VERSION ""

NS_ :

BS_:

BU_: Turbocharger OnBoardDataLogger OffBoardDiagnosticTool2 OffBoardDiagnosticTool1 FileServer ParkingBrakeController SeatControl2 FanDriveController SteeringColumnUnit CommunicationUnitRadio CommunicationUnitSatellite CommunicationUnitCellular PropulsionBatteryCharger ChassisController2 ChassisController1 EngineValveControl AuxiliaryHeater2 AuxiliaryHeater1 ClutchUnit RampControl InformationSystem1 SuspensionSystemController2 OilSensor VehicleDynamicStability ExhaustEmissionController TransmissionDisplay2 TransmissionDisplay1 ClimateControl2 WaterPumpController RearAxleSteeringController LightingOperatorControl SeatController1 IgnitionController2 IgnitionController1 TirePressureController CabController2 CabController1 PneumaticSystemController SuspensionSystemController1 HydraulicPumpController EnduranceBrakingSystem RetarderExhaustEngine2 OnBoardDiagnosticUnit HeadwayController RetarderExhaustEngine1 CabDisplay1 ManagementComputer VirtualTerminal OffVehicleGateway PowerTakeOffFront HitchControl AuxiliaryValveControl BodyController TractorTrailerBridge1 StarterSystem ElectricalSystem VehicleSecurity VehicleNavigation AerodynamicControl ElectricalChargingSystem ClimateControl1 TripRecorder InstrumentCluster SuspensionDriveAxle2 SuspensionDriveAxle1 SuspensionSteerAxle SteeringController FuelSystem CruiseControl RetarderDriveline RetarderEngine BrakesDriveAxle2 BrakesDriveAxle1 BrakesSystemController BrakesSteerAxle AxleDrive2 AxleDrive1 AxleSteering PowerTakeOff ShiftConsoleSecondary ShiftConsolePrimary Transmission2 Transmission1 Engine2 Engine1

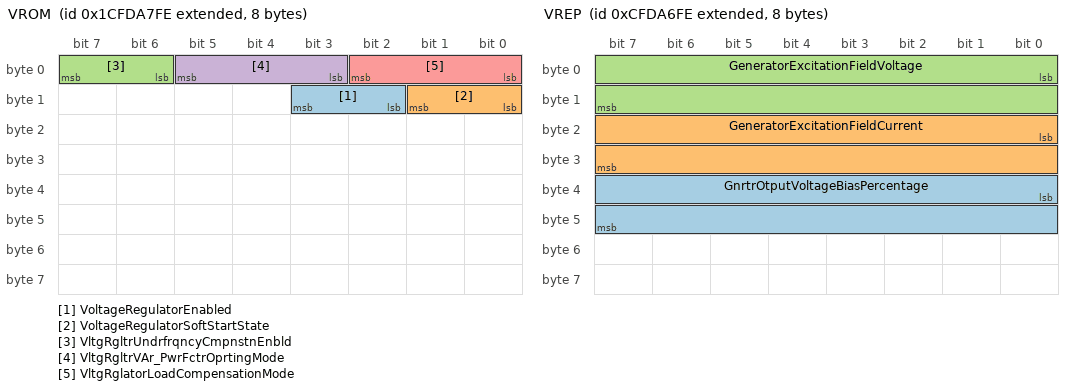
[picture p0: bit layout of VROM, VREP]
BO_ 2633869310 VROM: 8 Vector__XXX
 SG_ VoltageRegulatorEnabled : 10|2@1+ (1,0) [0|3] "" Vector__XXX
 SG_ VoltageRegulatorSoftStartState : 8|2@1+ (1,0) [0|3] "" Vector__XXX
 SG_ VltgRgltrUndrfrqncyCmpnstnEnbld : 6|2@1+ (1,0) [0|3] "" Vector__XXX
 SG_ VltgRgltrVAr_PwrFctrOprtingMode : 3|3@1+ (1,0) [0|7] "" Vector__XXX
 SG_ VltgRglatorLoadCompensationMode : 0|3@1+ (1,0) [0|7] "" Vector__XXX

BO_ 2365433598 VREP: 8 Vector__XXX
 SG_ GnrtrOtputVoltageBiasPercentage : 32|16@1+ (0.1,-100) [-100|100] "%" Vector__XXX
 SG_ GeneratorExcitationFieldCurrent : 16|16@1+ (0.05,0) [0|3217.5] "A" Vector__XXX
 SG_ GeneratorExcitationFieldVoltage : 0|16@1+ (0.05,-1605.625) [-1605.625|1606.375] "V" Vector__XXX

CM_ BO_ 3221225472 "This is a message for not used signals, created by Vector CANdb++ DBC OLE DB Provider.";
CM_ SG_ 3221225472 TrailerWeight "Total mass of freight-carrying vehicle designed to be pulled by truck, including the weight of the contents.";
CM_ SG_ 3221225472 ReferenceTirePressSetting "Reference value of the tire pressure setting as basis for the tire pressure monitoring";
CM_ SG_ 3221225472 ReferenceTirePress "Reference value of the tire pressure as basis for the tire pressure monitoring";
CM_ SG_ 3221225472 TirePressThresholdDetection "Signal indicating the pressure level of the tire.";
CM_ SG_ 3221225472 TireAirLeakageRate "The pressure loss rate of a tire.";
CM_ SG_ 3221225472 CTIWheelEndElectricalFault "Indicates the status of electrical fault on CTI wheel interface.";
CM_ SG_ 3221225472 CTITireStatus "Indicates the status of the tire.";
CM_ SG_ 3221225472 CTIWheelSensorStatus "Indicates whether the wheel is being monitored by the CTI controller.";
CM_ SG_ 3221225472 TireTemp "Temperature at the surface of the tire sidewall.";
CM_ SG_ 3221225472 TirePress "Pressure at which air is contained in cavity formed by tire and rim.";
CM_ BO_ 2633832958 "Ignitor Loop Information";
CM_ SG_ 2633832958 SpecialIgnitorLoop90Resistance "Resistance of Special Ignitor Loop 90.";
CM_ SG_ 2633832958 SpecialIgnitorLoop89Resistance "Resistance of Special Ignitor Loop 89.";
CM_ SG_ 2633832958 SpecialIgnitorLoop88Resistance "Resistance of Special Ignitor Loop 88.";
CM_ SG_ 2633832958 SpecialIgnitorLoop87Resistance "Resistance of Special Ignitor Loop 87.";
CM_ SG_ 2633832958 SpecialIgnitorLoop86Resistance "Resistance of Special Ignitor Loop 86.";
CM_ SG_ 2633832958 SpecialIgnitorLoop85Resistance "Resistance of Special Ignitor Loop 85.";
CM_ SG_ 2633832958 SpecialIgnitorLoop84Resistance "Resistance of Special Ignitor Loop 84.";
CM_ SG_ 2633832958 SpecialIgnitorLoop83Resistance "Resistance of Special Ignitor Loop 83.";
CM_ SG_ 2633832958 SpecialIgnitorLoop82Resistance "Resistance of Special Ignitor Loop 82.";
CM_ SG_ 2633832958 SpecialIgnitorLoop81Resistance "Resistance of Special Ignitor Loop 81.";
CM_ SG_ 2633832958 SpecialIgnitorLoop80Resistance "Resistance of Special Ignitor Loop 80.";
CM_ SG_ 2633832958 SpecialIgnitorLoop79Resistance "Resistance of Special Ignitor Loop 79.";
CM_ SG_ 2633832958 SpecialIgnitorLoop78Resistance "Resistance of Special Ignitor Loop 78.";
CM_ SG_ 2633832958 SpecialIgnitorLoop77Resistance "Resistance of Special Ignitor Loop 77.";
CM_ SG_ 2633832958 SpecialIgnitorLoop76Resistance "Resistance of Special Ignitor Loop 76.";
CM_ SG_ 2633832958 SpecialIgnitorLoop75Resistance "Resistance of Special Ignitor Loop 75.";
CM_ SG_ 2633832958 SpecialIgnitorLoop74Resistance "Resistance of Special Ignitor Loop 74.";
CM_ SG_ 2633832958 SpecialIgnitorLoop73Resistance "Resistance of Special Ignitor Loop 73.";
CM_ SG_ 2633832958 SpecialIgnitorLoop72Resistance "Resistance of Special Ignitor Loop 72.";
CM_ SG_ 2633832958 SpecialIgnitorLoop71Resistance "Resistance of Special Ignitor Loop 71.";
CM_ SG_ 2633832958 SpecialIgnitorLoop70Resistance "Resistance of Special Ignitor Loop 70.";
CM_ SG_ 2633832958 SpecialIgnitorLoop69Resistance "Resistance of Special Ignitor Loop 69.";
CM_ SG_ 2633832958 SpecialIgnitorLoop68Resistance "Resistance of Special Ignitor Loop 68.";
CM_ SG_ 2633832958 SpecialIgnitorLoop67Resistance "Resistance of Special Ignitor Loop 67.";
CM_ SG_ 2633832958 SpecialIgnitorLoop66Resistance "Resistance of Special Ignitor Loop 66.";
CM_ SG_ 2633832958 SpecialIgnitorLoop65Resistance "Resistance of Special Ignitor Loop 65.";
CM_ SG_ 2633832958 SpecialIgnitorLoop64Resistance "Resistance of Special Ignitor Loop 64.";
CM_ SG_ 2633832958 SpecialIgnitorLoop63Resistance "Resistance of Special Ignitor Loop 63.";
CM_ SG_ 2633832958 SpecialIgnitorLoop61Resistance "Resistance of Special Ignitor Loop 61.";
CM_ SG_ 2633832958 SpecialIgnitorLoop60Resistance "Resistance of Special Ignitor Loop 60.";
CM_ SG_ 2633832958 SpecialIgnitorLoop59Resistance "Resistance of Special Ignitor Loop 59.";
CM_ SG_ 2633832958 SpecialIgnitorLoop58Resistance "Resistance of Special Ignitor Loop 58.";
CM_ SG_ 2633832958 SpecialIgnitorLoop57Resistance "Resistance of Special Ignitor Loop 57.";
CM_ SG_ 2633832958 SpecialIgnitorLoop56Resistance "Resistance of Special Ignitor Loop 56.";
CM_ SG_ 2633832958 SpecialIgnitorLoop55Resistance "Resistance of Special Ignitor Loop 55.";
CM_ SG_ 2633832958 SpecialIgnitorLoop54Resistance "Resistance of Special Ignitor Loop 54.";
CM_ SG_ 2633832958 SpecialIgnitorLoop53Resistance "Resistance of Special Ignitor Loop 53.";
CM_ SG_ 2633832958 SpecialIgnitorLoop52Resistance "Resistance of Special Ignitor Loop 52.";
CM_ SG_ 2633832958 SpecialIgnitorLoop51Resistance "Resistance of Special Ignitor Loop 51.";
CM_ SG_ 2633832958 SpecialIgnitorLoop50Resistance "Resistance of Special Ignitor Loop 50.";
CM_ SG_ 2633832958 SpecialIgnitorLoop49Resistance "Resistance of Special Ignitor Loop 49.";
CM_ SG_ 2633832958 SpecialIgnitorLoop48Resistance "Resistance of Special Ignitor Loop 48.";
CM_ SG_ 2633832958 SpecialIgnitorLoop47Resistance "Resistance of Special Ignitor Loop 47.";
CM_ SG_ 2633832958 SpecialIgnitorLoop46Resistance "Resistance of Special Ignitor Loop 46.";
CM_ SG_ 2633832958 SpecialIgnitorLoop45Resistance "Resistance of Special Ignitor Loop 45.";
CM_ SG_ 2633832958 SpecialIgnitorLoop44Resistance "Resistance of Special Ignitor Loop 44.";
CM_ SG_ 2633832958 SpecialIgnitorLoop43Resistance "Resistance of Special Ignitor Loop 43.";
CM_ SG_ 2633832958 SpecialIgnitorLoop42Resistance "Resistance of Special Ignitor Loop 42.";
CM_ SG_ 2633832958 SpecialIgnitorLoop41Resistance "Resistance of Special Ignitor Loop 41.";
CM_ SG_ 2633832958 SpecialIgnitorLoop40Resistance "Resistance of Special Ignitor Loop 40.";
CM_ SG_ 2633832958 SpecialIgnitorLoop39Resistance "Resistance of Special Ignitor Loop 39.";
CM_ SG_ 2633832958 SpecialIgnitorLoop38Resistance "Resistance of Special Ignitor Loop 38.";
CM_ SG_ 2633832958 SpecialIgnitorLoop37Resistance "Resistance of Special Ignitor Loop 37.";
CM_ SG_ 2633832958 SpecialIgnitorLoop36Resistance "Resistance of Special Ignitor Loop 36.";
CM_ SG_ 2633832958 SpecialIgnitorLoop35Resistance "Resistance of Special Ignitor Loop 35.";
CM_ SG_ 2633832958 SpecialIgnitorLoop34Resistance "Resistance of Special Ignitor Loop 34.";
CM_ SG_ 2633832958 SpecialIgnitorLoop33Resistance "Resistance of Special Ignitor Loop 33.";
CM_ SG_ 2633832958 SpecialIgnitorLoop32Resistance "Resistance of Special Ignitor Loop 32.";
CM_ SG_ 2633832958 SpecialIgnitorLoop31Resistance "Resistance of Special Ignitor Loop 31.";
CM_ SG_ 2633832958 SpecialIgnitorLoop30Resistance "Resistance of Special Ignitor Loop 30.";
CM_ SG_ 2633832958 SpecialIgnitorLoop29Resistance "Resistance of Special Ignitor Loop 29.";
CM_ SG_ 2633832958 SpecialIgnitorLoop28Resistance "Resistance of Special Ignitor Loop 28.";
CM_ SG_ 2633832958 SpecialIgnitorLoop27Resistance "Resistance of Special Ignitor Loop 27.";
CM_ SG_ 2633832958 SpecialIgnitorLoop26Resistance "Resistance of Special Ignitor Loop 26.";
CM_ SG_ 2633832958 SpecialIgnitorLoop25Resistance "Resistance of Special Ignitor Loop 25.";
CM_ SG_ 2633832958 SpecialIgnitorLoop24Resistance "Resistance of Special Ignitor Loop 24.";
CM_ SG_ 2633832958 SpecialIgnitorLoop23Resistance "Resistance of Special Ignitor Loop 23.";
CM_ SG_ 2633832958 SpecialIgnitorLoop22Resistance "Resistance of Special Ignitor Loop 22.";
CM_ SG_ 2633832958 SpecialIgnitorLoop21Resistance "Resistance of Special Ignitor Loop 21.";
CM_ SG_ 2633832958 SpecialIgnitorLoop20Resistance "Resistance of Special Ignitor Loop 20.";
CM_ SG_ 2633832958 SpecialIgnitorLoop19Resistance "Resistance of Special Ignitor Loop 19.";
CM_ SG_ 2633832958 SpecialIgnitorLoop18Resistance "Resistance of Special Ignitor Loop 18.";
CM_ SG_ 2633832958 SpecialIgnitorLoop17Resistance "Resistance of Special Ignitor Loop 17.";
CM_ SG_ 2633832958 SpecialIgnitorLoop16Resistance "Resistance of Special Ignitor Loop 16.";
CM_ SG_ 2633832958 SpecialIgnitorLoop15Resistance "Resistance of Special Ignitor Loop 15.";
CM_ SG_ 2633832958 SpecialIgnitorLoop14Resistance "Resistance of Special Ignitor Loop 14.";
CM_ SG_ 2633832958 SpecialIgnitorLoop13Resistance "Resistance of Special Ignitor Loop 13.";
CM_ SG_ 2633832958 SpecialIgnitorLoop12Resistance "Resistance of Special Ignitor Loop 12.";
CM_ SG_ 2633832958 SpecialIgnitorLoop11Resistance "Resistance of Special Ignitor Loop 11.";
CM_ SG_ 2633832958 SpecialIgnitorLoop10Resistance "Resistance of Special Ignitor Loop 10.";
CM_ SG_ 2633832958 SpecialIgnitorLoop9Resistance "Resistance of Special Ignitor Loop 9.";
CM_ SG_ 2633832958 SpecialIgnitorLoop8Resistance "Resistance of Special Ignitor Loop 8.";
CM_ SG_ 2633832958 SpecialIgnitorLoop7Resistance "Resistance of Special Ignitor Loop 7.";
CM_ SG_ 2633832958 SpecialIgnitorLoop6Resistance "Resistance of Special Ignitor Loop 6.";
CM_ SG_ 2633832958 SpecialIgnitorLoop5Resistance "Resistance of Special Ignitor Loop 5.";
CM_ SG_ 2633832958 SpecialIgnitorLoop4Resistance "Resistance of Special Ignitor Loop 4.";
CM_ SG_ 2633832958 SpecialIgnitorLoop3Resistance "Resistance of Special Ignitor Loop 3.";
CM_ SG_ 2633832958 SpecialIgnitorLoop2Resistance "Resistance of Special Ignitor Loop 2.";
CM_ SG_ 2633832958 SpecialIgnitorLoop1Resistance "Resistance of Special Ignitor Loop 1.";
CM_ SG_ 2633832958 SdBgIgnitorLoop2RightResistance "Resistance of Side Bag Ignitor Loop 2 - Right.";
CM_ SG_ 2633832958 SdBgIgnitorLoop1RightResistance "Resistance of Side Bag Ignitor Loop 1 - Right.";
CM_ SG_ 2633832958 SdBagIgnitorLoop2LeftResistance "Resistance of Side Bag Ignitor Loop 2 - Left.";
CM_ SG_ 2633832958 SdBagIgnitorLoop1LeftResistance "Resistance of Side Bag Ignitor Loop 1 - Left.";
CM_ SG_ 2633832958 PssngrBltTnsnrIgntrLpResistance "Resistance of Passenger Belt Tensioner Ignitor Loop 1st Stage.";
CM_ SG_ 2633832958 DrvrBltTnsnrIgntrLoopResistance "Resistance of Driver Belt Tensioner Ignitor Loop 1st Stage.";
CM_ SG_ 2633832958 PssngrArbgIgntrLp2ndStgRsstance "Resistance of Passenger Airbag Ignitor Loop 2nd Stage.";
CM_ SG_ 2633832958 DrvrArbgIgntrLp2ndStgResistance "Resistance of Driver Airbag Ignitor Loop 2nd Stage.";
CM_ SG_ 2633832958 PssngrArbgIgntrLp1stStgRsstance "Resistance of Passenger Airbag Ignitor Loop 1st Stage.";
CM_ SG_ 2633832958 DrvrArbgIgntrLp1stStgResistance "Resistance of Driver Airbag Ignitor Loop 1st Stage.";
CM_ BO_ 2633938942 "Engine Speed/Load Factor Information";
CM_ SG_ 2633938942 TotalEngCruiseTime "Total time that the engine has operated in the cruise hold state, excluding time in accelerator override, over the life of the engine.";
CM_ SG_ 2633938942 TotalDriveAverageLoadFactor "Average engine load factor while engine speed is greater than zero, vehicle speed is greater than or equal to 2 km/h, and";
CM_ SG_ 2633938942 TripDriveAverageLoadFactor "Average engine load factor while engine speed is greater than zero, vehicle speed is greater than or equal to 2 km/h, and";
CM_ SG_ 2633938942 TripAverageEngSpeed "Average speed of the engine since the last trip reset.";
CM_ SG_ 2633938942 TripMaxEngSpeed "Maximum engine speed achieved since the last trip reset.";
CM_ BO_ 2633939198 "Trip Fuel Information (Gaseous)";
CM_ SG_ 2633939198 TripDriveFuelEconomy "Trip drive fuel economy is equal to the distance traveled by vehicle in the drive state (engine speed greater than zero,";
CM_ SG_ 2633939198 TrpPTOGovernorNonmovingFuelUsed "Total fuel consumed while the PTO or remote PTO governors are in the hold state, the engine speed is greater than zero,";
CM_ SG_ 2633939198 TripVehicleIdleFuelUsed "Total fuel consumed while neither the PTO or remote PTO governors are active, the engine speed is greater than zero,";
CM_ SG_ 2633939198 TripCruiseFuelUsed "Total fuel consumed while the engine is in the cruise hold state since the last trip reset.";
CM_ SG_ 2633939198 TripDriveFuelUsed "Total fuel consumed while the engine speed is greater than zero, vehicle speed is greater than or equal to 2 km/h, and";
CM_ SG_ 2633939198 TripPTOGovernorMovingFuelUsed "Total fuel consumed while either the PTO or remote PTO governors are in the hold state, the engine speed is greater";
CM_ BO_ 2564554494 "Reserved for ISO 15765";
CM_ SG_ 2564554494 ProtocolCtrlInformation "Part of Network Protocol Control Information (N_PCI) of a ISO 15765 message.";
CM_ BO_ 2564488958 "Reserved for ISO 15765";
CM_ SG_ 2564488958 ProtocolCtrlInformation "Part of Network Protocol Control Information (N_PCI) of a ISO 15765 message.";
CM_ BO_ 2633937150 "Trip Time Information 2";
CM_ SG_ 2633937150 TripAirCompressorOnTime "Total time that the air compressor is on and compressing air since the last trip reset.";
CM_ SG_ 2633937150 TripIdleTime "Total time accumulated while the engine speed is greater than zero, both the PTO and remote PTO governors are";
CM_ SG_ 2633937150 TripEngRunningTime "Total time accumulated while the engine speed is greater than zero since the last trip reset.";
CM_ SG_ 2633937150 TripCruiseTime "Total time accumulated while the engine is in the cruise hold state, excluding time in accelerator override, since the last trip reset.";
CM_ SG_ 2633937150 TripPTOGovernorTime "Total time accumulated while the engine is in the PTO or remote PTO governor hold state since the last trip reset.";
CM_ BO_ 2633938174 "Trip Time Information 1";
CM_ SG_ 2633938174 TripTimeInDerateByEng "Total time accumulated when the engine final fueling has been derated due to an engine protection algorithm, since the last reset.";
CM_ SG_ 2633938174 TripTimeInGearDown "Total time accumulated when the vehicle has operated in one gear down from the top gear for a calibrated minimum time,";
CM_ SG_ 2633938174 TripTimeInTopGear "Total time accumulated when the vehicle has operated in top gear for a calibrated minimum time, since the last trip reset.";
CM_ SG_ 2633938174 TripTimeInVSL "Total time accumulated when the engine has operated on the vehicle speed limiter (VSL) while not in the cruise hold";
CM_ BO_ 2566765822 "Farebox Service Detail";
CM_ SG_ 2566765822 DriversFareboxSecurityCode "Security code for the farebox, numerical only.";
CM_ SG_ 2566765822 AssignedBlock "The agency defined block number for this trip";
CM_ SG_ 2566765822 AssignedRun "The agency defined run number for this trip";
CM_ SG_ 2566765822 AssignedRoute "The identity number assigned to this route.";
CM_ SG_ 2566765822 PatternNumber "The agency defined pattern number for this trip";
CM_ SG_ 2566765822 TripNumber "The identity number assigned to this trip.";
CM_ SG_ 2566765822 FarePresets "Fare Presets";
CM_ SG_ 2566765822 TripDirection "The general direction of travel for this trip.";
CM_ SG_ 2566765822 TripStatus "Trip Status";
CM_ SG_ 2566765822 FareboxServiceStatus "Indicates if the farebox is in or out of service.";
CM_ BO_ 2633939966 "Trip Fan Information";
CM_ SG_ 2633939966 TripFanOnTimeDueToAManualSwitch "Total time the fan has been on due to manual activation by the operator (i.";
CM_ SG_ 2633939966 TripFanOnTime "Total time the fan has been on (due to an automatic trigger or manual trigger) since the last trip reset.";
CM_ SG_ 2633939966 TripFanOnTimeDueToA_CSystem "Total time the fan has been on due to the A/C system since the last trip reset.";
CM_ SG_ 2633939966 TripFanOnTimeDueToEngSystem "Total time the fan has been on due to engine triggers (i.";
CM_ BO_ 2633939710 "Trip Distance Information";
CM_ SG_ 2633939710 TripDistanceInTopGear "Total distance accumulated while the vehicle has operated in top gear for a calibrated minimum time since the last trip reset.";
CM_ SG_ 2633939710 TripGearDownDistance "Total distance accumulated while the vehicle has operated in the gear which is one gear down from top gear and exceeds";
CM_ SG_ 2633939710 TripDistanceOnVSL "Total distance accumulated while the engine torque mode is road speed governing since the last trip reset.";
CM_ BO_ 2566840830 "Retarder Configuration";
CM_ SG_ 2566840830 PercentTorqueAtPeakTorquePoint5 "The torque limit that indicates the available retarder torque which can be provided by the retarder at point 5 of the retarder";
CM_ SG_ 2566840830 ReferenceRetarderTorque "This parameter is the 100% reference value for all defined indicated retarder torque parameters.";
CM_ SG_ 2566840830 RetarderSpeedAtPeakTorquePoint5 "Please reference PGN 65249";
CM_ SG_ 2566840830 PercentTorqueAtPoint4 "The torque limit that indicates the available retarder torque which can be provided by the retarder at points 3 and 4 of the";
CM_ SG_ 2566840830 RetarderSpeedAtPoint4 "Retarder speed of point 4 of the engine retarder torque map.";
CM_ SG_ 2566840830 PercentTorqueAtPoint3 "The torque limit that indicates the available retarder torque which can be provided by the retarder at points 3 and 4 of the";
CM_ SG_ 2566840830 RetarderSpeedAtPoint3 "Retarder speed of point 3 of the engine retarder torque map.";
CM_ SG_ 2566840830 PercentTorqueAtMaxSpeedPoint2 "The torque limit that indicates the available retarder torque which can be provided by the retarder at its maximum speed.";
CM_ SG_ 2566840830 MaxRetarderSpeedPoint2 "Maximum speed of retarder (Please reference PGN 65249).";
CM_ SG_ 2566840830 PercentTorqueAtIdlePoint1 "The torque limit that indicates the available retarder torque which can be provided by the retarder at idle speed.";
CM_ SG_ 2566840830 RetarderSpeedAtIdlePoint1 "Please reference PGN 65249";
CM_ SG_ 2566840830 RetarderCtrlMethod "This parameter identifies the number of steps used by the retarder.";
CM_ SG_ 2566840830 RetarderLocation "This parameter defines whether the [torque/speed curve] defined by the retarder configuration message (PGN 65249) is";
CM_ SG_ 2566840830 RetarderType "A vehicle retarder is a supplementary device to the wheel brakes for the driver to better control the vehicle.";
CM_ BO_ 2633939454 "Trip Fuel Information (Liquid)";
CM_ SG_ 2633939454 TripCruiseFuelUsed "Total fuel consumed while the engine is in the cruise hold state since the last trip reset.";
CM_ SG_ 2633939454 TripVehicleIdleFuelUsed "Total fuel consumed while neither the PTO or remote PTO governor is in the hold state, the engine speed is greater than";
CM_ SG_ 2633939454 TripDriveFuelUsed "Total fuel consumed while the engine speed is greater than zero, vehicle speed is greater than or equal to 2 km/h, and";
CM_ SG_ 2633939454 TrpPTOGovernorNonmovingFuelUsed "Total fuel consumed while either the PTO or remote PTO governors are in the hold state, the engine speed is greater";
CM_ SG_ 2633939454 TripPTOGovernorMovingFuelUsed "Total fuel consumed while either the PTO or remote PTO governors are in the hold state, the engine speed is greater";
CM_ SG_ 2633939454 TripDriveFuelEconomy "Trip drive fuel economy is equal to the distance traveled by vehicle in the drive state (engine speed greater than zero,";
CM_ BO_ 2566820094 "Engine Torque History";
CM_ SG_ 2566820094 EngTorqueLimit6AxleInput "Limit applied to the engine output torque based on the maximum allowable axle input torque.";
CM_ SG_ 2566820094 EngTorqueLimit5Switch "Limit applied to the engine output torque based on activation of an ECU switch input.";
CM_ SG_ 2566820094 EngTorqueLimit4Trans "Limit applied to the engine output torque during vehicle operation in transmission gear ratios numerically less than or";
CM_ SG_ 2566820094 EngTorqueLimit3Trans "Limit applied to the engine output torque during vehicle operation in transmission gear ratios numerically less than or";
CM_ SG_ 2566820094 TransGearRatio3 "Gear ratio value stored in the ECU that is used to define a range of transmission gears for which a limit is applied to the";
CM_ SG_ 2566820094 EngTorqueLimit2Trans "Limit applied to the engine output torque during vehicle operation in transmission gear ratios numerically less than or";
CM_ SG_ 2566820094 TransGearRatio2 "Gear ratio value stored in the ECU that is used to define a range of transmission gears for which a limit is applied to the";
CM_ SG_ 2566820094 EngTorqueLimit1Trans "Limit applied to the engine output torque during vehicle operation in transmission gear ratios numerically greater than";
CM_ SG_ 2566820094 TransGearRatio1 "Gear ratio value stored in the ECU that is used to define a range of transmission gears for which a limit is applied to the";
CM_ SG_ 2566820094 EngTorqueLimitFeature "Torque limit rating described in the current record.";
CM_ SG_ 2566820094 TorqueLimitingFeatureStatus "Status of an ECU feature which limits the torque output of the engine.";
CM_ SG_ 2566820094 CalibRecordDurationTime "Duration in hours for which the engine operated in the conditions captured in the current record.";
CM_ SG_ 2566820094 CalibRecordStartYear "Calendar year timestamp when an ECU record was established.";
CM_ SG_ 2566820094 CalibRecordStartDay "Calendar day timestamp when an ECU record was established.";
CM_ SG_ 2566820094 CalibRecordStartMonth "Calendar month timestamp when an ECU record was established.";
CM_ SG_ 2566820094 EngPeakTorque2 "Maximum torque output of the current ECU calibration when the engine operates on torque curve 2.";
CM_ SG_ 2566820094 EngPeakTorque1 "Maximum torque output of the current ECU calibration when the engine operates on torque curve 1.";
CM_ SG_ 2566820094 EngPower "Advertised engine power capability.";
CM_ SG_ 2566820094 NumberOfEngTorqueHistoryRecords "Number of torque history records contained in the engine torque history PGN.";
CM_ BO_ 2566841342 "Engine Configuration 1";
CM_ SG_ 2566841342 SupportTSC1CtrlPurposeGroup4 "This parameter indicates which TSC1 control purposes are supported in group 4 of 4.";
CM_ SG_ 2566841342 SupportTSC1CtrlPurposeGroup3 "This parameter indicates which TSC1 control purposes are supported in group 3 of 4.";
CM_ SG_ 2566841342 SupportTSC1CtrlPurposeGroup2 "This parameter indicates which TSC1 control purposes are supported in group 2 of 4.";
CM_ SG_ 2566841342 SupportTSC1CtrlPurposeGroup1 "This parameter indicates which TSC1 control purposes are supported in group 1 of 4.";
CM_ SG_ 2566841342 SupportVariableRateTSC1Message "This parameter indicates which TSC1 transmission rates are supported by the engine ECU in addition to the required";
CM_ SG_ 2566841342 EngDefaultTorqueLimit "Companion parameter to Transmission Torque Limit (SPN 1845).";
CM_ SG_ 2566841342 EngMomentOfInertia "Moment of inertia for the engine, including items driven full-time by the engine such as fuel, oil and cooling pumps.";
CM_ SG_ 2566841342 EngExRngRqdSpdCtrlRngUpperLimit "The maximum engine speed regardless of load that the engine will allow when operating in a speed control/limit mode,";
CM_ SG_ 2566841342 EngRqdTorqueCtrlRangeUpperLimit "The maximum engine torque that the engine will allow when operating in a torque control/limit mode.";
CM_ SG_ 2566841342 EngRqdTorqueCtrlRangeLowerLimit "The minimum engine torque that the engine will allow when operating in a torque control/limit mode.";
CM_ SG_ 2566841342 EngRqedSpeedCtrlRangeUpperLimit "The maximum engine speed regardless of load that the engine will allow when operating in a speed control/limit mode,";
CM_ SG_ 2566841342 EngRqedSpeedCtrlRangeLowerLimit "The minimum engine speed that the engine will allow when operating in a speed control/limit mode.";
CM_ SG_ 2566841342 EngMxMomentaryOverrideTimeLimit "The maximum time limit allowed to override the engine's high idle speed.";
CM_ SG_ 2566841342 EngMxMmntaryOverrideSpeedPoint7 "The maximum engine speed above high idle allowed by the engine control during a momentary high idle override.";
CM_ SG_ 2566841342 EngReferenceTorque "This parameter is the 100% reference value for all defined indicated engine torque parameters.";
CM_ SG_ 2566841342 EngSpeedAtHighIdlePoint6 "Engine speed of high idle (point 6) of the engine torque map (see PGN 65251 and supporting document).";
CM_ SG_ 2566841342 EngGainOfEndspeedGovernor "The endspeed governor is defined as a linear line with the following equations (Capital letters mean physical values, small";
CM_ SG_ 2566841342 EngPercentTorqueAtPoint5 "The torque limit that indicates the available engine torque which can be provided by the engine at point 3, 4, and 5 of the";
CM_ SG_ 2566841342 EngSpeedAtPoint5 "Engine speed of point 3, 4, and 5 of the engine torque map (see PGN 65251 and supporting document).";
CM_ SG_ 2566841342 EngPercentTorqueAtPoint4 "The torque limit that indicates the available engine torque which can be provided by the engine at point 3, 4, and 5 of the";
CM_ SG_ 2566841342 EngSpeedAtPoint4 "Engine speed of point 3, 4, and 5 of the engine torque map (see PGN 65251 and supporting document).";
CM_ SG_ 2566841342 EngPercentTorqueAtPoint3 "The torque limit that indicates the available engine torque which can be provided by the engine at point 3, 4, and 5 of the";
CM_ SG_ 2566841342 EngSpeedAtPoint3 "Engine speed of point 3, 4, and 5 of the engine torque map (see PGN 65251 and supporting document).";
CM_ SG_ 2566841342 EngPercentTorqueAtPoint2 "The torque limit that indicates the available engine torque which can be provided by the engine at point 2 of the engine";
CM_ SG_ 2566841342 EngSpeedAtPoint2 "Engine speed of point 2 of the engine torque map (see PGN 65251 and supporting document).";
CM_ SG_ 2566841342 EngPercentTorqueAtIdlePoint1 "The torque limit that indicates the available engine torque which can be provided by the engine at idle speed.";
CM_ SG_ 2566841342 EngSpeedAtIdlePoint1 "Stationary low idle speed of engine which includes influences due to engine temperature (after power up) and other";
CM_ BO_ 2633940222 "Compression/Service Brake Information";
CM_ SG_ 2633940222 TripServiceBrakeApps "Total number of times the service brakes have been activated since the last trip reset.";
CM_ SG_ 2633940222 TripServiceBrakeDistance "Total distance over which the service brakes have been active since the last trip reset.";
CM_ SG_ 2633940222 TripCompressionBrakeDistance "Total distance over which the compression brakes have been active since the last trip reset.";
CM_ SG_ 2633940222 TotalCompressionBrakeDistance "Total distance over which the compression brakes have been active for the life of the engine.";
CM_ BO_ 2292317950 "The total engine run time while each of the Emission Increasing Auxiliary Emission Control Devices is active";
CM_ SG_ 2292317950 AECDEngineHours1Timer2 "The total engine running hours recorded in the second timer for the EI-AECD";
CM_ SG_ 2292317950 AECDEngineHours1Timer1 "The total engine running hours recorded in the first timer for the EI-AECD";
CM_ SG_ 2292317950 AECDNumber1 "The manufacturer assigned number for the specific EI-AECD";
CM_ BO_ 2566756606 "Aftertreatment 1 Historical Information";
CM_ SG_ 2566756606 Aftrtrtmnt1TtlNmbrOfActvRgnrtnMn "Total number of aftertreatment device 1 active regeneration manual requests by the operator over the lifetime of the";
CM_ SG_ 2566756606 Aftrtrtmnt1TtlNmbrOfActvRgnrtnIn "Total number of aftertreatment device 1 active regeneration inhibit requests by the operator over the lifetime of the device.";
CM_ SG_ 2566756606 Aftrtrtmnt1AvrgTmBtwnActvRgnrtns "Indicates the average time since last reset between active regenerations, that have not been forced to occur by manual";
CM_ SG_ 2566756606 Aftrtrtmnt1TtlNmbrOfPssvRgnrtns "Total number of passive regenerations by aftertreatment device 1 over the lifetime of the device.";
CM_ SG_ 2566756606 Aftrtrtmnt1TtlPssvRgnrationTime "Total amount of time that aftertreatment device 1 has been in passive regeneration over the lifetime of the device.";
CM_ SG_ 2566756606 Aftrtrtmnt1TtlNmbrOfActvRgnrtns "Total number of active regenerations by aftertreatment device 1 over the lifetime of the device.";
CM_ SG_ 2566756606 Aftrtreatment1TotalDisabledTime "Total amount of time that aftertreatment 1 regeneration has been manually disabled.";
CM_ SG_ 2566756606 Aftrtrtmnt1TtalRegenerationTime "Total amount of time that aftertreatment device 1 has been regenerating over the lifetime of the device.";
CM_ SG_ 2566756606 Aftertreatment1TotalFuelUsed "Total amount of fuel used by aftertreatment device 1 over the lifetime of the device.";
CM_ BO_ 2560950014 "This message conveys the scaled test results for the applicable test requested in DM7.";
CM_ SG_ 2560950014 TestLimitMinimum "The test value must be greater than or equal to Test Limit Minimum in order for the test to pass";
CM_ SG_ 2560950014 TestLimitMaximum "The test value must be less than or equal to Test Limit Maximum in order for the test to pass.";
CM_ SG_ 2560950014 TestValue "The test value collected during the test.";
CM_ SG_ 2560950014 SlotId "The SLOT Identifer is used to determine the multiplier and offset to be used to scale the test value.";
CM_ SG_ 2560950014 TestIdentifier "Test Identifier";
CM_ SG_ 2560950014 FailureModeIdentifier1 "The FMI defines the type of failure detected in the subsystem identified by an SPN.";
CM_ SG_ 2560950014 SPN1High "SPN #1 (Conversion Version 4)";
CM_ SG_ 2560950014 SPN1 "SPN #1 (Conversion Version 4)";
CM_ BO_ 2566748670 "Aftertreatment 1 Trip Information";
CM_ SG_ 2566748670 Aftrtrtmnt1TrpNmbrOfActvRgnrtnMn "Total number of Aftertreatment device 1 active regeneration manual requests by the operator during the current trip";
CM_ SG_ 2566748670 Aftrtrtmnt1TrpNmbrOfActvRgnrtnIn "Total number of aftertreatment device 1 active regeneration inhibit requests by the operator during the current trip period.";
CM_ SG_ 2566748670 Aftrtrtmnt1TrpNmbrOfPssvRgnrtns "Total number of passive regenerations by Aftertreatment device 1 during the current trip period.";
CM_ SG_ 2566748670 Aftrtrtmnt1TrpPssvRgnrationTime "Total amount of time that aftertreatment device 1 has been in passive regeneration during the current trip period.";
CM_ SG_ 2566748670 Aftrtrtmnt1TrpNmbrOfActvRgnrtns "Total number of active regenerations by Aftertreatment device 1 during the current trip period.";
CM_ SG_ 2566748670 Aftertreatment1TripDisabledTime "Total amount of time that aftertreatment 1 regeneration has been manually disabled during the current trip period.";
CM_ SG_ 2566748670 Aftrtrtmnt1TrpActvRgnrationTime "Total amount of time that aftertreatment device 1 has been in active regeneration during the current trip period.";
CM_ SG_ 2566748670 Aftertreatment1TripFuelUsed "Total amount of fuel used by aftertreatment device 1 during the current trip period.";
CM_ BO_ 2566756862 "Aftertreatment 2 Historical information";
CM_ SG_ 2566756862 Aftrtrtmnt2TtlNmbrOfActvRgnrtnMn "Total number of Aftertreatment device 2 active regeneration manual requests by the operator over the lifetime of the";
CM_ SG_ 2566756862 Aftrtrtmnt2TtlNmbrOfActvRgnrtnIn "Total number of Aftertreatment device 2 active regeneration inhibit requests by the operator over the lifetime of the";
CM_ SG_ 2566756862 Aftrtrtmnt2AvrgTmBtwnActvRgnrtns "Indicates the average time since last reset between active regenerations, that have not been forced to occur by manual";
CM_ SG_ 2566756862 Aftrtrtmnt2TtlNmbrOfPssvRgnrtns "Total number of passive regenerations by Aftertreatment device 2 over the lifetime of the device.";
CM_ SG_ 2566756862 Aftrtrtmnt2TtlPssvRgnrationTime "Total amount of time that Aftertreatment device 2 has been in passive regeneration over the lifetime of the device.";
CM_ SG_ 2566756862 Aftrtrtmnt2TtlNmbrOfActvRgnrtns "Total number of active regenerations by aftertreatment device 2 over the lifetime of the device.";
CM_ SG_ 2566756862 Aftrtreatment2TotalDisabledTime "Total amount of time that aftertreatment 2 regeneration has been manually disabled.";
CM_ SG_ 2566756862 Aftrtrtmnt2TtalRegenerationTime "Total amount of time that aftertreatment device 2 has been regenerating over the lifetime of the device.";
CM_ SG_ 2566756862 Aftertreatment2TotalFuelUsed "Total amount of fuel used by aftertreatment device 2 over the lifetime of the device.";
CM_ BO_ 2566748414 "Aftertreatment 2 Trip Information";
CM_ SG_ 2566748414 Aftrtrtmnt2TrpNmbrOfActvRgnrtnMn "Total number of aftertreatment device 2 active regeneration manual requests by the operator during the current trip";
CM_ SG_ 2566748414 Aftrtrtmnt2TrpNmbrOfActvRgnrtnIn "Total number of aftertreatment device 2 active regeneration inhibit requests by the operator during the current trip period.";
CM_ SG_ 2566748414 Aftrtrtmnt2TrpNmbrOfPssvRgnrtns "Total number of passive regenerations by aftertreatment device 2 during the current trip period.";
CM_ SG_ 2566748414 Aftrtrtmnt2TrpPssvRgnrationTime "Total amount of time that aftertreatment device 2 has been in passive regeneration during the current trip period.";
CM_ SG_ 2566748414 Aftrtrtmnt2TrpNmbrOfActvRgnrtns "Total number of active regenerations by aftertreatment device 2 during the current trip period.";
CM_ SG_ 2566748414 Aftertreatment2TripDisabledTime "Total amount of time that aftertreatment 2 regeneration has been manually disabled during the current trip period.";
CM_ SG_ 2566748414 Aftrtrtmnt2TrpActvRgnrationTime "Total amount of time that aftertreatment device 2 has been in active regeneration during the current trip period.";
CM_ SG_ 2566748414 Aftertreatment2TripFuelUsed "Total amount of fuel used by aftertreatment device 2 during the current trip period.";
CM_ BO_ 2566836222 "Pending DTCs";
CM_ SG_ 2566836222 FlashRedStopLamp "This parameter provides the capability to flash the RSL (SPN 3039).";
CM_ SG_ 2566836222 FlashProtectLamp "This parameter provides the capability to flash the engine protect lamp (SPN 3041).";
CM_ SG_ 2566836222 FlashMalfuncIndicatorLamp "This parameter provides the capability to flash the MIL (SPN 3038).";
CM_ SG_ 2566836222 FlashAmberWarningLamp "This parameter provides the capability to flash the AWL (SPN 3040). ";
CM_ SG_ 2566836222 MalfunctionIndicatorLampStatus "A lamp used to relay only emissions-related trouble code information.";
CM_ SG_ 2566836222 RedStopLampState "This lamp is uesed to relay trouble code information that is of a severe enought condition that it warrants stopping the vehicle.";
CM_ SG_ 2566836222 AmberWarningLampStatus "This lamp is used to relay trouble code information that is reporting a problem with the vehicle system but the vehicle need
not be immediately stopped.";
CM_ SG_ 2566836222 ProtectLampStatus "This lamp is used to relay trouble code informatio that is reporting a problem with a vehicle system that is most
probably not electronic subsystem related.";
CM_ SG_ 2566836222 DTC5 "Diagnostic Trouble Code";
CM_ SG_ 2566836222 DTC4 "Diagnostic Trouble Code";
CM_ SG_ 2566836222 DTC3 "Diagnostic Trouble Code";
CM_ SG_ 2566836222 DTC2 "Diagnostic Trouble Code";
CM_ SG_ 2566836222 DTC1 "Diagnostic Trouble Code";
CM_ BO_ 2566835710 "Freeze frame parameters";
CM_ SG_ 2566835710 EngIntakeManifold1Press "The gage pressure measurement of the air intake manifold.";
CM_ SG_ 2566835710 FreezeFrameLength "The freeze frame length shall be equal to the number of bytes in the required parameters plus the number of bytes in the
manufacturer specific parameters.";
CM_ SG_ 2566835710 EngSpeed "Actual engine speed which is calculated over a minimum crankshaft angle of 720 degrees divided by the number of cylinders.";
CM_ SG_ 2566835710 EngTorqueMode "State signal which indicates which engine torque mode is currently generating, limiting, or controlling the torque.";
CM_ SG_ 2566835710 WheelBasedVehicleSpeed "Speed of the vehicle as calculated from wheel or tailshaft speed.";
CM_ SG_ 2566835710 EngPercentLoadAtCurrentSpeed "The ratio of actual engine percent torque (indicated) to maximum indicated torque available at the current engine speed,";
CM_ SG_ 2566835710 DTC1 "Diagnostic Trouble Code";
CM_ BO_ 2566764542 "Expanded freeze frame.";
CM_ SG_ 2566764542 ExpandedFreezeFrameLength "The freeze frame length shall be equal to the number of bytes in the required parameters plus the number of bytes in the
manufacturer specific parameters.";
CM_ SG_ 2566764542 DTC1 "Diagnostic Trouble Code";
CM_ BO_ 2566764286 "SPN Support. This message is used to identify those SPNs supported by the product for freeze frames and data stream messages.";
CM_ SG_ 2566764286 SPNSupported1High "This parameter defines the SPN(s) that is/are supported for the freeze frame and/or data stream information.";
CM_ SG_ 2566764286 SPNSupportTypeSTR3 "This parameter defines whether the applicable parameter (that is the SPN) is supported in the freeze frame, the data stream or both the freeze frame and data stream.";
CM_ SG_ 2566764286 SPNSupportTypeSTR2 "This parameter defines whether the applicable parameter (that is the SPN) is supported in the freeze frame, the data stream or both the freeze frame and data stream.";
CM_ SG_ 2566764286 SPNSupportTypeEFF3 "This parameter defines whether the applicable parameter (that is the SPN) is supported in the freeze frame, the data stream or both the freeze frame and data stream.";
CM_ SG_ 2566764286 SPNSupportTypeEFF2 "This parameter defines whether the applicable parameter (that is the SPN) is supported in the freeze frame, the data stream or both the freeze frame and data stream.";
CM_ SG_ 2566764286 SPNSupportTypeDS3 "This parameter defines whether the applicable parameter (that is the SPN) is supported in the freeze frame, the data stream or both the freeze frame and data stream.";
CM_ SG_ 2566764286 SPNSupportTypeDS2 "This parameter defines whether the applicable parameter (that is the SPN) is supported in the freeze frame, the data stream or both the freeze frame and data stream.";
CM_ SG_ 2566764286 SPNSupported3High "This parameter defines the SPN(s) that is/are supported for the freeze frame and/or data stream information.";
CM_ SG_ 2566764286 SPNSupported2High "This parameter defines the SPN(s) that is/are supported for the freeze frame and/or data stream information.";
CM_ SG_ 2566764286 SPNSupported3 "This parameter defines the SPN(s) that is/are supported for the freeze frame and/or data stream information.";
CM_ SG_ 2566764286 SPNSupported2 "This parameter defines the SPN(s) that is/are supported for the freeze frame and/or data stream information.";
CM_ SG_ 2566764286 SPNDataLength3 "The number of data bytes associated with the SPN in the Freeze Frame.";
CM_ SG_ 2566764286 SPNSupportTypeSTR1 "This parameter defines whether the applicable parameter (that is the SPN) is supported in the freeze frame, the data stream or both the freeze frame and data stream.";
CM_ SG_ 2566764286 SPNSupportTypeDS1 "This parameter defines whether the applicable parameter (that is the SPN) is supported in the freeze frame, the data stream or both the freeze frame and data stream.";
CM_ SG_ 2566764286 SPNSupportTypeEFF1 "This parameter defines whether the applicable parameter (that is the SPN) is supported in the freeze frame, the data stream or both the freeze frame and data stream.";
CM_ SG_ 2566764286 SPNDataLength2 "The number of data bytes associated with the SPN in the Freeze Frame.";
CM_ SG_ 2566764286 SPNDataLength1 "The number of data bytes associated with the SPN in the Freeze Frame.";
CM_ SG_ 2566764286 SPNSupported1 "This parameter defines the SPN(s) that is/are supported for the freeze frame and/or data stream information.";
CM_ BO_ 2566764030 "Previously active emission related faults.";
CM_ SG_ 2566764030 FlashRedStopLamp "This parameter provides the capability to flash the RSL (SPN 3039).";
CM_ SG_ 2566764030 FlashProtectLamp "This parameter provides the capability to flash the engine protect lamp (SPN 3041).";
CM_ SG_ 2566764030 FlashMalfuncIndicatorLamp "This parameter provides the capability to flash the MIL (SPN 3038).";
CM_ SG_ 2566764030 FlashAmberWarningLamp "This parameter provides the capability to flash the AWL (SPN 3040). ";
CM_ SG_ 2566764030 MalfunctionIndicatorLampStatus "A lamp used to relay only emissions-related trouble code information.";
CM_ SG_ 2566764030 RedStopLampState "This lamp is uesed to relay trouble code information that is of a severe enought condition that it warrants stopping the vehicle.";
CM_ SG_ 2566764030 AmberWarningLampStatus "This lamp is used to relay trouble code information that is reporting a problem with the vehicle system but the vehicle need
not be immediately stopped.";
CM_ SG_ 2566764030 ProtectLampStatus "This lamp is used to relay trouble code informatio that is reporting a problem with a vehicle system that is most
probably not electronic subsystem related.";
CM_ SG_ 2566764030 DTC5 "Diagnostic Trouble Code";
CM_ SG_ 2566764030 DTC4 "Diagnostic Trouble Code";
CM_ SG_ 2566764030 DTC3 "Diagnostic Trouble Code";
CM_ SG_ 2566764030 DTC2 "Diagnostic Trouble Code";
CM_ SG_ 2566764030 DTC1 "Diagnostic Trouble Code";
CM_ BO_ 2562916094 "Monitor Performance Ratio";
CM_ SG_ 2562916094 ApplSysMonitorDenominator "The number of times a vehicle has been operated that constitutes a driving cycle where this Applicable System Monitor could be operated per regulatory requirements (SPN 3068).";
CM_ SG_ 2562916094 ApplSysMonitorNumerator "The number of times a vehicle has been operated such that all conditions necessary for the Applicable System Monitor to detect a malfunction have been encountered (SPN 3067).";
CM_ SG_ 2562916094 SPNofApplSysMonitor "Contain the SPN of the system monitor for which Monitor ratio is being reported (SPN 3066).";
CM_ SG_ 2562916094 OBDMonitoringCondEncountered "Displays the number of times that the vehicle has been operated in the specified OBD monitoring conditions (SPN 3049).";
CM_ SG_ 2562916094 IgnitionCycleCounter "A single counter that defines the number of ignition cycles (SPN 3048).";
CM_ BO_ 2566835198 "Previously active diagnostic trouble codes";
CM_ SG_ 2566835198 MalfunctionIndicatorLampStatus "A lamp used to relay only emissions-related trouble code information.";
CM_ SG_ 2566835198 RedStopLampState "This lamp is uesed to relay trouble code information that is of a severe enought condition that it warrants stopping the vehicle.";
CM_ SG_ 2566835198 AmberWarningLampStatus "This lamp is used to relay trouble code information that is reporting a problem with the vehicle system but the vehicle need
not be immediately stopped.";
CM_ SG_ 2566835198 ProtectLampStatus "This lamp is used to relay trouble code informatio that is reporting a problem with a vehicle system that is most
probably not electronic subsystem related.";
CM_ SG_ 2566835198 FlashRedStopLamp "This parameter provides the capability to flash the RSL (SPN 3039).";
CM_ SG_ 2566835198 FlashProtectLamp "This parameter provides the capability to flash the engine protect lamp (SPN 3041).";
CM_ SG_ 2566835198 FlashMalfuncIndicatorLamp "This parameter provides the capability to flash the MIL (SPN 3038).";
CM_ SG_ 2566835198 FlashAmberWarningLamp "This parameter provides the capability to flash the AWL (SPN 3040). ";
CM_ SG_ 2566835198 DTC5 "Diagnostic Trouble Code";
CM_ SG_ 2566835198 DTC4 "Diagnostic Trouble Code";
CM_ SG_ 2566835198 DTC3 "Diagnostic Trouble Code";
CM_ SG_ 2566835198 DTC2 "Diagnostic Trouble Code";
CM_ SG_ 2566835198 DTC1 "Diagnostic Trouble Code";
CM_ BO_ 2564030206 "Calibration Information";
CM_ BO_ 2566837502 "Emissions-related active diagnostic trouble codes.";
CM_ SG_ 2566837502 FlashRedStopLamp "This parameter provides the capability to flash the RSL (SPN 3039).";
CM_ SG_ 2566837502 FlashProtectLamp "This parameter provides the capability to flash the engine protect lamp (SPN 3041).";
CM_ SG_ 2566837502 MalfunctionIndicatorLampStatus "A lamp used to relay only emissions-related trouble code information.";
CM_ SG_ 2566837502 RedStopLampState "This lamp is uesed to relay trouble code information that is of a severe enought condition that it warrants stopping the vehicle.";
CM_ SG_ 2566837502 AmberWarningLampStatus "This lamp is used to relay trouble code information that is reporting a problem with the vehicle system but the vehicle need
not be immediately stopped.";
CM_ SG_ 2566837502 ProtectLampStatus "This lamp is used to relay trouble code informatio that is reporting a problem with a vehicle system that is most
probably not electronic subsystem related.";
CM_ SG_ 2566837502 FlashMalfuncIndicatorLamp "This parameter provides the capability to flash the MIL (SPN 3038).";
CM_ SG_ 2566837502 FlashAmberWarningLamp "This parameter provides the capability to flash the AWL (SPN 3040). ";
CM_ SG_ 2566837502 DTC5 "Diagnostic Trouble Code";
CM_ SG_ 2566837502 DTC4 "Diagnostic Trouble Code";
CM_ SG_ 2566837502 DTC3 "Diagnostic Trouble Code";
CM_ SG_ 2566837502 DTC2 "Diagnostic Trouble Code";
CM_ SG_ 2566837502 DTC1 "Diagnostic Trouble Code";
CM_ BO_ 2566834942 "Active diagnostic trouble codes";
CM_ SG_ 2566834942 FlashRedStopLamp "This parameter provides the capability to flash the RSL (SPN 3039).";
CM_ SG_ 2566834942 FlashProtectLamp "This parameter provides the capability to flash the engine protect lamp (SPN 3041).";
CM_ SG_ 2566834942 FlashMalfuncIndicatorLamp "This parameter provides the capability to flash the MIL (SPN 3038).";
CM_ SG_ 2566834942 FlashAmberWarningLamp "This parameter provides the capability to flash the AWL (SPN 3040). ";
CM_ SG_ 2566834942 MalfunctionIndicatorLampStatus "A lamp used to relay only emissions-related trouble code information.";
CM_ SG_ 2566834942 AmberWarningLampStatus "This lamp is used to relay trouble code information that is reporting a problem with the vehicle system but the vehicle need
not be immediately stopped.";
CM_ SG_ 2566834942 RedStopLampState "This lamp is uesed to relay trouble code information that is of a severe enought condition that it warrants stopping the vehicle.";
CM_ SG_ 2566834942 ProtectLampStatus "This lamp is used to relay trouble code informatio that is reporting a problem with a vehicle system that is most
probably not electronic subsystem related.";
CM_ SG_ 2566834942 DTC5 "Diagnostic Trouble Code";
CM_ SG_ 2566834942 DTC4 "Diagnostic Trouble Code";
CM_ SG_ 2566834942 DTC3 "Diagnostic Trouble Code";
CM_ SG_ 2566834942 DTC2 "Diagnostic Trouble Code";
CM_ SG_ 2566834942 DTC1 "Diagnostic Trouble Code";
CM_ BO_ 2566838526 "Commanded Address";
CM_ SG_ 2566838526 AddressAssignment "The source address that is to be assigned to the CA that has the NAME corresponding to the one conveyed in the first eight bytes of this Commanded Address message.";
CM_ SG_ 2566838526 IndustryGroup "0 = Global; 
   1  = On-Highway; 
   2  = Agricultural and Forestry; 
   3  = Construction; 
   4  = Marine;
   5  = Industrial - Process
          Control - Stationary (Gen-Sets)
   6  = Reserve for SAE
   7  = Reserve for SAE";
CM_ SG_ 2566838526 ManufacturerCode "Assigned by NMEA 2000 Committee";
CM_ BO_ 2565799678 "Address Claimed";
CM_ SG_ 2565799678 IndustryGroup "0 = Global; 
   1  = On-Highway; 
   2  = Agricultural and Forestry; 
   3  = Construction; 
   4  = Marine;
   5  = Industrial - Process
          Control - Stationary (Gen-Sets)
   6  = Reserve for SAE
   7  = Reserve for SAE";
CM_ SG_ 2565799678 ManufacturerCode "Assigned by NMEA 2000 Committee";
CM_ BO_ 2566739198 "Class C, Previously Active";
CM_ SG_ 2566739198 FlashRedStopLamp "This parameter provides the capability to flash the RSL (SPN 3039).";
CM_ SG_ 2566739198 FlashProtectLamp "This parameter provides the capability to flash the engine protect lamp (SPN 3041).";
CM_ SG_ 2566739198 FlashMalfuncIndicatorLamp "This parameter provides the capability to flash the MIL (SPN 3038).";
CM_ SG_ 2566739198 FlashAmberWarningLamp "This parameter provides the capability to flash the AWL (SPN 3040). ";
CM_ SG_ 2566739198 MalfunctionIndicatorLampStatus "A lamp used to relay only emissions-related trouble code information.";
CM_ SG_ 2566739198 AmberWarningLampStatus "This lamp is used to relay trouble code information that is reporting a problem with the vehicle system but the vehicle need
not be immediately stopped.";
CM_ SG_ 2566739198 RedStopLampState "This lamp is uesed to relay trouble code information that is of a severe enought condition that it warrants stopping the vehicle.";
CM_ SG_ 2566739198 ProtectLampStatus "This lamp is used to relay trouble code informatio that is reporting a problem with a vehicle system that is most
probably not electronic subsystem related.";
CM_ SG_ 2566739198 DTC5 "Diagnostic Trouble Code";
CM_ SG_ 2566739198 DTC4 "Diagnostic Trouble Code";
CM_ SG_ 2566739198 DTC3 "Diagnostic Trouble Code";
CM_ SG_ 2566739198 DTC2 "Diagnostic Trouble Code";
CM_ SG_ 2566739198 DTC1 "Diagnostic Trouble Code";
CM_ BO_ 2566739454 "Class C, Confirmed and Active";
CM_ SG_ 2566739454 FlashRedStopLamp "This parameter provides the capability to flash the RSL (SPN 3039).";
CM_ SG_ 2566739454 FlashProtectLamp "This parameter provides the capability to flash the engine protect lamp (SPN 3041).";
CM_ SG_ 2566739454 FlashMalfuncIndicatorLamp "This parameter provides the capability to flash the MIL (SPN 3038).";
CM_ SG_ 2566739454 FlashAmberWarningLamp "This parameter provides the capability to flash the AWL (SPN 3040). ";
CM_ SG_ 2566739454 MalfunctionIndicatorLampStatus "A lamp used to relay only emissions-related trouble code information.";
CM_ SG_ 2566739454 AmberWarningLampStatus "This lamp is used to relay trouble code information that is reporting a problem with the vehicle system but the vehicle need
not be immediately stopped.";
CM_ SG_ 2566739454 RedStopLampState "This lamp is uesed to relay trouble code information that is of a severe enought condition that it warrants stopping the vehicle.";
CM_ SG_ 2566739454 ProtectLampStatus "This lamp is used to relay trouble code informatio that is reporting a problem with a vehicle system that is most
probably not electronic subsystem related.";
CM_ SG_ 2566739454 DTC5 "Diagnostic Trouble Code";
CM_ SG_ 2566739454 DTC4 "Diagnostic Trouble Code";
CM_ SG_ 2566739454 DTC3 "Diagnostic Trouble Code";
CM_ SG_ 2566739454 DTC2 "Diagnostic Trouble Code";
CM_ SG_ 2566739454 DTC1 "Diagnostic Trouble Code";
CM_ BO_ 2566739710 "Class C, Pending";
CM_ SG_ 2566739710 FlashRedStopLamp "This parameter provides the capability to flash the RSL (SPN 3039).";
CM_ SG_ 2566739710 FlashProtectLamp "This parameter provides the capability to flash the engine protect lamp (SPN 3041).";
CM_ SG_ 2566739710 FlashMalfuncIndicatorLamp "This parameter provides the capability to flash the MIL (SPN 3038).";
CM_ SG_ 2566739710 FlashAmberWarningLamp "This parameter provides the capability to flash the AWL (SPN 3040). ";
CM_ SG_ 2566739710 MalfunctionIndicatorLampStatus "A lamp used to relay only emissions-related trouble code information.";
CM_ SG_ 2566739710 AmberWarningLampStatus "This lamp is used to relay trouble code information that is reporting a problem with the vehicle system but the vehicle need
not be immediately stopped.";
CM_ SG_ 2566739710 RedStopLampState "This lamp is uesed to relay trouble code information that is of a severe enought condition that it warrants stopping the vehicle.";
CM_ SG_ 2566739710 ProtectLampStatus "This lamp is used to relay trouble code informatio that is reporting a problem with a vehicle system that is most
probably not electronic subsystem related.";
CM_ SG_ 2566739710 DTC5 "Diagnostic Trouble Code";
CM_ SG_ 2566739710 DTC4 "Diagnostic Trouble Code";
CM_ SG_ 2566739710 DTC3 "Diagnostic Trouble Code";
CM_ SG_ 2566739710 DTC2 "Diagnostic Trouble Code";
CM_ SG_ 2566739710 DTC1 "Diagnostic Trouble Code";
CM_ BO_ 2566739966 "Class B2, Previously Active";
CM_ SG_ 2566739966 FlashRedStopLamp "This parameter provides the capability to flash the RSL (SPN 3039).";
CM_ SG_ 2566739966 FlashProtectLamp "This parameter provides the capability to flash the engine protect lamp (SPN 3041).";
CM_ SG_ 2566739966 FlashMalfuncIndicatorLamp "This parameter provides the capability to flash the MIL (SPN 3038).";
CM_ SG_ 2566739966 FlashAmberWarningLamp "This parameter provides the capability to flash the AWL (SPN 3040). ";
CM_ SG_ 2566739966 MalfunctionIndicatorLampStatus "A lamp used to relay only emissions-related trouble code information.";
CM_ SG_ 2566739966 AmberWarningLampStatus "This lamp is used to relay trouble code information that is reporting a problem with the vehicle system but the vehicle need
not be immediately stopped.";
CM_ SG_ 2566739966 RedStopLampState "This lamp is uesed to relay trouble code information that is of a severe enought condition that it warrants stopping the vehicle.";
CM_ SG_ 2566739966 ProtectLampStatus "This lamp is used to relay trouble code informatio that is reporting a problem with a vehicle system that is most
probably not electronic subsystem related.";
CM_ SG_ 2566739966 DTC5 "Diagnostic Trouble Code";
CM_ SG_ 2566739966 DTC4 "Diagnostic Trouble Code";
CM_ SG_ 2566739966 DTC3 "Diagnostic Trouble Code";
CM_ SG_ 2566739966 DTC2 "Diagnostic Trouble Code";
CM_ SG_ 2566739966 DTC1 "Diagnostic Trouble Code";
CM_ BO_ 2566740222 "Class B2, Confirmed and Active";
CM_ SG_ 2566740222 FlashRedStopLamp "This parameter provides the capability to flash the RSL (SPN 3039).";
CM_ SG_ 2566740222 FlashProtectLamp "This parameter provides the capability to flash the engine protect lamp (SPN 3041).";
CM_ SG_ 2566740222 FlashMalfuncIndicatorLamp "This parameter provides the capability to flash the MIL (SPN 3038).";
CM_ SG_ 2566740222 FlashAmberWarningLamp "This parameter provides the capability to flash the AWL (SPN 3040). ";
CM_ SG_ 2566740222 MalfunctionIndicatorLampStatus "A lamp used to relay only emissions-related trouble code information.";
CM_ SG_ 2566740222 AmberWarningLampStatus "This lamp is used to relay trouble code information that is reporting a problem with the vehicle system but the vehicle need
not be immediately stopped.";
CM_ SG_ 2566740222 RedStopLampState "This lamp is uesed to relay trouble code information that is of a severe enought condition that it warrants stopping the vehicle.";
CM_ SG_ 2566740222 ProtectLampStatus "This lamp is used to relay trouble code informatio that is reporting a problem with a vehicle system that is most
probably not electronic subsystem related.";
CM_ SG_ 2566740222 DTC5 "Diagnostic Trouble Code";
CM_ SG_ 2566740222 DTC4 "Diagnostic Trouble Code";
CM_ SG_ 2566740222 DTC3 "Diagnostic Trouble Code";
CM_ SG_ 2566740222 DTC2 "Diagnostic Trouble Code";
CM_ SG_ 2566740222 DTC1 "Diagnostic Trouble Code";
CM_ BO_ 2566740478 "Class B2, Pending";
CM_ SG_ 2566740478 FlashRedStopLamp "This parameter provides the capability to flash the RSL (SPN 3039).";
CM_ SG_ 2566740478 FlashProtectLamp "This parameter provides the capability to flash the engine protect lamp (SPN 3041).";
CM_ SG_ 2566740478 FlashMalfuncIndicatorLamp "This parameter provides the capability to flash the MIL (SPN 3038).";
CM_ SG_ 2566740478 FlashAmberWarningLamp "This parameter provides the capability to flash the AWL (SPN 3040). ";
CM_ SG_ 2566740478 MalfunctionIndicatorLampStatus "A lamp used to relay only emissions-related trouble code information.";
CM_ SG_ 2566740478 AmberWarningLampStatus "This lamp is used to relay trouble code information that is reporting a problem with the vehicle system but the vehicle need
not be immediately stopped.";
CM_ SG_ 2566740478 RedStopLampState "This lamp is uesed to relay trouble code information that is of a severe enought condition that it warrants stopping the vehicle.";
CM_ SG_ 2566740478 ProtectLampStatus "This lamp is used to relay trouble code informatio that is reporting a problem with a vehicle system that is most
probably not electronic subsystem related.";
CM_ SG_ 2566740478 DTC5 "Diagnostic Trouble Code";
CM_ SG_ 2566740478 DTC4 "Diagnostic Trouble Code";
CM_ SG_ 2566740478 DTC3 "Diagnostic Trouble Code";
CM_ SG_ 2566740478 DTC2 "Diagnostic Trouble Code";
CM_ SG_ 2566740478 DTC1 "Diagnostic Trouble Code";
CM_ BO_ 2566740734 "Class B1, Previously Active";
CM_ SG_ 2566740734 FlashRedStopLamp "This parameter provides the capability to flash the RSL (SPN 3039).";
CM_ SG_ 2566740734 FlashProtectLamp "This parameter provides the capability to flash the engine protect lamp (SPN 3041).";
CM_ SG_ 2566740734 FlashMalfuncIndicatorLamp "This parameter provides the capability to flash the MIL (SPN 3038).";
CM_ SG_ 2566740734 FlashAmberWarningLamp "This parameter provides the capability to flash the AWL (SPN 3040). ";
CM_ SG_ 2566740734 MalfunctionIndicatorLampStatus "A lamp used to relay only emissions-related trouble code information.";
CM_ SG_ 2566740734 AmberWarningLampStatus "This lamp is used to relay trouble code information that is reporting a problem with the vehicle system but the vehicle need
not be immediately stopped.";
CM_ SG_ 2566740734 RedStopLampState "This lamp is uesed to relay trouble code information that is of a severe enought condition that it warrants stopping the vehicle.";
CM_ SG_ 2566740734 ProtectLampStatus "This lamp is used to relay trouble code informatio that is reporting a problem with a vehicle system that is most
probably not electronic subsystem related.";
CM_ SG_ 2566740734 DTC5 "Diagnostic Trouble Code";
CM_ SG_ 2566740734 DTC4 "Diagnostic Trouble Code";
CM_ SG_ 2566740734 DTC3 "Diagnostic Trouble Code";
CM_ SG_ 2566740734 DTC2 "Diagnostic Trouble Code";
CM_ SG_ 2566740734 DTC1 "Diagnostic Trouble Code";
CM_ BO_ 2566740990 "Class B1, Confirmed and Active";
CM_ SG_ 2566740990 FlashRedStopLamp "This parameter provides the capability to flash the RSL (SPN 3039).";
CM_ SG_ 2566740990 FlashProtectLamp "This parameter provides the capability to flash the engine protect lamp (SPN 3041).";
CM_ SG_ 2566740990 FlashMalfuncIndicatorLamp "This parameter provides the capability to flash the MIL (SPN 3038).";
CM_ SG_ 2566740990 FlashAmberWarningLamp "This parameter provides the capability to flash the AWL (SPN 3040). ";
CM_ SG_ 2566740990 MalfunctionIndicatorLampStatus "A lamp used to relay only emissions-related trouble code information.";
CM_ SG_ 2566740990 AmberWarningLampStatus "This lamp is used to relay trouble code information that is reporting a problem with the vehicle system but the vehicle need
not be immediately stopped.";
CM_ SG_ 2566740990 RedStopLampState "This lamp is uesed to relay trouble code information that is of a severe enought condition that it warrants stopping the vehicle.";
CM_ SG_ 2566740990 ProtectLampStatus "This lamp is used to relay trouble code informatio that is reporting a problem with a vehicle system that is most
probably not electronic subsystem related.";
CM_ SG_ 2566740990 DTC5 "Diagnostic Trouble Code";
CM_ SG_ 2566740990 DTC4 "Diagnostic Trouble Code";
CM_ SG_ 2566740990 DTC3 "Diagnostic Trouble Code";
CM_ SG_ 2566740990 DTC2 "Diagnostic Trouble Code";
CM_ SG_ 2566740990 DTC1 "Diagnostic Trouble Code";
CM_ BO_ 2566741246 "Class B1, Pending";
CM_ SG_ 2566741246 FlashRedStopLamp "This parameter provides the capability to flash the RSL (SPN 3039).";
CM_ SG_ 2566741246 FlashProtectLamp "This parameter provides the capability to flash the engine protect lamp (SPN 3041).";
CM_ SG_ 2566741246 FlashMalfuncIndicatorLamp "This parameter provides the capability to flash the MIL (SPN 3038).";
CM_ SG_ 2566741246 FlashAmberWarningLamp "This parameter provides the capability to flash the AWL (SPN 3040). ";
CM_ SG_ 2566741246 MalfunctionIndicatorLampStatus "A lamp used to relay only emissions-related trouble code information.";
CM_ SG_ 2566741246 AmberWarningLampStatus "This lamp is used to relay trouble code information that is reporting a problem with the vehicle system but the vehicle need
not be immediately stopped.";
CM_ SG_ 2566741246 RedStopLampState "This lamp is uesed to relay trouble code information that is of a severe enought condition that it warrants stopping the vehicle.";
CM_ SG_ 2566741246 ProtectLampStatus "This lamp is used to relay trouble code informatio that is reporting a problem with a vehicle system that is most
probably not electronic subsystem related.";
CM_ SG_ 2566741246 DTC5 "Diagnostic Trouble Code";
CM_ SG_ 2566741246 DTC4 "Diagnostic Trouble Code";
CM_ SG_ 2566741246 DTC3 "Diagnostic Trouble Code";
CM_ SG_ 2566741246 DTC2 "Diagnostic Trouble Code";
CM_ SG_ 2566741246 DTC1 "Diagnostic Trouble Code";
CM_ BO_ 2566741502 "Class A, Previously Active";
CM_ SG_ 2566741502 FlashRedStopLamp "This parameter provides the capability to flash the RSL (SPN 3039).";
CM_ SG_ 2566741502 FlashProtectLamp "This parameter provides the capability to flash the engine protect lamp (SPN 3041).";
CM_ SG_ 2566741502 FlashMalfuncIndicatorLamp "This parameter provides the capability to flash the MIL (SPN 3038).";
CM_ SG_ 2566741502 FlashAmberWarningLamp "This parameter provides the capability to flash the AWL (SPN 3040). ";
CM_ SG_ 2566741502 MalfunctionIndicatorLampStatus "A lamp used to relay only emissions-related trouble code information.";
CM_ SG_ 2566741502 AmberWarningLampStatus "This lamp is used to relay trouble code information that is reporting a problem with the vehicle system but the vehicle need
not be immediately stopped.";
CM_ SG_ 2566741502 RedStopLampState "This lamp is uesed to relay trouble code information that is of a severe enought condition that it warrants stopping the vehicle.";
CM_ SG_ 2566741502 ProtectLampStatus "This lamp is used to relay trouble code informatio that is reporting a problem with a vehicle system that is most
probably not electronic subsystem related.";
CM_ SG_ 2566741502 DTC5 "Diagnostic Trouble Code";
CM_ SG_ 2566741502 DTC4 "Diagnostic Trouble Code";
CM_ SG_ 2566741502 DTC3 "Diagnostic Trouble Code";
CM_ SG_ 2566741502 DTC2 "Diagnostic Trouble Code";
CM_ SG_ 2566741502 DTC1 "Diagnostic Trouble Code";
CM_ BO_ 2566741758 "Class A, Confirmed and Active";
CM_ SG_ 2566741758 FlashRedStopLamp "This parameter provides the capability to flash the RSL (SPN 3039).";
CM_ SG_ 2566741758 FlashProtectLamp "This parameter provides the capability to flash the engine protect lamp (SPN 3041).";
CM_ SG_ 2566741758 FlashMalfuncIndicatorLamp "This parameter provides the capability to flash the MIL (SPN 3038).";
CM_ SG_ 2566741758 FlashAmberWarningLamp "This parameter provides the capability to flash the AWL (SPN 3040). ";
CM_ SG_ 2566741758 MalfunctionIndicatorLampStatus "A lamp used to relay only emissions-related trouble code information.";
CM_ SG_ 2566741758 AmberWarningLampStatus "This lamp is used to relay trouble code information that is reporting a problem with the vehicle system but the vehicle need
not be immediately stopped.";
CM_ SG_ 2566741758 RedStopLampState "This lamp is uesed to relay trouble code information that is of a severe enought condition that it warrants stopping the vehicle.";
CM_ SG_ 2566741758 ProtectLampStatus "This lamp is used to relay trouble code informatio that is reporting a problem with a vehicle system that is most
probably not electronic subsystem related.";
CM_ SG_ 2566741758 DTC5 "Diagnostic Trouble Code";
CM_ SG_ 2566741758 DTC4 "Diagnostic Trouble Code";
CM_ SG_ 2566741758 DTC3 "Diagnostic Trouble Code";
CM_ SG_ 2566741758 DTC2 "Diagnostic Trouble Code";
CM_ SG_ 2566741758 DTC1 "Diagnostic Trouble Code";
CM_ BO_ 2566742014 "Class A, Pending";
CM_ SG_ 2566742014 FlashRedStopLamp "This parameter provides the capability to flash the RSL (SPN 3039).";
CM_ SG_ 2566742014 FlashProtectLamp "This parameter provides the capability to flash the engine protect lamp (SPN 3041).";
CM_ SG_ 2566742014 FlashMalfuncIndicatorLamp "This parameter provides the capability to flash the MIL (SPN 3038).";
CM_ SG_ 2566742014 FlashAmberWarningLamp "This parameter provides the capability to flash the AWL (SPN 3040). ";
CM_ SG_ 2566742014 MalfunctionIndicatorLampStatus "A lamp used to relay only emissions-related trouble code information.";
CM_ SG_ 2566742014 AmberWarningLampStatus "This lamp is used to relay trouble code information that is reporting a problem with the vehicle system but the vehicle need
not be immediately stopped.";
CM_ SG_ 2566742014 RedStopLampState "This lamp is uesed to relay trouble code information that is of a severe enought condition that it warrants stopping the vehicle.";
CM_ SG_ 2566742014 ProtectLampStatus "This lamp is used to relay trouble code informatio that is reporting a problem with a vehicle system that is most
probably not electronic subsystem related.";
CM_ SG_ 2566742014 DTC5 "Diagnostic Trouble Code";
CM_ SG_ 2566742014 DTC4 "Diagnostic Trouble Code";
CM_ SG_ 2566742014 DTC3 "Diagnostic Trouble Code";
CM_ SG_ 2566742014 DTC2 "Diagnostic Trouble Code";
CM_ SG_ 2566742014 DTC1 "Diagnostic Trouble Code";
CM_ BO_ 2560622334 "Immediate Fault Status ";
CM_ SG_ 2560622334 FlashRedStopLamp "This parameter provides the capability to flash the RSL (SPN 3039).";
CM_ SG_ 2560622334 FlashProtectLamp "This parameter provides the capability to flash the engine protect lamp (SPN 3041).";
CM_ SG_ 2560622334 FlashMalfuncIndicatorLamp "This parameter provides the capability to flash the MIL (SPN 3038).";
CM_ SG_ 2560622334 FlashAmberWarningLamp "This parameter provides the capability to flash the AWL (SPN 3040). ";
CM_ SG_ 2560622334 MalfunctionIndicatorLampStatus "A lamp used to relay only emissions-related trouble code information.";
CM_ SG_ 2560622334 AmberWarningLampStatus "This lamp is used to relay trouble code information that is reporting a problem with the vehicle system but the vehicle need
not be immediately stopped.";
CM_ SG_ 2560622334 RedStopLampState "This lamp is uesed to relay trouble code information that is of a severe enought condition that it warrants stopping the vehicle.";
CM_ SG_ 2560622334 ProtectLampStatus "This lamp is used to relay trouble code informatio that is reporting a problem with a vehicle system that is most
probably not electronic subsystem related.";
CM_ SG_ 2560622334 DTC5 "Diagnostic Trouble Code";
CM_ SG_ 2560622334 DTC4 "Diagnostic Trouble Code";
CM_ SG_ 2560622334 DTC3 "Diagnostic Trouble Code";
CM_ SG_ 2560622334 DTC2 "Diagnostic Trouble Code";
CM_ SG_ 2560622334 DTC1 "Diagnostic Trouble Code";
CM_ BO_ 2566750462 "Permanent DTCs";
CM_ SG_ 2566750462 FlashRedStopLamp "This parameter provides the capability to flash the RSL (SPN 3039).";
CM_ SG_ 2566750462 FlashProtectLamp "This parameter provides the capability to flash the engine protect lamp (SPN 3041).";
CM_ SG_ 2566750462 FlashMalfuncIndicatorLamp "This parameter provides the capability to flash the MIL (SPN 3038).";
CM_ SG_ 2566750462 FlashAmberWarningLamp "This parameter provides the capability to flash the AWL (SPN 3040). ";
CM_ SG_ 2566750462 MalfunctionIndicatorLampStatus "A lamp used to relay only emissions-related trouble code information.";
CM_ SG_ 2566750462 AmberWarningLampStatus "This lamp is used to relay trouble code information that is reporting a problem with the vehicle system but the vehicle need
not be immediately stopped.";
CM_ SG_ 2566750462 RedStopLampState "This lamp is uesed to relay trouble code information that is of a severe enought condition that it warrants stopping the vehicle.";
CM_ SG_ 2566750462 ProtectLampStatus "This lamp is used to relay trouble code informatio that is reporting a problem with a vehicle system that is most
probably not electronic subsystem related.";
CM_ SG_ 2566750462 DTC5 "Diagnostic Trouble Code";
CM_ SG_ 2566750462 DTC4 "Diagnostic Trouble Code";
CM_ SG_ 2566750462 DTC3 "Diagnostic Trouble Code";
CM_ SG_ 2566750462 DTC2 "Diagnostic Trouble Code";
CM_ SG_ 2566750462 DTC1 "Diagnostic Trouble Code";
CM_ BO_ 2566750974 "All Pending DTCs";
CM_ SG_ 2566750974 FlashRedStopLamp "This parameter provides the capability to flash the RSL (SPN 3039).";
CM_ SG_ 2566750974 FlashProtectLamp "This parameter provides the capability to flash the engine protect lamp (SPN 3041).";
CM_ SG_ 2566750974 FlashMalfuncIndicatorLamp "This parameter provides the capability to flash the MIL (SPN 3038).";
CM_ SG_ 2566750974 FlashAmberWarningLamp "This parameter provides the capability to flash the AWL (SPN 3040). ";
CM_ SG_ 2566750974 MalfunctionIndicatorLampStatus "A lamp used to relay only emissions-related trouble code information.";
CM_ SG_ 2566750974 AmberWarningLampStatus "This lamp is used to relay trouble code information that is reporting a problem with the vehicle system but the vehicle need
not be immediately stopped.";
CM_ SG_ 2566750974 RedStopLampState "This lamp is uesed to relay trouble code information that is of a severe enought condition that it warrants stopping the vehicle.";
CM_ SG_ 2566750974 ProtectLampStatus "This lamp is used to relay trouble code informatio that is reporting a problem with a vehicle system that is most
probably not electronic subsystem related.";
CM_ SG_ 2566750974 DTC5 "Diagnostic Trouble Code";
CM_ SG_ 2566750974 DTC4 "Diagnostic Trouble Code";
CM_ SG_ 2566750974 DTC3 "Diagnostic Trouble Code";
CM_ SG_ 2566750974 DTC2 "Diagnostic Trouble Code";
CM_ SG_ 2566750974 DTC1 "Diagnostic Trouble Code";
CM_ BO_ 2565406462 "Acknowledgment Message";
CM_ SG_ 2565406462 ParameterGroupNumber "PGN which is requested by Request2 message";
CM_ SG_ 2565406462 GroupFunctionValue "Group Function of PGN being acknowledged. This field identifies for a device the specific group function of a PGN being acknowledged or declined.  This field is not used if the PGN being acknowledged or declined is not a group function PGN.";
CM_ BO_ 2633869310 "Voltage Regulator Operating Mode";
CM_ SG_ 2633869310 VoltageRegulatorEnabled "State signal indicating the Voltage regulator enabled.";
CM_ SG_ 2633869310 VoltageRegulatorSoftStartState "State signal indicating the mode of the Voltage regulator soft start function.";
CM_ SG_ 2633869310 VltgRgltrUndrfrqncyCmpnstnEnbld "State signal indicating the operating mode for underfrequency compensation.";
CM_ SG_ 2633869310 VltgRglatorLoadCompensationMode "State signal indicating the voltage regulator load compensation mode.";
CM_ BO_ 2365433598 "Voltage regulator excitation status";
CM_ SG_ 2365433598 GeneratorExcitationFieldCurrent "Measured signal that represents the generator excitation field current.";
CM_ SG_ 2365433598 GeneratorExcitationFieldVoltage "Measured signal that represents the generator excitation field voltage.";
BA_DEF_ SG_  "SigType" ENUM  "Default","Range","RangeSigned","ASCII","Discrete","Control","ReferencePGN","DTC","StringDelimiter","StringLength","StringLengthControl";
BA_DEF_ SG_  "GenSigStartValue" INT 0 10000;
BA_DEF_ SG_  "GenSigSendType" ENUM  "Cyclic","OnWrite","reserved","OnChange","reserved","reserved","reserved","NoSigSendType";
BA_DEF_ SG_  "GenSigILSupport" ENUM  "Yes","No";
BA_DEF_ SG_  "GenSigEVName" STRING ;
BA_DEF_ SG_  "SPN" INT 0 524287;
BA_DEF_ BO_  "GenMsgStartDelayTime" INT 0 100000;
BA_DEF_ BO_  "GenMsgILSupport" ENUM  "Yes","No";
BA_DEF_ BO_  "GenMsgRequestable" INT 0 1;
BA_DEF_ BO_  "GenMsgSendType" ENUM  "cyclic","reserved","cyclicIfActive","reserved","reserved","reserved","reserved","reserved","noMsgSendType";
BA_DEF_ BO_  "VFrameFormat" ENUM  "StandardCAN","ExtendedCAN","reserved","J1939PG";
BA_DEF_ BO_  "GenMsgCycleTime" INT 0 3600000;
BA_DEF_ SG_  "SystemSignalLongSymbol" STRING ;
BA_DEF_DEF_  "SigType" "Default";
BA_DEF_DEF_  "GenSigStartValue" 0;
BA_DEF_DEF_  "GenSigSendType" "NoSigSendType";
BA_DEF_DEF_  "GenSigILSupport" "Yes";
BA_DEF_DEF_  "GenSigEVName" "Env@Nodename_@Signame";
BA_DEF_DEF_  "SPN" 0;
BA_DEF_DEF_  "GenMsgStartDelayTime" 0;
BA_DEF_DEF_  "GenMsgILSupport" "Yes";
BA_DEF_DEF_  "GenMsgRequestable" 1;
BA_DEF_DEF_  "GenMsgSendType" "noMsgSendType";
BA_DEF_DEF_  "VFrameFormat" "J1939PG";
BA_DEF_DEF_  "GenMsgCycleTime" 0;
BA_DEF_DEF_  "SystemSignalLongSymbol" "";
BA_ "GenMsgCycleTime" BO_ 2633869310 1000;
BA_ "GenMsgSendType" BO_ 2633869310 0;
BA_ "GenMsgCycleTime" BO_ 2365433598 100;
BA_ "GenMsgSendType" BO_ 2365433598 0;
BA_ "SPN" SG_ 3221225472 TrailerWeight 180;
BA_ "SigType" SG_ 3221225472 TrailerWeight 1;
BA_ "SPN" SG_ 3221225472 ReferenceTirePressSetting 3193;
BA_ "SigType" SG_ 3221225472 ReferenceTirePressSetting 1;
BA_ "SPN" SG_ 3221225472 ReferenceTirePress 3191;
BA_ "SigType" SG_ 3221225472 ReferenceTirePress 1;
BA_ "SPN" SG_ 3221225472 TirePressThresholdDetection 2587;
BA_ "SigType" SG_ 3221225472 TirePressThresholdDetection 4;
BA_ "SPN" SG_ 3221225472 TireAirLeakageRate 2586;
BA_ "SigType" SG_ 3221225472 TireAirLeakageRate 1;
BA_ "SPN" SG_ 3221225472 CTIWheelEndElectricalFault 1697;
BA_ "SigType" SG_ 3221225472 CTIWheelEndElectricalFault 4;
BA_ "SPN" SG_ 3221225472 CTITireStatus 1698;
BA_ "SigType" SG_ 3221225472 CTITireStatus 4;
BA_ "SPN" SG_ 3221225472 CTIWheelSensorStatus 1699;
BA_ "SigType" SG_ 3221225472 CTIWheelSensorStatus 4;
BA_ "SPN" SG_ 3221225472 TireTemp 242;
BA_ "SigType" SG_ 3221225472 TireTemp 1;
BA_ "SPN" SG_ 3221225472 TirePress 241;
BA_ "SigType" SG_ 3221225472 TirePress 1;
BA_ "SPN" SG_ 2633832958 SpecialIgnitorLoop90Resistance 4917;
BA_ "SigType" SG_ 2633832958 SpecialIgnitorLoop90Resistance 1;
BA_ "SPN" SG_ 2633832958 SpecialIgnitorLoop89Resistance 4916;
BA_ "SigType" SG_ 2633832958 SpecialIgnitorLoop89Resistance 1;
BA_ "SPN" SG_ 2633832958 SpecialIgnitorLoop88Resistance 4915;
BA_ "SigType" SG_ 2633832958 SpecialIgnitorLoop88Resistance 1;
BA_ "SPN" SG_ 2633832958 SpecialIgnitorLoop87Resistance 4914;
BA_ "SigType" SG_ 2633832958 SpecialIgnitorLoop87Resistance 1;
BA_ "SPN" SG_ 2633832958 SpecialIgnitorLoop86Resistance 4913;
BA_ "SigType" SG_ 2633832958 SpecialIgnitorLoop86Resistance 1;
BA_ "SPN" SG_ 2633832958 SpecialIgnitorLoop85Resistance 4912;
BA_ "SigType" SG_ 2633832958 SpecialIgnitorLoop85Resistance 1;
BA_ "SPN" SG_ 2633832958 SpecialIgnitorLoop84Resistance 4911;
BA_ "SigType" SG_ 2633832958 SpecialIgnitorLoop84Resistance 1;
BA_ "SPN" SG_ 2633832958 SpecialIgnitorLoop83Resistance 4910;
BA_ "SigType" SG_ 2633832958 SpecialIgnitorLoop83Resistance 1;
BA_ "SPN" SG_ 2633832958 SpecialIgnitorLoop82Resistance 4909;
BA_ "SigType" SG_ 2633832958 SpecialIgnitorLoop82Resistance 1;
BA_ "SPN" SG_ 2633832958 SpecialIgnitorLoop81Resistance 4908;
BA_ "SigType" SG_ 2633832958 SpecialIgnitorLoop81Resistance 1;
BA_ "SPN" SG_ 2633832958 SpecialIgnitorLoop80Resistance 4907;
BA_ "SigType" SG_ 2633832958 SpecialIgnitorLoop80Resistance 1;
BA_ "SPN" SG_ 2633832958 SpecialIgnitorLoop79Resistance 4906;
BA_ "SigType" SG_ 2633832958 SpecialIgnitorLoop79Resistance 1;
BA_ "SPN" SG_ 2633832958 SpecialIgnitorLoop78Resistance 4905;
BA_ "SigType" SG_ 2633832958 SpecialIgnitorLoop78Resistance 1;
BA_ "SPN" SG_ 2633832958 SpecialIgnitorLoop77Resistance 4904;
BA_ "SigType" SG_ 2633832958 SpecialIgnitorLoop77Resistance 1;
BA_ "SPN" SG_ 2633832958 SpecialIgnitorLoop76Resistance 4903;
BA_ "SigType" SG_ 2633832958 SpecialIgnitorLoop76Resistance 1;
BA_ "SPN" SG_ 2633832958 SpecialIgnitorLoop75Resistance 4902;
BA_ "SigType" SG_ 2633832958 SpecialIgnitorLoop75Resistance 1;
BA_ "SPN" SG_ 2633832958 SpecialIgnitorLoop74Resistance 4901;
BA_ "SigType" SG_ 2633832958 SpecialIgnitorLoop74Resistance 1;
BA_ "SPN" SG_ 2633832958 SpecialIgnitorLoop73Resistance 4900;
BA_ "SigType" SG_ 2633832958 SpecialIgnitorLoop73Resistance 1;
BA_ "SPN" SG_ 2633832958 SpecialIgnitorLoop72Resistance 4899;
BA_ "SigType" SG_ 2633832958 SpecialIgnitorLoop72Resistance 1;
BA_ "SPN" SG_ 2633832958 SpecialIgnitorLoop71Resistance 4898;
BA_ "SigType" SG_ 2633832958 SpecialIgnitorLoop71Resistance 1;
BA_ "SPN" SG_ 2633832958 SpecialIgnitorLoop70Resistance 4897;
BA_ "SigType" SG_ 2633832958 SpecialIgnitorLoop70Resistance 1;
BA_ "SPN" SG_ 2633832958 SpecialIgnitorLoop69Resistance 4896;
BA_ "SigType" SG_ 2633832958 SpecialIgnitorLoop69Resistance 1;
BA_ "SPN" SG_ 2633832958 SpecialIgnitorLoop68Resistance 4895;
BA_ "SigType" SG_ 2633832958 SpecialIgnitorLoop68Resistance 1;
BA_ "SPN" SG_ 2633832958 SpecialIgnitorLoop67Resistance 4894;
BA_ "SigType" SG_ 2633832958 SpecialIgnitorLoop67Resistance 1;
BA_ "SPN" SG_ 2633832958 SpecialIgnitorLoop66Resistance 4893;
BA_ "SigType" SG_ 2633832958 SpecialIgnitorLoop66Resistance 1;
BA_ "SPN" SG_ 2633832958 SpecialIgnitorLoop65Resistance 4892;
BA_ "SigType" SG_ 2633832958 SpecialIgnitorLoop65Resistance 1;
BA_ "SPN" SG_ 2633832958 SpecialIgnitorLoop64Resistance 4891;
BA_ "SigType" SG_ 2633832958 SpecialIgnitorLoop64Resistance 1;
BA_ "SPN" SG_ 2633832958 SpecialIgnitorLoop63Resistance 4890;
BA_ "SigType" SG_ 2633832958 SpecialIgnitorLoop63Resistance 1;
BA_ "SPN" SG_ 2633832958 SpecialIgnitorLoop61Resistance 4888;
BA_ "SigType" SG_ 2633832958 SpecialIgnitorLoop61Resistance 1;
BA_ "SPN" SG_ 2633832958 SpecialIgnitorLoop60Resistance 4887;
BA_ "SigType" SG_ 2633832958 SpecialIgnitorLoop60Resistance 1;
BA_ "SPN" SG_ 2633832958 SpecialIgnitorLoop59Resistance 4886;
BA_ "SigType" SG_ 2633832958 SpecialIgnitorLoop59Resistance 1;
BA_ "SPN" SG_ 2633832958 SpecialIgnitorLoop58Resistance 4885;
BA_ "SigType" SG_ 2633832958 SpecialIgnitorLoop58Resistance 1;
BA_ "SPN" SG_ 2633832958 SpecialIgnitorLoop57Resistance 4884;
BA_ "SigType" SG_ 2633832958 SpecialIgnitorLoop57Resistance 1;
BA_ "SPN" SG_ 2633832958 SpecialIgnitorLoop56Resistance 4883;
BA_ "SigType" SG_ 2633832958 SpecialIgnitorLoop56Resistance 1;
BA_ "SPN" SG_ 2633832958 SpecialIgnitorLoop55Resistance 4882;
BA_ "SigType" SG_ 2633832958 SpecialIgnitorLoop55Resistance 1;
BA_ "SPN" SG_ 2633832958 SpecialIgnitorLoop54Resistance 4881;
BA_ "SigType" SG_ 2633832958 SpecialIgnitorLoop54Resistance 1;
BA_ "SPN" SG_ 2633832958 SpecialIgnitorLoop53Resistance 4880;
BA_ "SigType" SG_ 2633832958 SpecialIgnitorLoop53Resistance 1;
BA_ "SPN" SG_ 2633832958 SpecialIgnitorLoop52Resistance 4879;
BA_ "SigType" SG_ 2633832958 SpecialIgnitorLoop52Resistance 1;
BA_ "SPN" SG_ 2633832958 SpecialIgnitorLoop51Resistance 4878;
BA_ "SigType" SG_ 2633832958 SpecialIgnitorLoop51Resistance 1;
BA_ "SPN" SG_ 2633832958 SpecialIgnitorLoop50Resistance 4877;
BA_ "SigType" SG_ 2633832958 SpecialIgnitorLoop50Resistance 1;
BA_ "SPN" SG_ 2633832958 SpecialIgnitorLoop49Resistance 4876;
BA_ "SigType" SG_ 2633832958 SpecialIgnitorLoop49Resistance 1;
BA_ "SPN" SG_ 2633832958 SpecialIgnitorLoop48Resistance 4875;
BA_ "SigType" SG_ 2633832958 SpecialIgnitorLoop48Resistance 1;
BA_ "SPN" SG_ 2633832958 SpecialIgnitorLoop47Resistance 4874;
BA_ "SigType" SG_ 2633832958 SpecialIgnitorLoop47Resistance 1;
BA_ "SPN" SG_ 2633832958 SpecialIgnitorLoop46Resistance 4873;
BA_ "SigType" SG_ 2633832958 SpecialIgnitorLoop46Resistance 1;
BA_ "SPN" SG_ 2633832958 SpecialIgnitorLoop45Resistance 4872;
BA_ "SigType" SG_ 2633832958 SpecialIgnitorLoop45Resistance 1;
BA_ "SPN" SG_ 2633832958 SpecialIgnitorLoop44Resistance 4871;
BA_ "SigType" SG_ 2633832958 SpecialIgnitorLoop44Resistance 1;
BA_ "SPN" SG_ 2633832958 SpecialIgnitorLoop43Resistance 4870;
BA_ "SigType" SG_ 2633832958 SpecialIgnitorLoop43Resistance 1;
BA_ "SPN" SG_ 2633832958 SpecialIgnitorLoop42Resistance 4869;
BA_ "SigType" SG_ 2633832958 SpecialIgnitorLoop42Resistance 1;
BA_ "SPN" SG_ 2633832958 SpecialIgnitorLoop41Resistance 4868;
BA_ "SigType" SG_ 2633832958 SpecialIgnitorLoop41Resistance 1;
BA_ "SPN" SG_ 2633832958 SpecialIgnitorLoop40Resistance 4867;
BA_ "SigType" SG_ 2633832958 SpecialIgnitorLoop40Resistance 1;
BA_ "SPN" SG_ 2633832958 SpecialIgnitorLoop39Resistance 4866;
BA_ "SigType" SG_ 2633832958 SpecialIgnitorLoop39Resistance 1;
BA_ "SPN" SG_ 2633832958 SpecialIgnitorLoop38Resistance 4865;
BA_ "SigType" SG_ 2633832958 SpecialIgnitorLoop38Resistance 1;
BA_ "SPN" SG_ 2633832958 SpecialIgnitorLoop37Resistance 4864;
BA_ "SigType" SG_ 2633832958 SpecialIgnitorLoop37Resistance 1;
BA_ "SPN" SG_ 2633832958 SpecialIgnitorLoop36Resistance 4863;
BA_ "SigType" SG_ 2633832958 SpecialIgnitorLoop36Resistance 1;
BA_ "SPN" SG_ 2633832958 SpecialIgnitorLoop35Resistance 4862;
BA_ "SigType" SG_ 2633832958 SpecialIgnitorLoop35Resistance 1;
BA_ "SPN" SG_ 2633832958 SpecialIgnitorLoop34Resistance 4861;
BA_ "SigType" SG_ 2633832958 SpecialIgnitorLoop34Resistance 1;
BA_ "SPN" SG_ 2633832958 SpecialIgnitorLoop33Resistance 4860;
BA_ "SigType" SG_ 2633832958 SpecialIgnitorLoop33Resistance 1;
BA_ "SPN" SG_ 2633832958 SpecialIgnitorLoop32Resistance 4859;
BA_ "SigType" SG_ 2633832958 SpecialIgnitorLoop32Resistance 1;
BA_ "SPN" SG_ 2633832958 SpecialIgnitorLoop31Resistance 4858;
BA_ "SigType" SG_ 2633832958 SpecialIgnitorLoop31Resistance 1;
BA_ "SPN" SG_ 2633832958 SpecialIgnitorLoop30Resistance 4857;
BA_ "SigType" SG_ 2633832958 SpecialIgnitorLoop30Resistance 1;
BA_ "SPN" SG_ 2633832958 SpecialIgnitorLoop29Resistance 4856;
BA_ "SigType" SG_ 2633832958 SpecialIgnitorLoop29Resistance 1;
BA_ "SPN" SG_ 2633832958 SpecialIgnitorLoop28Resistance 4855;
BA_ "SigType" SG_ 2633832958 SpecialIgnitorLoop28Resistance 1;
BA_ "SPN" SG_ 2633832958 SpecialIgnitorLoop27Resistance 4854;
BA_ "SigType" SG_ 2633832958 SpecialIgnitorLoop27Resistance 1;
BA_ "SPN" SG_ 2633832958 SpecialIgnitorLoop26Resistance 4853;
BA_ "SigType" SG_ 2633832958 SpecialIgnitorLoop26Resistance 1;
BA_ "SPN" SG_ 2633832958 SpecialIgnitorLoop25Resistance 4852;
BA_ "SigType" SG_ 2633832958 SpecialIgnitorLoop25Resistance 1;
BA_ "SPN" SG_ 2633832958 SpecialIgnitorLoop24Resistance 4851;
BA_ "SigType" SG_ 2633832958 SpecialIgnitorLoop24Resistance 1;
BA_ "SPN" SG_ 2633832958 SpecialIgnitorLoop23Resistance 4850;
BA_ "SigType" SG_ 2633832958 SpecialIgnitorLoop23Resistance 1;
BA_ "SPN" SG_ 2633832958 SpecialIgnitorLoop22Resistance 4849;
BA_ "SigType" SG_ 2633832958 SpecialIgnitorLoop22Resistance 1;
BA_ "SPN" SG_ 2633832958 SpecialIgnitorLoop21Resistance 4848;
BA_ "SigType" SG_ 2633832958 SpecialIgnitorLoop21Resistance 1;
BA_ "SPN" SG_ 2633832958 SpecialIgnitorLoop20Resistance 4847;
BA_ "SigType" SG_ 2633832958 SpecialIgnitorLoop20Resistance 1;
BA_ "SPN" SG_ 2633832958 SpecialIgnitorLoop19Resistance 4846;
BA_ "SigType" SG_ 2633832958 SpecialIgnitorLoop19Resistance 1;
BA_ "SPN" SG_ 2633832958 SpecialIgnitorLoop18Resistance 4845;
BA_ "SigType" SG_ 2633832958 SpecialIgnitorLoop18Resistance 1;
BA_ "SPN" SG_ 2633832958 SpecialIgnitorLoop17Resistance 4844;
BA_ "SigType" SG_ 2633832958 SpecialIgnitorLoop17Resistance 1;
BA_ "SPN" SG_ 2633832958 SpecialIgnitorLoop16Resistance 4843;
BA_ "SigType" SG_ 2633832958 SpecialIgnitorLoop16Resistance 1;
BA_ "SPN" SG_ 2633832958 SpecialIgnitorLoop15Resistance 4842;
BA_ "SigType" SG_ 2633832958 SpecialIgnitorLoop15Resistance 1;
BA_ "SPN" SG_ 2633832958 SpecialIgnitorLoop14Resistance 4841;
BA_ "SigType" SG_ 2633832958 SpecialIgnitorLoop14Resistance 1;
BA_ "SPN" SG_ 2633832958 SpecialIgnitorLoop13Resistance 4840;
BA_ "SigType" SG_ 2633832958 SpecialIgnitorLoop13Resistance 1;
BA_ "SPN" SG_ 2633832958 SpecialIgnitorLoop12Resistance 4839;
BA_ "SigType" SG_ 2633832958 SpecialIgnitorLoop12Resistance 1;
BA_ "SPN" SG_ 2633832958 SpecialIgnitorLoop11Resistance 4838;
BA_ "SigType" SG_ 2633832958 SpecialIgnitorLoop11Resistance 1;
BA_ "SPN" SG_ 2633832958 SpecialIgnitorLoop10Resistance 4837;
BA_ "SigType" SG_ 2633832958 SpecialIgnitorLoop10Resistance 1;
BA_ "SPN" SG_ 2633832958 SpecialIgnitorLoop9Resistance 4836;
BA_ "SigType" SG_ 2633832958 SpecialIgnitorLoop9Resistance 1;
BA_ "SPN" SG_ 2633832958 SpecialIgnitorLoop8Resistance 4835;
BA_ "SigType" SG_ 2633832958 SpecialIgnitorLoop8Resistance 1;
BA_ "SPN" SG_ 2633832958 SpecialIgnitorLoop7Resistance 4834;
BA_ "SigType" SG_ 2633832958 SpecialIgnitorLoop7Resistance 1;
BA_ "SPN" SG_ 2633832958 SpecialIgnitorLoop6Resistance 4833;
BA_ "SigType" SG_ 2633832958 SpecialIgnitorLoop6Resistance 1;
BA_ "SPN" SG_ 2633832958 SpecialIgnitorLoop5Resistance 4832;
BA_ "SigType" SG_ 2633832958 SpecialIgnitorLoop5Resistance 1;
BA_ "SPN" SG_ 2633832958 SpecialIgnitorLoop4Resistance 4831;
BA_ "SigType" SG_ 2633832958 SpecialIgnitorLoop4Resistance 1;
BA_ "SPN" SG_ 2633832958 SpecialIgnitorLoop3Resistance 4830;
BA_ "SigType" SG_ 2633832958 SpecialIgnitorLoop3Resistance 1;
BA_ "SPN" SG_ 2633832958 SpecialIgnitorLoop2Resistance 4829;
BA_ "SigType" SG_ 2633832958 SpecialIgnitorLoop2Resistance 1;
BA_ "SPN" SG_ 2633832958 SpecialIgnitorLoop1Resistance 4828;
BA_ "SigType" SG_ 2633832958 SpecialIgnitorLoop1Resistance 1;
BA_ "SPN" SG_ 2633832958 SdBgIgnitorLoop2RightResistance 4827;
BA_ "SigType" SG_ 2633832958 SdBgIgnitorLoop2RightResistance 1;
BA_ "SPN" SG_ 2633832958 SdBgIgnitorLoop1RightResistance 4826;
BA_ "SigType" SG_ 2633832958 SdBgIgnitorLoop1RightResistance 1;
BA_ "SPN" SG_ 2633832958 SdBagIgnitorLoop2LeftResistance 4825;
BA_ "SigType" SG_ 2633832958 SdBagIgnitorLoop2LeftResistance 1;
BA_ "SPN" SG_ 2633832958 SdBagIgnitorLoop1LeftResistance 4824;
BA_ "SigType" SG_ 2633832958 SdBagIgnitorLoop1LeftResistance 1;
BA_ "SPN" SG_ 2633832958 PssngrBltTnsnrIgntrLpResistance 4823;
BA_ "SigType" SG_ 2633832958 PssngrBltTnsnrIgntrLpResistance 1;
BA_ "SPN" SG_ 2633832958 DrvrBltTnsnrIgntrLoopResistance 4822;
BA_ "SigType" SG_ 2633832958 DrvrBltTnsnrIgntrLoopResistance 1;
BA_ "SPN" SG_ 2633832958 PssngrArbgIgntrLp2ndStgRsstance 4821;
BA_ "SigType" SG_ 2633832958 PssngrArbgIgntrLp2ndStgRsstance 1;
BA_ "SPN" SG_ 2633832958 DrvrArbgIgntrLp2ndStgResistance 4820;
BA_ "SigType" SG_ 2633832958 DrvrArbgIgntrLp2ndStgResistance 1;
BA_ "SPN" SG_ 2633832958 PssngrArbgIgntrLp1stStgRsstance 4819;
BA_ "SigType" SG_ 2633832958 PssngrArbgIgntrLp1stStgRsstance 1;
BA_ "SPN" SG_ 2633832958 DrvrArbgIgntrLp1stStgResistance 4818;
BA_ "SigType" SG_ 2633832958 DrvrArbgIgntrLp1stStgResistance 1;
BA_ "SPN" SG_ 2633938942 TotalEngCruiseTime 1017;
BA_ "SigType" SG_ 2633938942 TotalEngCruiseTime 1;
BA_ "SPN" SG_ 2633938942 TotalDriveAverageLoadFactor 1016;
BA_ "SigType" SG_ 2633938942 TotalDriveAverageLoadFactor 1;
BA_ "SPN" SG_ 2633938942 TripDriveAverageLoadFactor 1015;
BA_ "SigType" SG_ 2633938942 TripDriveAverageLoadFactor 1;
BA_ "SPN" SG_ 2633938942 TripAverageEngSpeed 1014;
BA_ "SigType" SG_ 2633938942 TripAverageEngSpeed 1;
BA_ "SPN" SG_ 2633938942 TripMaxEngSpeed 1013;
BA_ "SigType" SG_ 2633938942 TripMaxEngSpeed 1;
BA_ "SPN" SG_ 2633939198 TripDriveFuelEconomy 1012;
BA_ "SigType" SG_ 2633939198 TripDriveFuelEconomy 1;
BA_ "SPN" SG_ 2633939198 TrpPTOGovernorNonmovingFuelUsed 1009;
BA_ "SigType" SG_ 2633939198 TrpPTOGovernorNonmovingFuelUsed 1;
BA_ "SPN" SG_ 2633939198 TripVehicleIdleFuelUsed 1010;
BA_ "SigType" SG_ 2633939198 TripVehicleIdleFuelUsed 1;
BA_ "SPN" SG_ 2633939198 TripCruiseFuelUsed 1011;
BA_ "SigType" SG_ 2633939198 TripCruiseFuelUsed 1;
BA_ "SPN" SG_ 2633939198 TripDriveFuelUsed 1007;
BA_ "SigType" SG_ 2633939198 TripDriveFuelUsed 1;
BA_ "SPN" SG_ 2633939198 TripPTOGovernorMovingFuelUsed 1008;
BA_ "SigType" SG_ 2633939198 TripPTOGovernorMovingFuelUsed 1;
BA_ "SPN" SG_ 2633937150 TripAirCompressorOnTime 1038;
BA_ "SigType" SG_ 2633937150 TripAirCompressorOnTime 1;
BA_ "SPN" SG_ 2633937150 TripIdleTime 1037;
BA_ "SigType" SG_ 2633937150 TripIdleTime 1;
BA_ "SPN" SG_ 2633937150 TripEngRunningTime 1036;
BA_ "SigType" SG_ 2633937150 TripEngRunningTime 1;
BA_ "SPN" SG_ 2633937150 TripCruiseTime 1034;
BA_ "SigType" SG_ 2633937150 TripCruiseTime 1;
BA_ "SPN" SG_ 2633937150 TripPTOGovernorTime 1035;
BA_ "SigType" SG_ 2633937150 TripPTOGovernorTime 1;
BA_ "SPN" SG_ 2633938174 TripTimeInDerateByEng 1027;
BA_ "SigType" SG_ 2633938174 TripTimeInDerateByEng 1;
BA_ "SPN" SG_ 2633938174 TripTimeInGearDown 1026;
BA_ "SigType" SG_ 2633938174 TripTimeInGearDown 1;
BA_ "SPN" SG_ 2633938174 TripTimeInTopGear 1025;
BA_ "SigType" SG_ 2633938174 TripTimeInTopGear 1;
BA_ "SPN" SG_ 2633938174 TripTimeInVSL 1024;
BA_ "SigType" SG_ 2633938174 TripTimeInVSL 1;
BA_ "SPN" SG_ 2566765822 DriversFareboxSecurityCode 3164;
BA_ "SigType" SG_ 2566765822 DriversFareboxSecurityCode 1;
BA_ "SPN" SG_ 2566765822 AssignedBlock 3163;
BA_ "SigType" SG_ 2566765822 AssignedBlock 1;
BA_ "SPN" SG_ 2566765822 AssignedRun 3162;
BA_ "SigType" SG_ 2566765822 AssignedRun 1;
BA_ "SPN" SG_ 2566765822 AssignedRoute 3160;
BA_ "SigType" SG_ 2566765822 AssignedRoute 1;
BA_ "SPN" SG_ 2566765822 PatternNumber 3161;
BA_ "SigType" SG_ 2566765822 PatternNumber 1;
BA_ "SPN" SG_ 2566765822 TripNumber 3159;
BA_ "SigType" SG_ 2566765822 TripNumber 1;
BA_ "SPN" SG_ 2566765822 FarePresets 3175;
BA_ "SigType" SG_ 2566765822 FarePresets 1;
BA_ "SPN" SG_ 2566765822 TripDirection 3174;
BA_ "SigType" SG_ 2566765822 TripDirection 4;
BA_ "SPN" SG_ 2566765822 TripStatus 3180;
BA_ "SPN" SG_ 2566765822 FareboxServiceStatus 3178;
BA_ "SigType" SG_ 2566765822 FareboxServiceStatus 4;
BA_ "SPN" SG_ 2633939966 TripFanOnTimeDueToAManualSwitch 996;
BA_ "SigType" SG_ 2633939966 TripFanOnTimeDueToAManualSwitch 1;
BA_ "SPN" SG_ 2633939966 TripFanOnTime 994;
BA_ "SigType" SG_ 2633939966 TripFanOnTime 1;
BA_ "SPN" SG_ 2633939966 TripFanOnTimeDueToA_CSystem 997;
BA_ "SigType" SG_ 2633939966 TripFanOnTimeDueToA_CSystem 1;
BA_ "SPN" SG_ 2633939966 TripFanOnTimeDueToEngSystem 995;
BA_ "SigType" SG_ 2633939966 TripFanOnTimeDueToEngSystem 1;
BA_ "SPN" SG_ 2633939710 TripDistanceInTopGear 1000;
BA_ "SigType" SG_ 2633939710 TripDistanceInTopGear 1;
BA_ "SPN" SG_ 2633939710 TripGearDownDistance 999;
BA_ "SigType" SG_ 2633939710 TripGearDownDistance 1;
BA_ "SPN" SG_ 2633939710 TripDistanceOnVSL 998;
BA_ "SigType" SG_ 2633939710 TripDistanceOnVSL 1;
BA_ "SPN" SG_ 2566840830 PercentTorqueAtPeakTorquePoint5 555;
BA_ "SigType" SG_ 2566840830 PercentTorqueAtPeakTorquePoint5 1;
BA_ "SPN" SG_ 2566840830 ReferenceRetarderTorque 556;
BA_ "SigType" SG_ 2566840830 ReferenceRetarderTorque 1;
BA_ "SPN" SG_ 2566840830 RetarderSpeedAtPeakTorquePoint5 547;
BA_ "SigType" SG_ 2566840830 RetarderSpeedAtPeakTorquePoint5 1;
BA_ "SPN" SG_ 2566840830 PercentTorqueAtPoint4 554;
BA_ "SigType" SG_ 2566840830 PercentTorqueAtPoint4 1;
BA_ "SPN" SG_ 2566840830 RetarderSpeedAtPoint4 550;
BA_ "SigType" SG_ 2566840830 RetarderSpeedAtPoint4 1;
BA_ "SPN" SG_ 2566840830 PercentTorqueAtPoint3 553;
BA_ "SigType" SG_ 2566840830 PercentTorqueAtPoint3 1;
BA_ "SPN" SG_ 2566840830 RetarderSpeedAtPoint3 549;
BA_ "SigType" SG_ 2566840830 RetarderSpeedAtPoint3 1;
BA_ "SPN" SG_ 2566840830 PercentTorqueAtMaxSpeedPoint2 552;
BA_ "SigType" SG_ 2566840830 PercentTorqueAtMaxSpeedPoint2 1;
BA_ "SPN" SG_ 2566840830 MaxRetarderSpeedPoint2 548;
BA_ "SigType" SG_ 2566840830 MaxRetarderSpeedPoint2 1;
BA_ "SPN" SG_ 2566840830 PercentTorqueAtIdlePoint1 551;
BA_ "SigType" SG_ 2566840830 PercentTorqueAtIdlePoint1 1;
BA_ "SPN" SG_ 2566840830 RetarderSpeedAtIdlePoint1 546;
BA_ "SigType" SG_ 2566840830 RetarderSpeedAtIdlePoint1 1;
BA_ "SPN" SG_ 2566840830 RetarderCtrlMethod 557;
BA_ "SigType" SG_ 2566840830 RetarderCtrlMethod 1;
BA_ "SPN" SG_ 2566840830 RetarderLocation 902;
BA_ "SigType" SG_ 2566840830 RetarderLocation 4;
BA_ "SPN" SG_ 2566840830 RetarderType 901;
BA_ "SigType" SG_ 2566840830 RetarderType 4;
BA_ "SPN" SG_ 2633939454 TripCruiseFuelUsed 1005;
BA_ "SigType" SG_ 2633939454 TripCruiseFuelUsed 1;
BA_ "SPN" SG_ 2633939454 TripVehicleIdleFuelUsed 1004;
BA_ "SigType" SG_ 2633939454 TripVehicleIdleFuelUsed 1;
BA_ "SPN" SG_ 2633939454 TripDriveFuelUsed 1001;
BA_ "SigType" SG_ 2633939454 TripDriveFuelUsed 1;
BA_ "SPN" SG_ 2633939454 TrpPTOGovernorNonmovingFuelUsed 1003;
BA_ "SigType" SG_ 2633939454 TrpPTOGovernorNonmovingFuelUsed 1;
BA_ "SPN" SG_ 2633939454 TripPTOGovernorMovingFuelUsed 1002;
BA_ "SigType" SG_ 2633939454 TripPTOGovernorMovingFuelUsed 1;
BA_ "SPN" SG_ 2633939454 TripDriveFuelEconomy 1006;
BA_ "SigType" SG_ 2633939454 TripDriveFuelEconomy 1;
BA_ "SPN" SG_ 2566820094 EngTorqueLimit6AxleInput 1263;
BA_ "SigType" SG_ 2566820094 EngTorqueLimit6AxleInput 1;
BA_ "SPN" SG_ 2566820094 EngTorqueLimit5Switch 1262;
BA_ "SigType" SG_ 2566820094 EngTorqueLimit5Switch 1;
BA_ "SPN" SG_ 2566820094 EngTorqueLimit4Trans 1261;
BA_ "SigType" SG_ 2566820094 EngTorqueLimit4Trans 1;
BA_ "SPN" SG_ 2566820094 EngTorqueLimit3Trans 1260;
BA_ "SigType" SG_ 2566820094 EngTorqueLimit3Trans 1;
BA_ "SPN" SG_ 2566820094 TransGearRatio3 1259;
BA_ "SigType" SG_ 2566820094 TransGearRatio3 1;
BA_ "SPN" SG_ 2566820094 EngTorqueLimit2Trans 1258;
BA_ "SigType" SG_ 2566820094 EngTorqueLimit2Trans 1;
BA_ "SPN" SG_ 2566820094 TransGearRatio2 1257;
BA_ "SigType" SG_ 2566820094 TransGearRatio2 1;
BA_ "SPN" SG_ 2566820094 EngTorqueLimit1Trans 1256;
BA_ "SigType" SG_ 2566820094 EngTorqueLimit1Trans 1;
BA_ "SPN" SG_ 2566820094 TransGearRatio1 1255;
BA_ "SigType" SG_ 2566820094 TransGearRatio1 1;
BA_ "SPN" SG_ 2566820094 EngTorqueLimitFeature 1632;
BA_ "SPN" SG_ 2566820094 TorqueLimitingFeatureStatus 1254;
BA_ "SigType" SG_ 2566820094 TorqueLimitingFeatureStatus 4;
BA_ "SPN" SG_ 2566820094 CalibRecordDurationTime 1253;
BA_ "SigType" SG_ 2566820094 CalibRecordDurationTime 1;
BA_ "SPN" SG_ 2566820094 CalibRecordStartYear 1252;
BA_ "SigType" SG_ 2566820094 CalibRecordStartYear 1;
BA_ "SPN" SG_ 2566820094 CalibRecordStartDay 1251;
BA_ "SigType" SG_ 2566820094 CalibRecordStartDay 1;
BA_ "SPN" SG_ 2566820094 CalibRecordStartMonth 1250;
BA_ "SigType" SG_ 2566820094 CalibRecordStartMonth 1;
BA_ "SPN" SG_ 2566820094 EngPeakTorque2 1249;
BA_ "SigType" SG_ 2566820094 EngPeakTorque2 1;
BA_ "SPN" SG_ 2566820094 EngPeakTorque1 1248;
BA_ "SigType" SG_ 2566820094 EngPeakTorque1 1;
BA_ "SPN" SG_ 2566820094 EngPower 1247;
BA_ "SigType" SG_ 2566820094 EngPower 1;
BA_ "SPN" SG_ 2566820094 NumberOfEngTorqueHistoryRecords 1246;
BA_ "SigType" SG_ 2566820094 NumberOfEngTorqueHistoryRecords 1;
BA_ "SPN" SG_ 2566841342 SupportTSC1CtrlPurposeGroup4 3348;
BA_ "SigType" SG_ 2566841342 SupportTSC1CtrlPurposeGroup4 1;
BA_ "SPN" SG_ 2566841342 SupportTSC1CtrlPurposeGroup3 3347;
BA_ "SigType" SG_ 2566841342 SupportTSC1CtrlPurposeGroup3 1;
BA_ "SPN" SG_ 2566841342 SupportTSC1CtrlPurposeGroup2 3346;
BA_ "SigType" SG_ 2566841342 SupportTSC1CtrlPurposeGroup2 1;
BA_ "SPN" SG_ 2566841342 SupportTSC1CtrlPurposeGroup1 3345;
BA_ "SigType" SG_ 2566841342 SupportTSC1CtrlPurposeGroup1 1;
BA_ "SPN" SG_ 2566841342 SupportVariableRateTSC1Message 3344;
BA_ "SigType" SG_ 2566841342 SupportVariableRateTSC1Message 1;
BA_ "SPN" SG_ 2566841342 EngDefaultTorqueLimit 1846;
BA_ "SigType" SG_ 2566841342 EngDefaultTorqueLimit 1;
BA_ "SPN" SG_ 2566841342 EngMomentOfInertia 1794;
BA_ "SigType" SG_ 2566841342 EngMomentOfInertia 1;
BA_ "SPN" SG_ 2566841342 EngExRngRqdSpdCtrlRngUpperLimit 1712;
BA_ "SigType" SG_ 2566841342 EngExRngRqdSpdCtrlRngUpperLimit 1;
BA_ "SPN" SG_ 2566841342 EngRqdTorqueCtrlRangeUpperLimit 538;
BA_ "SigType" SG_ 2566841342 EngRqdTorqueCtrlRangeUpperLimit 1;
BA_ "SPN" SG_ 2566841342 EngRqdTorqueCtrlRangeLowerLimit 537;
BA_ "SigType" SG_ 2566841342 EngRqdTorqueCtrlRangeLowerLimit 1;
BA_ "SPN" SG_ 2566841342 EngRqedSpeedCtrlRangeUpperLimit 536;
BA_ "SigType" SG_ 2566841342 EngRqedSpeedCtrlRangeUpperLimit 1;
BA_ "SPN" SG_ 2566841342 EngRqedSpeedCtrlRangeLowerLimit 535;
BA_ "SigType" SG_ 2566841342 EngRqedSpeedCtrlRangeLowerLimit 1;
BA_ "SPN" SG_ 2566841342 EngMxMomentaryOverrideTimeLimit 534;
BA_ "SigType" SG_ 2566841342 EngMxMomentaryOverrideTimeLimit 1;
BA_ "SPN" SG_ 2566841342 EngMxMmntaryOverrideSpeedPoint7 533;
BA_ "SigType" SG_ 2566841342 EngMxMmntaryOverrideSpeedPoint7 1;
BA_ "SPN" SG_ 2566841342 EngReferenceTorque 544;
BA_ "SigType" SG_ 2566841342 EngReferenceTorque 1;
BA_ "SPN" SG_ 2566841342 EngSpeedAtHighIdlePoint6 532;
BA_ "SigType" SG_ 2566841342 EngSpeedAtHighIdlePoint6 1;
BA_ "SPN" SG_ 2566841342 EngGainOfEndspeedGovernor 545;
BA_ "SigType" SG_ 2566841342 EngGainOfEndspeedGovernor 1;
BA_ "SPN" SG_ 2566841342 EngPercentTorqueAtPoint5 543;
BA_ "SigType" SG_ 2566841342 EngPercentTorqueAtPoint5 1;
BA_ "SPN" SG_ 2566841342 EngSpeedAtPoint5 531;
BA_ "SigType" SG_ 2566841342 EngSpeedAtPoint5 1;
BA_ "SPN" SG_ 2566841342 EngPercentTorqueAtPoint4 542;
BA_ "SigType" SG_ 2566841342 EngPercentTorqueAtPoint4 1;
BA_ "SPN" SG_ 2566841342 EngSpeedAtPoint4 530;
BA_ "SigType" SG_ 2566841342 EngSpeedAtPoint4 1;
BA_ "SPN" SG_ 2566841342 EngPercentTorqueAtPoint3 541;
BA_ "SigType" SG_ 2566841342 EngPercentTorqueAtPoint3 1;
BA_ "SPN" SG_ 2566841342 EngSpeedAtPoint3 529;
BA_ "SigType" SG_ 2566841342 EngSpeedAtPoint3 1;
BA_ "SPN" SG_ 2566841342 EngPercentTorqueAtPoint2 540;
BA_ "SigType" SG_ 2566841342 EngPercentTorqueAtPoint2 1;
BA_ "SPN" SG_ 2566841342 EngSpeedAtPoint2 528;
BA_ "SigType" SG_ 2566841342 EngSpeedAtPoint2 1;
BA_ "SPN" SG_ 2566841342 EngPercentTorqueAtIdlePoint1 539;
BA_ "SigType" SG_ 2566841342 EngPercentTorqueAtIdlePoint1 1;
BA_ "SPN" SG_ 2566841342 EngSpeedAtIdlePoint1 188;
BA_ "SigType" SG_ 2566841342 EngSpeedAtIdlePoint1 1;
BA_ "SPN" SG_ 2633940222 TripServiceBrakeApps 993;
BA_ "SigType" SG_ 2633940222 TripServiceBrakeApps 1;
BA_ "SPN" SG_ 2633940222 TripServiceBrakeDistance 992;
BA_ "SigType" SG_ 2633940222 TripServiceBrakeDistance 1;
BA_ "SPN" SG_ 2633940222 TripCompressionBrakeDistance 991;
BA_ "SigType" SG_ 2633940222 TripCompressionBrakeDistance 1;
BA_ "SPN" SG_ 2633940222 TotalCompressionBrakeDistance 990;
BA_ "SigType" SG_ 2633940222 TotalCompressionBrakeDistance 1;
BA_ "SPN" SG_ 2292317950 AECDEngineHours1Timer2 4126;
BA_ "SigType" SG_ 2292317950 AECDEngineHours1Timer2 1;
BA_ "SPN" SG_ 2292317950 AECDEngineHours1Timer1 4125;
BA_ "SigType" SG_ 2292317950 AECDEngineHours1Timer1 1;
BA_ "SPN" SG_ 2292317950 AECDNumber1 4124;
BA_ "SigType" SG_ 2292317950 AECDNumber1 1;
BA_ "SPN" SG_ 2566756606 Aftrtrtmnt1TtlNmbrOfActvRgnrtnMn 3728;
BA_ "SigType" SG_ 2566756606 Aftrtrtmnt1TtlNmbrOfActvRgnrtnMn 1;
BA_ "SystemSignalLongSymbol" SG_ 2566756606 Aftrtrtmnt1TtlNmbrOfActvRgnrtnMn "Aftrtrtmnt1TtlNmbrOfActvRgnrtnMnlRqs";
BA_ "SPN" SG_ 2566756606 Aftrtrtmnt1TtlNmbrOfActvRgnrtnIn 3727;
BA_ "SigType" SG_ 2566756606 Aftrtrtmnt1TtlNmbrOfActvRgnrtnIn 1;
BA_ "SystemSignalLongSymbol" SG_ 2566756606 Aftrtrtmnt1TtlNmbrOfActvRgnrtnIn "Aftrtrtmnt1TtlNmbrOfActvRgnrtnInhbtRqs";
BA_ "SPN" SG_ 2566756606 Aftrtrtmnt1AvrgTmBtwnActvRgnrtns 5454;
BA_ "SigType" SG_ 2566756606 Aftrtrtmnt1AvrgTmBtwnActvRgnrtns 1;
BA_ "SPN" SG_ 2566756606 Aftrtrtmnt1TtlNmbrOfPssvRgnrtns 3726;
BA_ "SigType" SG_ 2566756606 Aftrtrtmnt1TtlNmbrOfPssvRgnrtns 1;
BA_ "SPN" SG_ 2566756606 Aftrtrtmnt1TtlPssvRgnrationTime 3725;
BA_ "SigType" SG_ 2566756606 Aftrtrtmnt1TtlPssvRgnrationTime 1;
BA_ "SPN" SG_ 2566756606 Aftrtrtmnt1TtlNmbrOfActvRgnrtns 3525;
BA_ "SigType" SG_ 2566756606 Aftrtrtmnt1TtlNmbrOfActvRgnrtns 1;
BA_ "SPN" SG_ 2566756606 Aftrtreatment1TotalDisabledTime 3524;
BA_ "SigType" SG_ 2566756606 Aftrtreatment1TotalDisabledTime 1;
BA_ "SPN" SG_ 2566756606 Aftrtrtmnt1TtalRegenerationTime 3523;
BA_ "SigType" SG_ 2566756606 Aftrtrtmnt1TtalRegenerationTime 1;
BA_ "SPN" SG_ 2566756606 Aftertreatment1TotalFuelUsed 3522;
BA_ "SigType" SG_ 2566756606 Aftertreatment1TotalFuelUsed 1;
BA_ "SPN" SG_ 2560950014 TestLimitMinimum 4112;
BA_ "SigType" SG_ 2560950014 TestLimitMinimum 1;
BA_ "SPN" SG_ 2560950014 TestLimitMaximum 4111;
BA_ "SigType" SG_ 2560950014 TestLimitMaximum 1;
BA_ "SPN" SG_ 2560950014 TestValue 4110;
BA_ "SigType" SG_ 2560950014 TestValue 1;
BA_ "SPN" SG_ 2560950014 SlotId 4109;
BA_ "SigType" SG_ 2560950014 SlotId 1;
BA_ "SPN" SG_ 2560950014 FailureModeIdentifier1 1215;
BA_ "SPN" SG_ 2560950014 SPN1High 1214;
BA_ "SPN" SG_ 2560950014 SPN1 1214;
BA_ "SPN" SG_ 2566748670 Aftrtrtmnt1TrpNmbrOfActvRgnrtnMn 3740;
BA_ "SigType" SG_ 2566748670 Aftrtrtmnt1TrpNmbrOfActvRgnrtnMn 1;
BA_ "SystemSignalLongSymbol" SG_ 2566748670 Aftrtrtmnt1TrpNmbrOfActvRgnrtnMn "Aftrtrtmnt1TrpNmbrOfActvRgnrtnMnlRqs";
BA_ "SPN" SG_ 2566748670 Aftrtrtmnt1TrpNmbrOfActvRgnrtnIn 3739;
BA_ "SigType" SG_ 2566748670 Aftrtrtmnt1TrpNmbrOfActvRgnrtnIn 1;
BA_ "SystemSignalLongSymbol" SG_ 2566748670 Aftrtrtmnt1TrpNmbrOfActvRgnrtnIn "Aftrtrtmnt1TrpNmbrOfActvRgnrtnInhbtRqs";
BA_ "SPN" SG_ 2566748670 Aftrtrtmnt1TrpNmbrOfPssvRgnrtns 3738;
BA_ "SigType" SG_ 2566748670 Aftrtrtmnt1TrpNmbrOfPssvRgnrtns 1;
BA_ "SPN" SG_ 2566748670 Aftrtrtmnt1TrpPssvRgnrationTime 3737;
BA_ "SigType" SG_ 2566748670 Aftrtrtmnt1TrpPssvRgnrationTime 1;
BA_ "SPN" SG_ 2566748670 Aftrtrtmnt1TrpNmbrOfActvRgnrtns 3736;
BA_ "SigType" SG_ 2566748670 Aftrtrtmnt1TrpNmbrOfActvRgnrtns 1;
BA_ "SPN" SG_ 2566748670 Aftertreatment1TripDisabledTime 3735;
BA_ "SigType" SG_ 2566748670 Aftertreatment1TripDisabledTime 1;
BA_ "SPN" SG_ 2566748670 Aftrtrtmnt1TrpActvRgnrationTime 3734;
BA_ "SigType" SG_ 2566748670 Aftrtrtmnt1TrpActvRgnrationTime 1;
BA_ "SPN" SG_ 2566748670 Aftertreatment1TripFuelUsed 3733;
BA_ "SigType" SG_ 2566748670 Aftertreatment1TripFuelUsed 1;
BA_ "SPN" SG_ 2566756862 Aftrtrtmnt2TtlNmbrOfActvRgnrtnMn 3732;
BA_ "SigType" SG_ 2566756862 Aftrtrtmnt2TtlNmbrOfActvRgnrtnMn 1;
BA_ "SystemSignalLongSymbol" SG_ 2566756862 Aftrtrtmnt2TtlNmbrOfActvRgnrtnMn "Aftrtrtmnt2TtlNmbrOfActvRgnrtnMnlRqs";
BA_ "SPN" SG_ 2566756862 Aftrtrtmnt2TtlNmbrOfActvRgnrtnIn 3731;
BA_ "SigType" SG_ 2566756862 Aftrtrtmnt2TtlNmbrOfActvRgnrtnIn 1;
BA_ "SystemSignalLongSymbol" SG_ 2566756862 Aftrtrtmnt2TtlNmbrOfActvRgnrtnIn "Aftrtrtmnt2TtlNmbrOfActvRgnrtnInhbtRqs";
BA_ "SPN" SG_ 2566756862 Aftrtrtmnt2AvrgTmBtwnActvRgnrtns 5455;
BA_ "SigType" SG_ 2566756862 Aftrtrtmnt2AvrgTmBtwnActvRgnrtns 1;
BA_ "SPN" SG_ 2566756862 Aftrtrtmnt2TtlNmbrOfPssvRgnrtns 3730;
BA_ "SigType" SG_ 2566756862 Aftrtrtmnt2TtlNmbrOfPssvRgnrtns 1;
BA_ "SPN" SG_ 2566756862 Aftrtrtmnt2TtlPssvRgnrationTime 3729;
BA_ "SigType" SG_ 2566756862 Aftrtrtmnt2TtlPssvRgnrationTime 1;
BA_ "SPN" SG_ 2566756862 Aftrtrtmnt2TtlNmbrOfActvRgnrtns 3529;
BA_ "SigType" SG_ 2566756862 Aftrtrtmnt2TtlNmbrOfActvRgnrtns 1;
BA_ "SPN" SG_ 2566756862 Aftrtreatment2TotalDisabledTime 3528;
BA_ "SigType" SG_ 2566756862 Aftrtreatment2TotalDisabledTime 1;
BA_ "SPN" SG_ 2566756862 Aftrtrtmnt2TtalRegenerationTime 3527;
BA_ "SigType" SG_ 2566756862 Aftrtrtmnt2TtalRegenerationTime 1;
BA_ "SPN" SG_ 2566756862 Aftertreatment2TotalFuelUsed 3526;
BA_ "SigType" SG_ 2566756862 Aftertreatment2TotalFuelUsed 1;
BA_ "SPN" SG_ 2566748414 Aftrtrtmnt2TrpNmbrOfActvRgnrtnMn 3748;
BA_ "SigType" SG_ 2566748414 Aftrtrtmnt2TrpNmbrOfActvRgnrtnMn 1;
BA_ "SystemSignalLongSymbol" SG_ 2566748414 Aftrtrtmnt2TrpNmbrOfActvRgnrtnMn "Aftrtrtmnt2TrpNmbrOfActvRgnrtnMnlRqs";
BA_ "SPN" SG_ 2566748414 Aftrtrtmnt2TrpNmbrOfActvRgnrtnIn 3747;
BA_ "SigType" SG_ 2566748414 Aftrtrtmnt2TrpNmbrOfActvRgnrtnIn 1;
BA_ "SystemSignalLongSymbol" SG_ 2566748414 Aftrtrtmnt2TrpNmbrOfActvRgnrtnIn "Aftrtrtmnt2TrpNmbrOfActvRgnrtnInhbtRqs";
BA_ "SPN" SG_ 2566748414 Aftrtrtmnt2TrpNmbrOfPssvRgnrtns 3746;
BA_ "SigType" SG_ 2566748414 Aftrtrtmnt2TrpNmbrOfPssvRgnrtns 1;
BA_ "SPN" SG_ 2566748414 Aftrtrtmnt2TrpPssvRgnrationTime 3745;
BA_ "SigType" SG_ 2566748414 Aftrtrtmnt2TrpPssvRgnrationTime 1;
BA_ "SPN" SG_ 2566748414 Aftrtrtmnt2TrpNmbrOfActvRgnrtns 3744;
BA_ "SigType" SG_ 2566748414 Aftrtrtmnt2TrpNmbrOfActvRgnrtns 1;
BA_ "SPN" SG_ 2566748414 Aftertreatment2TripDisabledTime 3743;
BA_ "SigType" SG_ 2566748414 Aftertreatment2TripDisabledTime 1;
BA_ "SPN" SG_ 2566748414 Aftrtrtmnt2TrpActvRgnrationTime 3742;
BA_ "SigType" SG_ 2566748414 Aftrtrtmnt2TrpActvRgnrationTime 1;
BA_ "SPN" SG_ 2566748414 Aftertreatment2TripFuelUsed 3741;
BA_ "SigType" SG_ 2566748414 Aftertreatment2TripFuelUsed 1;
BA_ "SPN" SG_ 2566836222 FlashRedStopLamp 3039;
BA_ "SigType" SG_ 2566836222 FlashRedStopLamp 4;
BA_ "SPN" SG_ 2566836222 FlashProtectLamp 3041;
BA_ "SigType" SG_ 2566836222 FlashProtectLamp 4;
BA_ "SPN" SG_ 2566836222 FlashMalfuncIndicatorLamp 3038;
BA_ "SigType" SG_ 2566836222 FlashMalfuncIndicatorLamp 4;
BA_ "SPN" SG_ 2566836222 FlashAmberWarningLamp 3040;
BA_ "SigType" SG_ 2566836222 FlashAmberWarningLamp 4;
BA_ "SPN" SG_ 2566836222 MalfunctionIndicatorLampStatus 1213;
BA_ "SigType" SG_ 2566836222 MalfunctionIndicatorLampStatus 4;
BA_ "SPN" SG_ 2566836222 RedStopLampState 623;
BA_ "SigType" SG_ 2566836222 RedStopLampState 4;
BA_ "SPN" SG_ 2566836222 AmberWarningLampStatus 624;
BA_ "SigType" SG_ 2566836222 AmberWarningLampStatus 4;
BA_ "SPN" SG_ 2566836222 ProtectLampStatus 987;
BA_ "SigType" SG_ 2566836222 ProtectLampStatus 4;
BA_ "SigType" SG_ 2566836222 DTC5 7;
BA_ "SigType" SG_ 2566836222 DTC4 7;
BA_ "SigType" SG_ 2566836222 DTC3 7;
BA_ "SigType" SG_ 2566836222 DTC2 7;
BA_ "SigType" SG_ 2566836222 DTC1 7;
BA_ "SPN" SG_ 2566835710 EngIntakeManifold1Press 102;
BA_ "SigType" SG_ 2566835710 EngIntakeManifold1Press 1;
BA_ "SPN" SG_ 2566835710 FreezeFrameLength 1217;
BA_ "SPN" SG_ 2566835710 EngSpeed 190;
BA_ "SigType" SG_ 2566835710 EngSpeed 1;
BA_ "SPN" SG_ 2566835710 EngTorqueMode 899;
BA_ "SigType" SG_ 2566835710 EngTorqueMode 4;
BA_ "SPN" SG_ 2566835710 WheelBasedVehicleSpeed 84;
BA_ "SigType" SG_ 2566835710 WheelBasedVehicleSpeed 1;
BA_ "SPN" SG_ 2566835710 EngPercentLoadAtCurrentSpeed 92;
BA_ "SigType" SG_ 2566835710 EngPercentLoadAtCurrentSpeed 1;
BA_ "SPN" SG_ 2566835710 EngineCoolantTemperature 110;
BA_ "SigType" SG_ 2566835710 EngineCoolantTemperature 1;
BA_ "SigType" SG_ 2566835710 DTC1 7;
BA_ "SPN" SG_ 2566764542 ExpandedFreezeFrameLength 3149;
BA_ "SigType" SG_ 2566764542 DTC1 7;
BA_ "SPN" SG_ 2566764286 SPNSupported1High 3146;
BA_ "SPN" SG_ 2566764286 SPNSupported3High 3146;
BA_ "SPN" SG_ 2566764286 SPNSupported2High 3146;
BA_ "SPN" SG_ 2566764286 SPNSupported3 3146;
BA_ "SPN" SG_ 2566764286 SPNSupported2 3146;
BA_ "SPN" SG_ 2566764286 SPNDataLength3 3148;
BA_ "SPN" SG_ 2566764286 SPNDataLength2 3148;
BA_ "SPN" SG_ 2566764286 SPNDataLength1 3148;
BA_ "SPN" SG_ 2566764286 SPNSupported1 3146;
BA_ "SPN" SG_ 2566764030 FlashRedStopLamp 3039;
BA_ "SigType" SG_ 2566764030 FlashRedStopLamp 4;
BA_ "SPN" SG_ 2566764030 FlashProtectLamp 3041;
BA_ "SigType" SG_ 2566764030 FlashProtectLamp 4;
BA_ "SPN" SG_ 2566764030 FlashMalfuncIndicatorLamp 3038;
BA_ "SigType" SG_ 2566764030 FlashMalfuncIndicatorLamp 4;
BA_ "SPN" SG_ 2566764030 FlashAmberWarningLamp 3040;
BA_ "SigType" SG_ 2566764030 FlashAmberWarningLamp 4;
BA_ "SPN" SG_ 2566764030 MalfunctionIndicatorLampStatus 1213;
BA_ "SigType" SG_ 2566764030 MalfunctionIndicatorLampStatus 4;
BA_ "SPN" SG_ 2566764030 RedStopLampState 623;
BA_ "SigType" SG_ 2566764030 RedStopLampState 4;
BA_ "SPN" SG_ 2566764030 AmberWarningLampStatus 624;
BA_ "SigType" SG_ 2566764030 AmberWarningLampStatus 4;
BA_ "SPN" SG_ 2566764030 ProtectLampStatus 987;
BA_ "SigType" SG_ 2566764030 ProtectLampStatus 4;
BA_ "SigType" SG_ 2566764030 DTC5 7;
BA_ "SigType" SG_ 2566764030 DTC4 7;
BA_ "SigType" SG_ 2566764030 DTC3 7;
BA_ "SigType" SG_ 2566764030 DTC2 7;
BA_ "SigType" SG_ 2566764030 DTC1 7;
BA_ "SPN" SG_ 2562916094 ApplSysMonitorDenominator 3068;
BA_ "SigType" SG_ 2562916094 ApplSysMonitorDenominator 1;
BA_ "SPN" SG_ 2562916094 ApplSysMonitorNumerator 3067;
BA_ "SigType" SG_ 2562916094 ApplSysMonitorNumerator 1;
BA_ "SPN" SG_ 2562916094 SPNofApplSysMonitor 3066;
BA_ "SigType" SG_ 2562916094 SPNofApplSysMonitor 1;
BA_ "SPN" SG_ 2562916094 OBDMonitoringCondEncountered 3049;
BA_ "SigType" SG_ 2562916094 OBDMonitoringCondEncountered 1;
BA_ "SPN" SG_ 2562916094 IgnitionCycleCounter 3048;
BA_ "SigType" SG_ 2562916094 IgnitionCycleCounter 1;
BA_ "SPN" SG_ 2566835198 MalfunctionIndicatorLampStatus 1213;
BA_ "SigType" SG_ 2566835198 MalfunctionIndicatorLampStatus 4;
BA_ "SPN" SG_ 2566835198 RedStopLampState 623;
BA_ "SigType" SG_ 2566835198 RedStopLampState 4;
BA_ "SPN" SG_ 2566835198 AmberWarningLampStatus 624;
BA_ "SigType" SG_ 2566835198 AmberWarningLampStatus 4;
BA_ "SPN" SG_ 2566835198 ProtectLampStatus 987;
BA_ "SigType" SG_ 2566835198 ProtectLampStatus 4;
BA_ "SPN" SG_ 2566835198 FlashRedStopLamp 3039;
BA_ "SigType" SG_ 2566835198 FlashRedStopLamp 4;
BA_ "SPN" SG_ 2566835198 FlashProtectLamp 3041;
BA_ "SigType" SG_ 2566835198 FlashProtectLamp 4;
BA_ "SPN" SG_ 2566835198 FlashMalfuncIndicatorLamp 3038;
BA_ "SigType" SG_ 2566835198 FlashMalfuncIndicatorLamp 4;
BA_ "SPN" SG_ 2566835198 FlashAmberWarningLamp 3040;
BA_ "SigType" SG_ 2566835198 FlashAmberWarningLamp 4;
BA_ "SigType" SG_ 2566835198 DTC5 7;
BA_ "SigType" SG_ 2566835198 DTC4 7;
BA_ "SigType" SG_ 2566835198 DTC3 7;
BA_ "SigType" SG_ 2566835198 DTC2 7;
BA_ "SigType" SG_ 2566835198 DTC1 7;
BA_ "SPN" SG_ 2564030206 CalibrationID4 1635;
BA_ "SPN" SG_ 2564030206 CalibrationID3 1635;
BA_ "SPN" SG_ 2564030206 CalibrationID2 1635;
BA_ "SPN" SG_ 2564030206 CalibrationID1 1635;
BA_ "SPN" SG_ 2564030206 CalibrationVerificationNumber 1634;
BA_ "SigType" SG_ 2564030206 CalibrationVerificationNumber 1;
BA_ "SPN" SG_ 2566837502 FlashRedStopLamp 3039;
BA_ "SigType" SG_ 2566837502 FlashRedStopLamp 4;
BA_ "SPN" SG_ 2566837502 FlashProtectLamp 3041;
BA_ "SigType" SG_ 2566837502 FlashProtectLamp 4;
BA_ "SPN" SG_ 2566837502 MalfunctionIndicatorLampStatus 1213;
BA_ "SigType" SG_ 2566837502 MalfunctionIndicatorLampStatus 4;
BA_ "SPN" SG_ 2566837502 RedStopLampState 623;
BA_ "SigType" SG_ 2566837502 RedStopLampState 4;
BA_ "SPN" SG_ 2566837502 AmberWarningLampStatus 624;
BA_ "SigType" SG_ 2566837502 AmberWarningLampStatus 4;
BA_ "SPN" SG_ 2566837502 ProtectLampStatus 987;
BA_ "SigType" SG_ 2566837502 ProtectLampStatus 4;
BA_ "SPN" SG_ 2566837502 FlashMalfuncIndicatorLamp 3038;
BA_ "SigType" SG_ 2566837502 FlashMalfuncIndicatorLamp 4;
BA_ "SPN" SG_ 2566837502 FlashAmberWarningLamp 3040;
BA_ "SigType" SG_ 2566837502 FlashAmberWarningLamp 4;
BA_ "SigType" SG_ 2566837502 DTC5 7;
BA_ "SigType" SG_ 2566837502 DTC4 7;
BA_ "SigType" SG_ 2566837502 DTC3 7;
BA_ "SigType" SG_ 2566837502 DTC2 7;
BA_ "SigType" SG_ 2566837502 DTC1 7;
BA_ "SPN" SG_ 2566834942 FlashRedStopLamp 3039;
BA_ "SigType" SG_ 2566834942 FlashRedStopLamp 4;
BA_ "SPN" SG_ 2566834942 FlashProtectLamp 3041;
BA_ "SigType" SG_ 2566834942 FlashProtectLamp 4;
BA_ "SPN" SG_ 2566834942 FlashMalfuncIndicatorLamp 3038;
BA_ "SigType" SG_ 2566834942 FlashMalfuncIndicatorLamp 4;
BA_ "SPN" SG_ 2566834942 FlashAmberWarningLamp 3040;
BA_ "SigType" SG_ 2566834942 FlashAmberWarningLamp 4;
BA_ "SPN" SG_ 2566834942 MalfunctionIndicatorLampStatus 1213;
BA_ "SigType" SG_ 2566834942 MalfunctionIndicatorLampStatus 4;
BA_ "SPN" SG_ 2566834942 AmberWarningLampStatus 624;
BA_ "SigType" SG_ 2566834942 AmberWarningLampStatus 4;
BA_ "SPN" SG_ 2566834942 RedStopLampState 623;
BA_ "SigType" SG_ 2566834942 RedStopLampState 4;
BA_ "SPN" SG_ 2566834942 ProtectLampStatus 987;
BA_ "SigType" SG_ 2566834942 ProtectLampStatus 4;
BA_ "SigType" SG_ 2566834942 DTC5 7;
BA_ "SigType" SG_ 2566834942 DTC4 7;
BA_ "SigType" SG_ 2566834942 DTC3 7;
BA_ "SigType" SG_ 2566834942 DTC2 7;
BA_ "SigType" SG_ 2566834942 DTC1 7;
BA_ "SPN" SG_ 2566838526 AddressAssignment 2847;
BA_ "SigType" SG_ 2566838526 AddressAssignment 1;
BA_ "SigType" SG_ 2566838526 ManufacturerCode 1;
BA_ "SigType" SG_ 2565799678 ManufacturerCode 1;
BA_ "SPN" SG_ 2566739198 FlashRedStopLamp 3039;
BA_ "SigType" SG_ 2566739198 FlashRedStopLamp 4;
BA_ "SPN" SG_ 2566739198 FlashProtectLamp 3041;
BA_ "SigType" SG_ 2566739198 FlashProtectLamp 4;
BA_ "SPN" SG_ 2566739198 FlashMalfuncIndicatorLamp 3038;
BA_ "SigType" SG_ 2566739198 FlashMalfuncIndicatorLamp 4;
BA_ "SPN" SG_ 2566739198 FlashAmberWarningLamp 3040;
BA_ "SigType" SG_ 2566739198 FlashAmberWarningLamp 4;
BA_ "SPN" SG_ 2566739198 MalfunctionIndicatorLampStatus 1213;
BA_ "SigType" SG_ 2566739198 MalfunctionIndicatorLampStatus 4;
BA_ "SPN" SG_ 2566739198 AmberWarningLampStatus 624;
BA_ "SigType" SG_ 2566739198 AmberWarningLampStatus 4;
BA_ "SPN" SG_ 2566739198 RedStopLampState 623;
BA_ "SigType" SG_ 2566739198 RedStopLampState 4;
BA_ "SPN" SG_ 2566739198 ProtectLampStatus 987;
BA_ "SigType" SG_ 2566739198 ProtectLampStatus 4;
BA_ "SigType" SG_ 2566739198 DTC5 7;
BA_ "SigType" SG_ 2566739198 DTC4 7;
BA_ "SigType" SG_ 2566739198 DTC3 7;
BA_ "SigType" SG_ 2566739198 DTC2 7;
BA_ "SigType" SG_ 2566739198 DTC1 7;
BA_ "SPN" SG_ 2566739454 FlashRedStopLamp 3039;
BA_ "SigType" SG_ 2566739454 FlashRedStopLamp 4;
BA_ "SPN" SG_ 2566739454 FlashProtectLamp 3041;
BA_ "SigType" SG_ 2566739454 FlashProtectLamp 4;
BA_ "SPN" SG_ 2566739454 FlashMalfuncIndicatorLamp 3038;
BA_ "SigType" SG_ 2566739454 FlashMalfuncIndicatorLamp 4;
BA_ "SPN" SG_ 2566739454 FlashAmberWarningLamp 3040;
BA_ "SigType" SG_ 2566739454 FlashAmberWarningLamp 4;
BA_ "SPN" SG_ 2566739454 MalfunctionIndicatorLampStatus 1213;
BA_ "SigType" SG_ 2566739454 MalfunctionIndicatorLampStatus 4;
BA_ "SPN" SG_ 2566739454 AmberWarningLampStatus 624;
BA_ "SigType" SG_ 2566739454 AmberWarningLampStatus 4;
BA_ "SPN" SG_ 2566739454 RedStopLampState 623;
BA_ "SigType" SG_ 2566739454 RedStopLampState 4;
BA_ "SPN" SG_ 2566739454 ProtectLampStatus 987;
BA_ "SigType" SG_ 2566739454 ProtectLampStatus 4;
BA_ "SigType" SG_ 2566739454 DTC5 7;
BA_ "SigType" SG_ 2566739454 DTC4 7;
BA_ "SigType" SG_ 2566739454 DTC3 7;
BA_ "SigType" SG_ 2566739454 DTC2 7;
BA_ "SigType" SG_ 2566739454 DTC1 7;
BA_ "SPN" SG_ 2566739710 FlashRedStopLamp 3039;
BA_ "SigType" SG_ 2566739710 FlashRedStopLamp 4;
BA_ "SPN" SG_ 2566739710 FlashProtectLamp 3041;
BA_ "SigType" SG_ 2566739710 FlashProtectLamp 4;
BA_ "SPN" SG_ 2566739710 FlashMalfuncIndicatorLamp 3038;
BA_ "SigType" SG_ 2566739710 FlashMalfuncIndicatorLamp 4;
BA_ "SPN" SG_ 2566739710 FlashAmberWarningLamp 3040;
BA_ "SigType" SG_ 2566739710 FlashAmberWarningLamp 4;
BA_ "SPN" SG_ 2566739710 MalfunctionIndicatorLampStatus 1213;
BA_ "SigType" SG_ 2566739710 MalfunctionIndicatorLampStatus 4;
BA_ "SPN" SG_ 2566739710 AmberWarningLampStatus 624;
BA_ "SigType" SG_ 2566739710 AmberWarningLampStatus 4;
BA_ "SPN" SG_ 2566739710 RedStopLampState 623;
BA_ "SigType" SG_ 2566739710 RedStopLampState 4;
BA_ "SPN" SG_ 2566739710 ProtectLampStatus 987;
BA_ "SigType" SG_ 2566739710 ProtectLampStatus 4;
BA_ "SigType" SG_ 2566739710 DTC5 7;
BA_ "SigType" SG_ 2566739710 DTC4 7;
BA_ "SigType" SG_ 2566739710 DTC3 7;
BA_ "SigType" SG_ 2566739710 DTC2 7;
BA_ "SigType" SG_ 2566739710 DTC1 7;
BA_ "SPN" SG_ 2566739966 FlashRedStopLamp 3039;
BA_ "SigType" SG_ 2566739966 FlashRedStopLamp 4;
BA_ "SPN" SG_ 2566739966 FlashProtectLamp 3041;
BA_ "SigType" SG_ 2566739966 FlashProtectLamp 4;
BA_ "SPN" SG_ 2566739966 FlashMalfuncIndicatorLamp 3038;
BA_ "SigType" SG_ 2566739966 FlashMalfuncIndicatorLamp 4;
BA_ "SPN" SG_ 2566739966 FlashAmberWarningLamp 3040;
BA_ "SigType" SG_ 2566739966 FlashAmberWarningLamp 4;
BA_ "SPN" SG_ 2566739966 MalfunctionIndicatorLampStatus 1213;
BA_ "SigType" SG_ 2566739966 MalfunctionIndicatorLampStatus 4;
BA_ "SPN" SG_ 2566739966 AmberWarningLampStatus 624;
BA_ "SigType" SG_ 2566739966 AmberWarningLampStatus 4;
BA_ "SPN" SG_ 2566739966 RedStopLampState 623;
BA_ "SigType" SG_ 2566739966 RedStopLampState 4;
BA_ "SPN" SG_ 2566739966 ProtectLampStatus 987;
BA_ "SigType" SG_ 2566739966 ProtectLampStatus 4;
BA_ "SigType" SG_ 2566739966 DTC5 7;
BA_ "SigType" SG_ 2566739966 DTC4 7;
BA_ "SigType" SG_ 2566739966 DTC3 7;
BA_ "SigType" SG_ 2566739966 DTC2 7;
BA_ "SigType" SG_ 2566739966 DTC1 7;
BA_ "SPN" SG_ 2566740222 FlashRedStopLamp 3039;
BA_ "SigType" SG_ 2566740222 FlashRedStopLamp 4;
BA_ "SPN" SG_ 2566740222 FlashProtectLamp 3041;
BA_ "SigType" SG_ 2566740222 FlashProtectLamp 4;
BA_ "SPN" SG_ 2566740222 FlashMalfuncIndicatorLamp 3038;
BA_ "SigType" SG_ 2566740222 FlashMalfuncIndicatorLamp 4;
BA_ "SPN" SG_ 2566740222 FlashAmberWarningLamp 3040;
BA_ "SigType" SG_ 2566740222 FlashAmberWarningLamp 4;
BA_ "SPN" SG_ 2566740222 MalfunctionIndicatorLampStatus 1213;
BA_ "SigType" SG_ 2566740222 MalfunctionIndicatorLampStatus 4;
BA_ "SPN" SG_ 2566740222 AmberWarningLampStatus 624;
BA_ "SigType" SG_ 2566740222 AmberWarningLampStatus 4;
BA_ "SPN" SG_ 2566740222 RedStopLampState 623;
BA_ "SigType" SG_ 2566740222 RedStopLampState 4;
BA_ "SPN" SG_ 2566740222 ProtectLampStatus 987;
BA_ "SigType" SG_ 2566740222 ProtectLampStatus 4;
BA_ "SigType" SG_ 2566740222 DTC5 7;
BA_ "SigType" SG_ 2566740222 DTC4 7;
BA_ "SigType" SG_ 2566740222 DTC3 7;
BA_ "SigType" SG_ 2566740222 DTC2 7;
BA_ "SigType" SG_ 2566740222 DTC1 7;
BA_ "SPN" SG_ 2566740478 FlashRedStopLamp 3039;
BA_ "SigType" SG_ 2566740478 FlashRedStopLamp 4;
BA_ "SPN" SG_ 2566740478 FlashProtectLamp 3041;
BA_ "SigType" SG_ 2566740478 FlashProtectLamp 4;
BA_ "SPN" SG_ 2566740478 FlashMalfuncIndicatorLamp 3038;
BA_ "SigType" SG_ 2566740478 FlashMalfuncIndicatorLamp 4;
BA_ "SPN" SG_ 2566740478 FlashAmberWarningLamp 3040;
BA_ "SigType" SG_ 2566740478 FlashAmberWarningLamp 4;
BA_ "SPN" SG_ 2566740478 MalfunctionIndicatorLampStatus 1213;
BA_ "SigType" SG_ 2566740478 MalfunctionIndicatorLampStatus 4;
BA_ "SPN" SG_ 2566740478 AmberWarningLampStatus 624;
BA_ "SigType" SG_ 2566740478 AmberWarningLampStatus 4;
BA_ "SPN" SG_ 2566740478 RedStopLampState 623;
BA_ "SigType" SG_ 2566740478 RedStopLampState 4;
BA_ "SPN" SG_ 2566740478 ProtectLampStatus 987;
BA_ "SigType" SG_ 2566740478 ProtectLampStatus 4;
BA_ "SigType" SG_ 2566740478 DTC5 7;
BA_ "SigType" SG_ 2566740478 DTC4 7;
BA_ "SigType" SG_ 2566740478 DTC3 7;
BA_ "SigType" SG_ 2566740478 DTC2 7;
BA_ "SigType" SG_ 2566740478 DTC1 7;
BA_ "SPN" SG_ 2566740734 FlashRedStopLamp 3039;
BA_ "SigType" SG_ 2566740734 FlashRedStopLamp 4;
BA_ "SPN" SG_ 2566740734 FlashProtectLamp 3041;
BA_ "SigType" SG_ 2566740734 FlashProtectLamp 4;
BA_ "SPN" SG_ 2566740734 FlashMalfuncIndicatorLamp 3038;
BA_ "SigType" SG_ 2566740734 FlashMalfuncIndicatorLamp 4;
BA_ "SPN" SG_ 2566740734 FlashAmberWarningLamp 3040;
BA_ "SigType" SG_ 2566740734 FlashAmberWarningLamp 4;
BA_ "SPN" SG_ 2566740734 MalfunctionIndicatorLampStatus 1213;
BA_ "SigType" SG_ 2566740734 MalfunctionIndicatorLampStatus 4;
BA_ "SPN" SG_ 2566740734 AmberWarningLampStatus 624;
BA_ "SigType" SG_ 2566740734 AmberWarningLampStatus 4;
BA_ "SPN" SG_ 2566740734 RedStopLampState 623;
BA_ "SigType" SG_ 2566740734 RedStopLampState 4;
BA_ "SPN" SG_ 2566740734 ProtectLampStatus 987;
BA_ "SigType" SG_ 2566740734 ProtectLampStatus 4;
BA_ "SigType" SG_ 2566740734 DTC5 7;
BA_ "SigType" SG_ 2566740734 DTC4 7;
BA_ "SigType" SG_ 2566740734 DTC3 7;
BA_ "SigType" SG_ 2566740734 DTC2 7;
BA_ "SigType" SG_ 2566740734 DTC1 7;
BA_ "SPN" SG_ 2566740990 FlashRedStopLamp 3039;
BA_ "SigType" SG_ 2566740990 FlashRedStopLamp 4;
BA_ "SPN" SG_ 2566740990 FlashProtectLamp 3041;
BA_ "SigType" SG_ 2566740990 FlashProtectLamp 4;
BA_ "SPN" SG_ 2566740990 FlashMalfuncIndicatorLamp 3038;
BA_ "SigType" SG_ 2566740990 FlashMalfuncIndicatorLamp 4;
BA_ "SPN" SG_ 2566740990 FlashAmberWarningLamp 3040;
BA_ "SigType" SG_ 2566740990 FlashAmberWarningLamp 4;
BA_ "SPN" SG_ 2566740990 MalfunctionIndicatorLampStatus 1213;
BA_ "SigType" SG_ 2566740990 MalfunctionIndicatorLampStatus 4;
BA_ "SPN" SG_ 2566740990 AmberWarningLampStatus 624;
BA_ "SigType" SG_ 2566740990 AmberWarningLampStatus 4;
BA_ "SPN" SG_ 2566740990 RedStopLampState 623;
BA_ "SigType" SG_ 2566740990 RedStopLampState 4;
BA_ "SPN" SG_ 2566740990 ProtectLampStatus 987;
BA_ "SigType" SG_ 2566740990 ProtectLampStatus 4;
BA_ "SigType" SG_ 2566740990 DTC5 7;
BA_ "SigType" SG_ 2566740990 DTC4 7;
BA_ "SigType" SG_ 2566740990 DTC3 7;
BA_ "SigType" SG_ 2566740990 DTC2 7;
BA_ "SigType" SG_ 2566740990 DTC1 7;
BA_ "SPN" SG_ 2566741246 FlashRedStopLamp 3039;
BA_ "SigType" SG_ 2566741246 FlashRedStopLamp 4;
BA_ "SPN" SG_ 2566741246 FlashProtectLamp 3041;
BA_ "SigType" SG_ 2566741246 FlashProtectLamp 4;
BA_ "SPN" SG_ 2566741246 FlashMalfuncIndicatorLamp 3038;
BA_ "SigType" SG_ 2566741246 FlashMalfuncIndicatorLamp 4;
BA_ "SPN" SG_ 2566741246 FlashAmberWarningLamp 3040;
BA_ "SigType" SG_ 2566741246 FlashAmberWarningLamp 4;
BA_ "SPN" SG_ 2566741246 MalfunctionIndicatorLampStatus 1213;
BA_ "SigType" SG_ 2566741246 MalfunctionIndicatorLampStatus 4;
BA_ "SPN" SG_ 2566741246 AmberWarningLampStatus 624;
BA_ "SigType" SG_ 2566741246 AmberWarningLampStatus 4;
BA_ "SPN" SG_ 2566741246 RedStopLampState 623;
BA_ "SigType" SG_ 2566741246 RedStopLampState 4;
BA_ "SPN" SG_ 2566741246 ProtectLampStatus 987;
BA_ "SigType" SG_ 2566741246 ProtectLampStatus 4;
BA_ "SigType" SG_ 2566741246 DTC5 7;
BA_ "SigType" SG_ 2566741246 DTC4 7;
BA_ "SigType" SG_ 2566741246 DTC3 7;
BA_ "SigType" SG_ 2566741246 DTC2 7;
BA_ "SigType" SG_ 2566741246 DTC1 7;
BA_ "SPN" SG_ 2566741502 FlashRedStopLamp 3039;
BA_ "SigType" SG_ 2566741502 FlashRedStopLamp 4;
BA_ "SPN" SG_ 2566741502 FlashProtectLamp 3041;
BA_ "SigType" SG_ 2566741502 FlashProtectLamp 4;
BA_ "SPN" SG_ 2566741502 FlashMalfuncIndicatorLamp 3038;
BA_ "SigType" SG_ 2566741502 FlashMalfuncIndicatorLamp 4;
BA_ "SPN" SG_ 2566741502 FlashAmberWarningLamp 3040;
BA_ "SigType" SG_ 2566741502 FlashAmberWarningLamp 4;
BA_ "SPN" SG_ 2566741502 MalfunctionIndicatorLampStatus 1213;
BA_ "SigType" SG_ 2566741502 MalfunctionIndicatorLampStatus 4;
BA_ "SPN" SG_ 2566741502 AmberWarningLampStatus 624;
BA_ "SigType" SG_ 2566741502 AmberWarningLampStatus 4;
BA_ "SPN" SG_ 2566741502 RedStopLampState 623;
BA_ "SigType" SG_ 2566741502 RedStopLampState 4;
BA_ "SPN" SG_ 2566741502 ProtectLampStatus 987;
BA_ "SigType" SG_ 2566741502 ProtectLampStatus 4;
BA_ "SigType" SG_ 2566741502 DTC5 7;
BA_ "SigType" SG_ 2566741502 DTC4 7;
BA_ "SigType" SG_ 2566741502 DTC3 7;
BA_ "SigType" SG_ 2566741502 DTC2 7;
BA_ "SigType" SG_ 2566741502 DTC1 7;
BA_ "SPN" SG_ 2566741758 FlashRedStopLamp 3039;
BA_ "SigType" SG_ 2566741758 FlashRedStopLamp 4;
BA_ "SPN" SG_ 2566741758 FlashProtectLamp 3041;
BA_ "SigType" SG_ 2566741758 FlashProtectLamp 4;
BA_ "SPN" SG_ 2566741758 FlashMalfuncIndicatorLamp 3038;
BA_ "SigType" SG_ 2566741758 FlashMalfuncIndicatorLamp 4;
BA_ "SPN" SG_ 2566741758 FlashAmberWarningLamp 3040;
BA_ "SigType" SG_ 2566741758 FlashAmberWarningLamp 4;
BA_ "SPN" SG_ 2566741758 MalfunctionIndicatorLampStatus 1213;
BA_ "SigType" SG_ 2566741758 MalfunctionIndicatorLampStatus 4;
BA_ "SPN" SG_ 2566741758 AmberWarningLampStatus 624;
BA_ "SigType" SG_ 2566741758 AmberWarningLampStatus 4;
BA_ "SPN" SG_ 2566741758 RedStopLampState 623;
BA_ "SigType" SG_ 2566741758 RedStopLampState 4;
BA_ "SPN" SG_ 2566741758 ProtectLampStatus 987;
BA_ "SigType" SG_ 2566741758 ProtectLampStatus 4;
BA_ "SigType" SG_ 2566741758 DTC5 7;
BA_ "SigType" SG_ 2566741758 DTC4 7;
BA_ "SigType" SG_ 2566741758 DTC3 7;
BA_ "SigType" SG_ 2566741758 DTC2 7;
BA_ "SigType" SG_ 2566741758 DTC1 7;
BA_ "SPN" SG_ 2566742014 FlashRedStopLamp 3039;
BA_ "SigType" SG_ 2566742014 FlashRedStopLamp 4;
BA_ "SPN" SG_ 2566742014 FlashProtectLamp 3041;
BA_ "SigType" SG_ 2566742014 FlashProtectLamp 4;
BA_ "SPN" SG_ 2566742014 FlashMalfuncIndicatorLamp 3038;
BA_ "SigType" SG_ 2566742014 FlashMalfuncIndicatorLamp 4;
BA_ "SPN" SG_ 2566742014 FlashAmberWarningLamp 3040;
BA_ "SigType" SG_ 2566742014 FlashAmberWarningLamp 4;
BA_ "SPN" SG_ 2566742014 MalfunctionIndicatorLampStatus 1213;
BA_ "SigType" SG_ 2566742014 MalfunctionIndicatorLampStatus 4;
BA_ "SPN" SG_ 2566742014 AmberWarningLampStatus 624;
BA_ "SigType" SG_ 2566742014 AmberWarningLampStatus 4;
BA_ "SPN" SG_ 2566742014 RedStopLampState 623;
BA_ "SigType" SG_ 2566742014 RedStopLampState 4;
BA_ "SPN" SG_ 2566742014 ProtectLampStatus 987;
BA_ "SigType" SG_ 2566742014 ProtectLampStatus 4;
BA_ "SigType" SG_ 2566742014 DTC5 7;
BA_ "SigType" SG_ 2566742014 DTC4 7;
BA_ "SigType" SG_ 2566742014 DTC3 7;
BA_ "SigType" SG_ 2566742014 DTC2 7;
BA_ "SigType" SG_ 2566742014 DTC1 7;
BA_ "SPN" SG_ 2560622334 FlashRedStopLamp 3039;
BA_ "SigType" SG_ 2560622334 FlashRedStopLamp 4;
BA_ "SPN" SG_ 2560622334 FlashProtectLamp 3041;
BA_ "SigType" SG_ 2560622334 FlashProtectLamp 4;
BA_ "SPN" SG_ 2560622334 FlashMalfuncIndicatorLamp 3038;
BA_ "SigType" SG_ 2560622334 FlashMalfuncIndicatorLamp 4;
BA_ "SPN" SG_ 2560622334 FlashAmberWarningLamp 3040;
BA_ "SigType" SG_ 2560622334 FlashAmberWarningLamp 4;
BA_ "SPN" SG_ 2560622334 MalfunctionIndicatorLampStatus 1213;
BA_ "SigType" SG_ 2560622334 MalfunctionIndicatorLampStatus 4;
BA_ "SPN" SG_ 2560622334 AmberWarningLampStatus 624;
BA_ "SigType" SG_ 2560622334 AmberWarningLampStatus 4;
BA_ "SPN" SG_ 2560622334 RedStopLampState 623;
BA_ "SigType" SG_ 2560622334 RedStopLampState 4;
BA_ "SPN" SG_ 2560622334 ProtectLampStatus 987;
BA_ "SigType" SG_ 2560622334 ProtectLampStatus 4;
BA_ "SigType" SG_ 2560622334 DTC5 7;
BA_ "SigType" SG_ 2560622334 DTC4 7;
BA_ "SigType" SG_ 2560622334 DTC3 7;
BA_ "SigType" SG_ 2560622334 DTC2 7;
BA_ "SigType" SG_ 2560622334 DTC1 7;
BA_ "SPN" SG_ 2566750462 FlashRedStopLamp 3039;
BA_ "SigType" SG_ 2566750462 FlashRedStopLamp 4;
BA_ "SPN" SG_ 2566750462 FlashProtectLamp 3041;
BA_ "SigType" SG_ 2566750462 FlashProtectLamp 4;
BA_ "SPN" SG_ 2566750462 FlashMalfuncIndicatorLamp 3038;
BA_ "SigType" SG_ 2566750462 FlashMalfuncIndicatorLamp 4;
BA_ "SPN" SG_ 2566750462 FlashAmberWarningLamp 3040;
BA_ "SigType" SG_ 2566750462 FlashAmberWarningLamp 4;
BA_ "SPN" SG_ 2566750462 MalfunctionIndicatorLampStatus 1213;
BA_ "SigType" SG_ 2566750462 MalfunctionIndicatorLampStatus 4;
BA_ "SPN" SG_ 2566750462 AmberWarningLampStatus 624;
BA_ "SigType" SG_ 2566750462 AmberWarningLampStatus 4;
BA_ "SPN" SG_ 2566750462 RedStopLampState 623;
BA_ "SigType" SG_ 2566750462 RedStopLampState 4;
BA_ "SPN" SG_ 2566750462 ProtectLampStatus 987;
BA_ "SigType" SG_ 2566750462 ProtectLampStatus 4;
BA_ "SigType" SG_ 2566750462 DTC5 7;
BA_ "SigType" SG_ 2566750462 DTC4 7;
BA_ "SigType" SG_ 2566750462 DTC3 7;
BA_ "SigType" SG_ 2566750462 DTC2 7;
BA_ "SigType" SG_ 2566750462 DTC1 7;
BA_ "SPN" SG_ 2566750974 FlashRedStopLamp 3039;
BA_ "SigType" SG_ 2566750974 FlashRedStopLamp 4;
BA_ "SPN" SG_ 2566750974 FlashProtectLamp 3041;
BA_ "SigType" SG_ 2566750974 FlashProtectLamp 4;
BA_ "SPN" SG_ 2566750974 FlashMalfuncIndicatorLamp 3038;
BA_ "SigType" SG_ 2566750974 FlashMalfuncIndicatorLamp 4;
BA_ "SPN" SG_ 2566750974 FlashAmberWarningLamp 3040;
BA_ "SigType" SG_ 2566750974 FlashAmberWarningLamp 4;
BA_ "SPN" SG_ 2566750974 MalfunctionIndicatorLampStatus 1213;
BA_ "SigType" SG_ 2566750974 MalfunctionIndicatorLampStatus 4;
BA_ "SPN" SG_ 2566750974 AmberWarningLampStatus 624;
BA_ "SigType" SG_ 2566750974 AmberWarningLampStatus 4;
BA_ "SPN" SG_ 2566750974 RedStopLampState 623;
BA_ "SigType" SG_ 2566750974 RedStopLampState 4;
BA_ "SPN" SG_ 2566750974 ProtectLampStatus 987;
BA_ "SigType" SG_ 2566750974 ProtectLampStatus 4;
BA_ "SigType" SG_ 2566750974 DTC5 7;
BA_ "SigType" SG_ 2566750974 DTC4 7;
BA_ "SigType" SG_ 2566750974 DTC3 7;
BA_ "SigType" SG_ 2566750974 DTC2 7;
BA_ "SigType" SG_ 2566750974 DTC1 7;
BA_ "SPN" SG_ 2565406462 ControlByte 2541;
BA_ "SPN" SG_ 2565406462 ParameterGroupNumber 2574;
BA_ "SigType" SG_ 2565406462 ParameterGroupNumber 6;
BA_ "SPN" SG_ 2565406462 GroupFunctionValue 2542;
BA_ "SigType" SG_ 2565406462 GroupFunctionValue 1;
BA_ "SPN" SG_ 2633869310 VoltageRegulatorEnabled 3379;
BA_ "SigType" SG_ 2633869310 VoltageRegulatorEnabled 4;
BA_ "SPN" SG_ 2633869310 VoltageRegulatorSoftStartState 3378;
BA_ "SigType" SG_ 2633869310 VoltageRegulatorSoftStartState 4;
BA_ "SPN" SG_ 2633869310 VltgRgltrUndrfrqncyCmpnstnEnbld 3377;
BA_ "SigType" SG_ 2633869310 VltgRgltrUndrfrqncyCmpnstnEnbld 4;
BA_ "SPN" SG_ 2633869310 VltgRgltrVAr_PwrFctrOprtingMode 3376;
BA_ "SPN" SG_ 2633869310 VltgRglatorLoadCompensationMode 3375;
BA_ "SPN" SG_ 2365433598 GnrtrOtputVoltageBiasPercentage 3382;
BA_ "SigType" SG_ 2365433598 GnrtrOtputVoltageBiasPercentage 1;
BA_ "SPN" SG_ 2365433598 GeneratorExcitationFieldCurrent 3381;
BA_ "SigType" SG_ 2365433598 GeneratorExcitationFieldCurrent 1;
BA_ "SPN" SG_ 2365433598 GeneratorExcitationFieldVoltage 3380;
BA_ "SigType" SG_ 2365433598 GeneratorExcitationFieldVoltage 1;
VAL_ 3221225472 TirePressThresholdDetection 7 "NotAvailable" 6 "ErrorIndicator" 5 "NotDefined" 4 "ExtrmUndrPrssTrPrssrIsAtALvlWhr" 3 "UndrPrssTrPrssrIsLwrThnThPrssrD" 2 "NWrnngPrssTrPrssrIsWthnThThrshl" 1 "OvrPrssTrPrssrIsHghrThnThPrssrD" 0 "ExtrmOvrPrssTrPrssrIsAtALvlWhrT" ;
VAL_ 3221225472 CTIWheelEndElectricalFault 3 "NotSupported" 2 "Error" 1 "NotDefined" 0 "Ok" ;
VAL_ 3221225472 CTITireStatus 3 "NotSupported" 2 "Error" 1 "TireLeakDetected" 0 "Ok" ;
VAL_ 3221225472 CTIWheelSensorStatus 3 "NotSupported" 2 "NotDefined" 1 "On" 0 "Off_IsolatedFromCTIPressCtrl" ;
VAL_ 2564554494 FlowStatus 2 "Overflow" 1 "Wait " 0 "Continue To Send" ;
VAL_ 2564554494 ProtocolCtrlInformation 3 "Flow control " 2 "Consecutive frame" 1 "First frame" 0 "Single frame" ;
VAL_ 2564488958 FlowStatus 2 "Overflow" 1 "Wait " 0 "Continue To Send" ;
VAL_ 2564488958 ProtocolCtrlInformation 3 "Flow control " 2 "Consecutive frame" 1 "First frame" 0 "Single frame" ;
VAL_ 2566765822 DriversFareboxSecurityCode 1 "SecurityCode" 0 "Farebox is in reporting status" ;
VAL_ 2566765822 FarePresets 16 "to11111111ReservedForAssignment" 0 "to00001111AgencyDefined" ;
VAL_ 2566765822 TripDirection 6 "1111AgencyDefined" 5 "Out" 4 "In" 3 "West" 2 "East" 1 "South" 0 "North" ;
VAL_ 2566765822 TripStatus 6 "LayoverEnd" 5 "LayoverStart" 2 "TripEnd" 1 "TripStart" 7 "Undefined" ;
VAL_ 2566765822 FareboxServiceStatus 3 "NotAvailable" 2 "ErrorCondition" 1 "FareboxInService" 0 "FareboxOutOfService" ;
VAL_ 2566840830 RetarderLocation 15 "NotAvailable" 14 "Other" 6 "1101NotDefined" 5 "Trailer" 4 "Driveline" 3 "TransOutput" 2 "TransInput" 1 "EngExhaustBrake" 0 "EngCompressionReleaseBrake" ;
VAL_ 2566840830 RetarderType 15 "NotAvailable" 14 "Other" 5 "1101NotDefined" 4 "Exhaust" 3 "CompressionRelease" 2 "CooledFriction" 1 "Hyd" 0 "Electric_Magnetic" ;
VAL_ 2566820094 EngTorqueLimitFeature 7 "NotAvailable" 5 "110Reserved" 4 "CurrentTorqueRating" 3 "PreviousTorqueRating" 2 "FirstTorqueRating" 1 "HighestTorqueRating" 0 "Reserved" ;
VAL_ 2566820094 TorqueLimitingFeatureStatus 3 "NotAvailable" 2 "Error" 1 "Enabled" 0 "Disabled" ;
VAL_ 2566841342 SupportTSC1CtrlPurposeGroup4 1 "P25ReservedForAssignmentBySAE" ;
VAL_ 2566841342 SupportTSC1CtrlPurposeGroup3 1 "P17ReservedForAssignmentBySAE" ;
VAL_ 2566841342 SupportTSC1CtrlPurposeGroup2 1 "P9ReservedForAssignmentBySAE" ;
VAL_ 2566841342 SupportTSC1CtrlPurposeGroup1 1 "P1AccelPedal_OperatorSelection" ;
VAL_ 2566841342 SupportVariableRateTSC1Message 1 "MsTransRate" ;
VAL_ 2560950014 FailureModeIdentifier1 31 "Not available" 19 "Received network data in error" 18 "Below normal (moderately severe)" 17 "Below normal (least severe)" 16 "Above normal (moderately severe)" 15 "Above normal (least severe)" 14 "Special intstructions" 13 "Out of calibration" 12 "Bad intelligent device" 11 "Root cause not known" 10 "Abnormal rate of change" 9 "Abnormal update rate" 8 "Abnormal frequency" 7 "Mechanical system not responding" 6 "Current above normal" 5 "Current below normal" 4 "Voltage below normal" 3 "Voltage above normal" 2 "Data erratic" 1 "Below normal (most severe)" 0 "Above normal (most severe)" ;
VAL_ 2566836222 FlashRedStopLamp 3 "Unavailable / Do Not Flash" 2 "Reserved" 1 "Fast Flash" 0 "Slow Flash" ;
VAL_ 2566836222 FlashProtectLamp 3 "Unavailable / Do Not Flash" 2 "Reserved" 1 "Fast Flash" 0 "Slow Flash" ;
VAL_ 2566836222 FlashMalfuncIndicatorLamp 3 "Unavailable / Do Not Flash" 2 "Reserved" 1 "Fast Flash" 0 "Slow Flash" ;
VAL_ 2566836222 FlashAmberWarningLamp 3 "Unavailable / Do Not Flash" 2 "Reserved" 1 "Fast Flash" 0 "Slow Flash" ;
VAL_ 2566836222 MalfunctionIndicatorLampStatus 3 "Not available" 2 "Reserved" 1 "Lamp on" 0 "Lamp off" ;
VAL_ 2566836222 RedStopLampState 3 "Not available" 2 "Reserved" 1 "Lamp on" 0 "Lamp off" ;
VAL_ 2566836222 AmberWarningLampStatus 3 "Not available" 2 "Reserved" 1 "Lamp on" 0 "Lamp off" ;
VAL_ 2566836222 ProtectLampStatus 3 "Not available" 2 "Reserved" 1 "Lamp on" 0 "Lamp off" ;
VAL_ 2566835710 EngTorqueMode 15 "Not available" 11 "Remote accelerator" 10 "Braking system" 9 "High speed governor" 8 "Torque limiting" 7 "ABS control" 6 "Transmission control" 5 "ASR control" 4 "Road speed governor" 3 "PTO governor" 2 "Cruise control" 1 "Accelerator pedal/operator selec" 0 "Low idle governor/no request (de" ;
VAL_ 2566764286 SPNSupportTypeSTR3 1 "SupportedInScaledTestResults" 0 "NotSupportedInScaledTestResults" ;
VAL_ 2566764286 SPNSupportTypeSTR2 1 "SupportedInScaledTestResults" 0 "NotSupportedInScaledTestResults" ;
VAL_ 2566764286 SPNSupportTypeEFF3 1 "SupportedInExFreezeFrame" 0 "NotSupportedInExFreezeFrame" ;
VAL_ 2566764286 SPNSupportTypeEFF2 1 "SupportedInExFreezeFrame" 0 "NotSupportedInExFreezeFrame" ;
VAL_ 2566764286 SPNSupportTypeDS3 1 "SupportedInDataStream" 0 "NotSupportedInDataStream" ;
VAL_ 2566764286 SPNSupportTypeDS2 1 "SupportedInDataStream" 0 "NotSupportedInDataStream" ;
VAL_ 2566764286 SPNSupportTypeSTR1 1 "SupportedInScaledTestResults" 0 "NotSupportedInScaledTestResults" ;
VAL_ 2566764286 SPNSupportTypeDS1 1 "SupportedInDataStream" 0 "NotSupportedInDataStream" ;
VAL_ 2566764286 SPNSupportTypeEFF1 1 "SupportedInExFreezeFrame" 0 "NotSupportedInExFreezeFrame" ;
VAL_ 2566764030 FlashRedStopLamp 3 "Unavailable / Do Not Flash" 2 "Reserved" 1 "Fast Flash" 0 "Slow Flash" ;
VAL_ 2566764030 FlashProtectLamp 3 "Unavailable / Do Not Flash" 2 "Reserved" 1 "Fast Flash" 0 "Slow Flash" ;
VAL_ 2566764030 FlashMalfuncIndicatorLamp 3 "Unavailable / Do Not Flash" 2 "Reserved" 1 "Fast Flash" 0 "Slow Flash" ;
VAL_ 2566764030 FlashAmberWarningLamp 3 "Unavailable / Do Not Flash" 2 "Reserved" 1 "Fast Flash" 0 "Slow Flash" ;
VAL_ 2566764030 MalfunctionIndicatorLampStatus 3 "Not available" 2 "Reserved" 1 "Lamp on" 0 "Lamp off" ;
VAL_ 2566764030 RedStopLampState 3 "Not available" 2 "Reserved" 1 "Lamp on" 0 "Lamp off" ;
VAL_ 2566764030 AmberWarningLampStatus 3 "Not available" 2 "Reserved" 1 "Lamp on" 0 "Lamp off" ;
VAL_ 2566764030 ProtectLampStatus 3 "Not available" 2 "Reserved" 1 "Lamp on" 0 "Lamp off" ;
VAL_ 2566835198 MalfunctionIndicatorLampStatus 3 "Not available" 2 "Reserved" 1 "Lamp on" 0 "Lamp off" ;
VAL_ 2566835198 RedStopLampState 3 "Not available" 2 "Reserved" 1 "Lamp on" 0 "Lamp off" ;
VAL_ 2566835198 AmberWarningLampStatus 3 "Not available" 2 "Reserved" 1 "Lamp on" 0 "Lamp off" ;
VAL_ 2566835198 ProtectLampStatus 3 "Not available" 2 "Reserved" 1 "Lamp on" 0 "Lamp off" ;
VAL_ 2566835198 FlashRedStopLamp 3 "Unavailable / Do Not Flash" 2 "Reserved" 1 "Fast Flash" 0 "Slow Flash" ;
VAL_ 2566835198 FlashProtectLamp 3 "Unavailable / Do Not Flash" 2 "Reserved" 1 "Fast Flash" 0 "Slow Flash" ;
VAL_ 2566835198 FlashMalfuncIndicatorLamp 3 "Unavailable / Do Not Flash" 2 "Reserved" 1 "Fast Flash" 0 "Slow Flash" ;
VAL_ 2566835198 FlashAmberWarningLamp 3 "Unavailable / Do Not Flash" 2 "Reserved" 1 "Fast Flash" 0 "Slow Flash" ;
VAL_ 2566837502 FlashRedStopLamp 3 "Unavailable / Do Not Flash" 2 "Reserved" 1 "Fast Flash" 0 "Slow Flash" ;
VAL_ 2566837502 FlashProtectLamp 3 "Unavailable / Do Not Flash" 2 "Reserved" 1 "Fast Flash" 0 "Slow Flash" ;
VAL_ 2566837502 MalfunctionIndicatorLampStatus 3 "Not available" 2 "Reserved" 1 "Lamp on" 0 "Lamp off" ;
VAL_ 2566837502 RedStopLampState 3 "Not available" 2 "Reserved" 1 "Lamp on" 0 "Lamp off" ;
VAL_ 2566837502 AmberWarningLampStatus 3 "Not available" 2 "Reserved" 1 "Lamp on" 0 "Lamp off" ;
VAL_ 2566837502 ProtectLampStatus 3 "Not available" 2 "Reserved" 1 "Lamp on" 0 "Lamp off" ;
VAL_ 2566837502 FlashMalfuncIndicatorLamp 3 "Unavailable / Do Not Flash" 2 "Reserved" 1 "Fast Flash" 0 "Slow Flash" ;
VAL_ 2566837502 FlashAmberWarningLamp 3 "Unavailable / Do Not Flash" 2 "Reserved" 1 "Fast Flash" 0 "Slow Flash" ;
VAL_ 2566834942 FlashRedStopLamp 3 "Unavailable / Do Not Flash" 2 "Reserved" 1 "Fast Flash" 0 "Slow Flash" ;
VAL_ 2566834942 FlashProtectLamp 3 "Unavailable / Do Not Flash" 2 "Reserved" 1 "Fast Flash" 0 "Slow Flash" ;
VAL_ 2566834942 FlashMalfuncIndicatorLamp 3 "Unavailable / Do Not Flash" 2 "Reserved" 1 "Fast Flash" 0 "Slow Flash" ;
VAL_ 2566834942 FlashAmberWarningLamp 3 "Unavailable / Do Not Flash" 2 "Reserved" 1 "Fast Flash" 0 "Slow Flash" ;
VAL_ 2566834942 MalfunctionIndicatorLampStatus 3 "Not available" 2 "Reserved" 1 "Lamp on" 0 "Lamp off" ;
VAL_ 2566834942 AmberWarningLampStatus 3 "Not available" 2 "Reserved" 1 "Lamp on" 0 "Lamp off" ;
VAL_ 2566834942 RedStopLampState 3 "Not available" 2 "Reserved" 1 "Lamp on" 0 "Lamp off" ;
VAL_ 2566834942 ProtectLampStatus 3 "Not available" 2 "Reserved" 1 "Lamp on" 0 "Lamp off" ;
VAL_ 2566838526 IndustryGroup 6 "Reserved for SAE0" 7 "Reserved for SAE1" 5 "IndustrialProcessCtrlStationary" 4 "Marine" 3 "Construction" 2 "Agricultural and Forestry" 1 "On-Highway" 0 "Global" ;
VAL_ 2566838526 Function 127 "Reserved26" 126 "Reserved25" 125 "Reserved24" 124 "Reserved23" 123 "Reserved22" 122 "Reserved21" 121 "Reserved20" 120 "Reserved19" 119 "Reserved18" 118 "Reserved17" 117 "Reserved16" 116 "Reserved15" 115 "Reserved14" 114 "Reserved13" 113 "Reserved12" 112 "Reserved11" 111 "Reserved10" 110 "Reserved9" 109 "Reserved8" 108 "Reserved7" 107 "Reserved6" 106 "Reserved5" 105 "Reserved4" 104 "Reserved3" 103 "Reserved2" 102 "Reserved1" 101 "Reserved0" 42 "Water Pump Control" 41 "Lighting - Operator Controls" 40 "Seat Control" 39 "Ignition Control Module" 38 "Tire Pressure Control" 37 "Cab Controller" 36 "Pneumatic - System Controller" 35 "Suspension - System Controller" 34 "Hydraulic Pump Controller" 33 "System Monitor" 32 "Headway Controller" 31 "Propulsion Battery Charger" 30 "Management Computer" 29 "Virtual Terminal (In Cab)" 28 "Off Vehicle Gateway" 27 "Power TakeOff (Secondary or Front)" 26 "Body Controller" 25 "Network Interconnect ECU" 24 "Vehicle Security" 23 "Vehicle Navigation" 22 "Aerodynamic Control" 21 "Cab Climate Control" 20 "Trip Recorder" 19 "Instrument Cluster" 18 "Suspension - Drive Axle" 17 "Suspension - Steer Axle" 16 "Steering Controller" 15 "Fuel System" 14 "Cruise Control" 13 "Retarder - Driveline" 12 "Retarder - Engine" 11 "Brakes - Drive Axle" 10 "Brakes - Steer Axle" 9 "Brakes - System Controller" 8 "Axle - Drive" 7 "Axle - Steering" 6 "Power TakeOff - (Main or Rear)" 5 "Shift Control/Console" 4 "Battery Pack Monitor" 3 "Transmission" 2 "Electric Propulsion Control" 1 "Auxiliary Power Unit (APU)" 0 "Engine" 100 "Reserved100" 99 "Reserved99" 98 "Reserved98" 97 "Reserved97" 96 "Reserved96" 95 "Reserved95" 94 "Reserved94" 93 "Reserved93" 92 "Reserved92" 91 "Reserved91" 90 "Reserved90" 89 "Reserved89" 88 "Reserved88" 87 "Reserved87" 86 "Reserved86" 85 "Reserved85" 84 "Reserved84" 83 "Reserved83" 82 "Reserved82" 81 "Reserved81" 80 "Reserved80" 79 "Reserved79" 78 "Reserved78" 77 "Reserved77" 76 "Reserved76" 75 "Reserved75" 74 "Reserved74" 73 "Reserved73" 72 "Coolant Valve Controller" 71 "Transfer Case Control" 70 "Auxiliary Regeneration Device" 69 "Engine Emission Aftertreatement System" 68 "Aftertreatment system gas measurement" 67 "Electrical System Controller" 66 "I/O Controller" 65 "Gas Flow Measurement" 64 "Endurance Braking" 63 "Engine Valve Controller" 62 "On-Board Diagnostic Unit" 61 "File Server/Printer" 60 "Cab Display" 59 "Starter" 58 "Fan Drive Control" 57 "Steering Column Unit" 56 "Communications Unit, Radio" 55 "Communications Unit, Satellite" 54 "Communications Unit, Cellular" 53 "Alternator/Charging System" 52 "Chassis Controller" 51 "Forward-Looking Collision Warning System" 50 "Auxiliary Heater" 49 "Clutch/Converter Control" 48 "Ramp Control" 47 "Information System Controller" 46 "Oil Sensor Unit" 45 "Vehicle Dynamic Stability Control" 44 "Exhaust Emission Control" 43 "Transmission Display" ;
VAL_ 2566838526 VehicleSystem 0 "Non-specific System" 127 "Not Available" ;
VAL_ 2566838526 ManufacturerCode 252 "Sensor-Technik Wiedemann GmbH" 251 "German Agricultural Society" 250 "Kuhn Group" 249 "Schaltbau GmbH" 233 "Yacht Monitoring Solutions Inc." 232 "TSD Integrated Controls" 1863 "Thomas G. Faria Co." 1862 "Sanshin" 1861 "Vector CANtech" 1860 "MMP" 1859 "Kvasar AB" 1858 "Litton" 1857 "Simrad" 1856 "Trimble" 1855 "Furuno USA" 1854 "Northstar Technologies" 1853 "Japan Radio Co." 1852 "Navionics" 1851 "Raymarine" 1850 "Teleflex" 222 "Generac Power Systems, Inc." 221 "SiE" 220 "Beede Electrical Instrument Company, Inc." 219 "Cat OEM Solutions" 218 "Gits Manufacturing Company" 217 "RM Michaelides Software & Elektronik GmbH" 216 "Paneltronics Inc." 215 "Aetna Engineering/Fireboy-Xintex" 214 "MC elettronica Srl" 213 "CNH Belgium N.V." 212 "Sure Power Industries, Inc." 211 "DNA Group" 210 "Iteris, Inc." 209 "Bell Equip. Co. SA (PTY) LTD" 208 "Drew Technologies, Inc." 207 "Otto Engineering" 206 "port GmbH" 205 "SmarTire Systems Inc" 204 "The Morey Corporation" 203 "MILtronik GmbH" 202 "Curtis Instruments, Inc." 201 "Disenos y Tecnologia S.A." 200 "MGM Brakes" 199 "Actia Corp." 198 "Mystic Valley Communications" 197 "Mechron Power Systems" 196 "LEMKEN GmbH & Co. KG" 195 "General Engine Products" 194 "TriMark Corporation" 193 "Jeppesen Marine" 192 "Floscan" 191 "XATA Corporation" 190 "Hella KGaA Hueck & Co." 189 "QUALCOMM" 188 "EMP Corp." 187 "Air-Weigh" 186 "Altronic, Inc." 185 "Beede Electrical Instrument Company" 184 "EIA Electronics" 183 "KDS Controls, Inc." 182 "Vehicle Systems Engineering B.V." 181 "Coretronics, Inc." 180 "Smart Power Systems" 179 "TeeJet Technologies Denmark" 178 "Siemens VDO Automotive AG" 177 "Diagnostic System Associates" 176 "Moritz Aerospace" 175 "Veris Technologies, Inc." 174 "AB Volvo Penta" 173 "Ryeso, Inc." 172 "Yanmar Marine USA" 171 "Wachendorff Elektronik GmbH & Co. KG" 170 "Computronics Corporation Ltd." 169 "Marlin Technologies Inc." 168 "Xantrex" 167 "JLG Industries Inc." 166 "Phoenix International" 165 "CPAC Systems AB" 164 "DaimlerChrysler Off-Highway" 163 "BRP Inc." 162 "Axiomatic Technologies" 161 "Offshore Systems (UK) Limited" 160 "Nido" 159 "NTech Industries Inc." 158 "Firestone Industrial Products Company" 157 "ISSPRO Inc." 156 "ITT Industries - Cannon" 155 "Vetronix Corporation" 154 "Westerbeke Corporation" 153 "Woodward, Industrial Controls Division" 152 "Elobau Elektrobauelemente GmbH & Co. KG" 151 "Raven Industries Inc. - Flow Controls Division" 150 "Fleetguard" 149 "Holset" 148 "Blue Water Data, Inc." 147 "Nautibus Electronic GmbH" 146 "Maxima Technologies" 145 "MurCal Controls" 144 "Mercury Marine" 143 "W. Gmeiner GmbH & Co." 142 "TRW Automotive (Commercial Steering Systems)" 141 "Thales Navigation Ltd." 140 "Lowrance Electronics, Inc." 139 "Caterpillar Trimble Control Technologies (CTCT), LLC" 138 "Georg Fritzmeier GmbH & Co. KG" 137 "Maretron" 136 "Komatsu Ltd." 135 "Airmar Technology Corporation" 134 "Iris Technology Ltd." 133 "Bucher Schoerling GmbH" 132 "Mulag-Fahrzeugwerk" 131 "ITT Industries" 130 "Nido - Universal Machines B.V." 129 "OMNEX Control Systems, Inc." 128 "Gerhard Duecker GmbH & Co. KG" 127 "Holland USA" 126 "Driver Tech" 125 "Nevada Automotive Test Center" 124 "Hydac Electronic" 123 "Basler Electric" 122 "FG Wilson (Engineering) Limited" 121 "HED (Hydro Electronic Devices, Inc.)" 120 "RDS Technology Ltd." 119 "IntegriNautics" 118 "Intron GmbH" 117 "HUSCO International" 116 "BEELINE Technologies" 115 "NACCO Materials Handling Group, Inc." 114 "EControls, Inc." 113 "Stress-Tek, Inc." 112 "MECALAC" 111 "Maschinenfabrik Bernhard Krone GmbH" 110 "EPIQ Sensor-Nite" 109 "TeeJet Technologies Denmark0" 108 "WTK-Elecktronik GmbH" 107 "Grimme Landmaschinen GmbH & Co. KG" 106 "BAE Systems Controls, Inc." 105 "Kiepe Elektrik GmbH & Co. KG" 104 "Claas Selbstfahrende Erntemaschinen GmbH" 103 "Agrocom GmbH & Co. Agrarsystem KG" 102 "AGCO GmbH & Co." 101 "Sensoria" 100 "VDO Technik AG" 99 "International Transmissions Ltd (ITL)" 98 "Mueller-Elektronik GmbH & Co." 97 "Ag Leader Technology, Inc." 96 "Mech@tronic IT GmbH" 95 "Pacific Insight Electronics Corp." 94 "CNH Global N.V." 93 "Perkins Engines Company Ltd." 92 "Ag-Chem Equipment Co., Inc." 91 "BSG Bodensee Steuergeraete GmbH" 90 "Knorr-Bremse SfN GmbH" 89 "Kverneland Group, Electronics Division" 88 "Satloc Precision GPS" 87 "J.C. Bamford Excavators Ltd (JCB)" 86 "C.E. Niehoff & Company" 85 "Kohler Co." 84 "New Holland UK Limited" 83 "Eaton VORAD Technologies" 82 "Bobcat/Ingersoll-Rand" 81 "Fire Research Corp" 80 "Twin Disc, Inc." 79 "Daimler Benz AG - Engine Division (PBM)" 78 "Frank W. Murphy Manufacturing, Inc." 77 "Deere Power Systems Group" 76 "unused" 75 "Deere & Co. Agricultural Division" 74 "Eaton Axle-Brake Division" 73 "LeTourneau, Inc." 72 "Sisu Corporation" 71 "Vansco Electronics Ltd." 70 "Flex-Coil Limited" 69 "Trimble Navigation" 68 "Scania" 67 "Funk Manufacturing Company" 66 "John Deere Construction Equipment Division" 65 "MAN Nutzfahrzeuge AG" 64 "unused1" 63 "ZF Industries Inc." 62 "Wabco" 61 "Volvo Truck Corp." 60 "Volvo Trucks North America Inc." 59 "VES Inc." 58 "SPX Corporation, OTC Division" 57 "Sauer-Danfoss Co." 56 "SAIC" 55 "Ryder System Inc." 54 "Meritor Wabco" 53 "Continental Automotive Systems US, Inc." 52 "Meritor Automotive, Inc." 51 "Robert Bosch GmbH" 50 "Robert Bosch Corp" 49 "RE America Inc." 48 "Pollak Alphabet" 47 "Phillips Semiconductor" 46 "Parasoft Computing Solutions" 45 "PACCAR" 44 "Nippondenso Co. Ltd." 43 "International Truck and Engine Corp. Vehicle Electronics" 42 "International Truck and Engine Corp. Engine Electronics" 41 "Motorola Inc." 40 "Motorola AIEG Inc." 39 "Microfirm Inc." 38 "Micro Processor Systems Inc." 37 "Mack Trucks Inc." 36 "Lucas Ltd." 35 "Kenworth Truck Co." 34 "Kelsey Hayes Co." 33 "John Deere" 32 "Jacobs Vehicle Systems" 31 "J Pollak Corp." 30 "Isuzu Motors Ltd." 29 "Hino Motors Ltd." 28 "Grote Ind. Inc." 27 "GMC" 26 "General Motors Corp., Service Technology Group" 25 "Daimler Trucks North America LLC" 24 "Ford Motor Co., Vehicle Controls" 23 "Ford Motor Co., Heavy Truck" 22 "Ford Motor Co., Electronic Concepts $ Systems" 21 "Echilin Inc., Midland Brake Inc." 20 "Eaton Ltd" 19 "Eaton Corp. Trucking Info Services" 18 "Eaton Corp, Transmission Division" 17 "Eaton Corp. Res & Dev" 16 "Eaton Corp." 15 "Dickey-John Corp." 14 "Detroit Diesel Corporation" 13 "Delco Electronics" 12 "Deere & Company, Precision Farming" 11 "Dearborn Group Inc." 10 "Cummins Engine Co." 9 "Chrysler Corp." 8 "Caterpillar Inc." 7 "Case Corp." 6 "Berifors Electronics AB" 5 "AMP Inc." 4 "Ametek-Dixson" 3 "Ametek, US Gauge Division" 2 "Allison Transmission, GMC" 1 "Allied Signal Inc." 0 "Reserved" 231 "Topcon Positioning Systems, Inc." 230 "Saucon Technologies" 229 "Garmin International Inc." 228 "ZF Marine Electronics" 227 "Lykketronic A/S" 226 "Monaco Coach Corporation" 225 "SKF" 224 "EMMI Network, S.L." 223 "Vaueo Retarder Co., Ltd." 263 "IMMI" 262 "HydraForce, Inc" 261 "Red Dot Corporation" 260 "Reichhardt GmbH" 259 "Jetter AG" 258 "ARAG" 257 "Honda Motor Co., Ltd" 256 "Tyco Electronics AMP" 255 "MEAS France" 254 "GE Sensing" 253 "Mobile Control Systems" 298 "Holley Performance" 297 "Zonar Systems Inc" 296 "micro dynamics GmbH" 295 "BEP Marine" 294 "Grayhill Inc." 293 "Spyder Controls Corp." 292 "IKUSI - Angel Iglesias S.A." 291 "Groeneveld Transport Efficiency BV" 290 "Kuebler GmbH" 289 "Watlow" 288 "Mitsubishi FUSO Truck & Bus Corp." 287 "NTech Industries, Inc" 286 "Coelmo srl" 285 "Sea Recovery Corp" 284 "Mobile Tech Chile" 283 "CWF Hamilton & Co Ltd" 282 "Medallion Instrumentation Systems" 281 "Precision Governors LLC" 311 "Patrick Power Products" 310 "TECNORD srl" 309 "Krauss-Maffei Wegmann GmbH & Co. KG" 308 "Cyntrx" 307 "MAS Technologies" 306 "Sleipner Motor AB" 305 "NovAtel Inc" 304 "EmpirBus AB" 303 "CTS Corporation" 302 "Nissin Kogyo Co., LTD" 301 "Parker Hannifin (UK) Ltd FDE group" 300 "Systron Donner Automotive" 299 "Rauch Landmaschinen GmbH" 280 "Leica Geosystems Pty Ltd" 279 "Geometris LP" 278 "Takata Electronics" 277 "LHP Telematics" 276 "Aqua-Hot Heating Systems" 275 "Navico Egersund AS" 274 "LTW Technology Co., LTD" 273 "Active Research Limited" 272 "Gross Mechanical Laboratories, Inc" 327 "Sonceboz SA" 326 "Akron Brass Company" 325 "ASM Automation Sensorik Messtechnik GmbH" 324 "Snap-on Diagnostics" 323 "Mobileye Vision Technologies Ltd." 322 "MICHENKA s.r.o." 321 "Ultra Electronics, Electrics" 320 "Miedema Landbouwwerktuigenfabriek B.V." 319 "Cadec Global" 318 "SAT Plan" 317 "Navtronics Bvba" 316 "ITT Flow Control" 315 "Icom Incorporated" 314 "CSM GmbH" 313 "Ilmor Engineering, Inc" 312 "Lectronix, Inc." 271 "Cole Hersee" 270 "Tennant" 269 "Saft America Inc.,  Space & Defense Division" 268 "Accurate Technologies" 267 "Red Lion Controls, Inc" 266 "International Thermal Research Ltd" 265 "MTS Sensor Technologie GmbH" 264 "Autolync" 248 "Cooper Standard Automotive Active Systems Group" 247 "ePULSE" 246 "Class 1, Inc" 245 "Capstan Ag Systems, Inc." 244 "Techno-Matic" 243 "eRide, Inc." 242 "Kokusandenki Co. Ltd" 241 "Schneider Automation SAS " 240 "Vanair Mfg" 239 "May & Scofield Ltd" 238 "ZF Friedrichshafen AG" 237 "Agtron Enterprises Inc" 236 "Norac Systems International Inc" 235 "SailorMade Marine Telemetry - Tetra Technology Ltd." 234 "Mondial electronic GmbH" ;
VAL_ 2566838526 VehicleSystem5 127 "Not Available" 0 "Ind. Process Control Stationary" ;
VAL_ 2566838526 VehicleSystem4 100 "Deck/Cargo/Fishing equip. sys" 90 "Environmental (HVAC) Systems" 80 "Instrumentation/General Systems" 70 "Communications Systems" 60 "Navigation Systems" 50 "Propulsion Systems" 40 "Steering Systems" 30 "Power Mgmt and lighting systems" 25 "Gateway" 20 "Safety Systems" 10 "System Tools" 127 "Not Available" 0 "Non-specific System" ;
VAL_ 2566838526 VehicleSystem3 8 "Grader" 7 "Four Wheel Drive Loader" 6 "Forklift" 5 "Excavator" 4 "Crawler" 3 "Backhoe" 2 "Articulated Dump Truck" 1 "Skid Steer Loader" 127 "Not Available" 0 "Non-specific System" ;
VAL_ 2566838526 VehicleSystem2 16 "Skidder" 15 "Earth Work" 14 "Special Crops" 13 "Powered Auxiliary Device" 12 "Farm Yard Operations" 11 "Transport/Trailer" 10 "Irrigation" 9 "Forage" 8 "Root Harvesters" 7 "Harvesters" 6 "Sprayers" 5 "Fertilizers" 4 "Planters/Seeders" 3 "Secondary Tillage" 2 "Tillage" 1 "Tractor" 127 "Not Available" 0 "Non-specific System" ;
VAL_ 2566838526 VehicleSystem1 2 "Trailer" 1 "Tractor" 127 "Not Available" 0 "Non-specific System" ;
VAL_ 2565799678 IndustryGroup 6 "Reserved for SAE" 7 "Reserved for SAE0" 5 "IndustrialProcessCtrlStationary" 4 "Marine" 3 "Construction" 2 "Agricultural and Forestry" 1 "On-Highway" 0 "Global" ;
VAL_ 2565799678 Function 42 "Water Pump Control" 41 "Lighting - Operator Controls" 40 "Seat Control" 39 "Ignition Control Module" 38 "Tire Pressure Control" 37 "Cab Controller" 36 "Pneumatic - System Controller" 35 "Suspension - System Controller" 34 "Hydraulic Pump Controller" 33 "System Monitor" 32 "Headway Controller" 31 "Propulsion Battery Charger" 30 "Management Computer" 29 "Virtual Terminal (In Cab)" 28 "Off Vehicle Gateway" 27 "Power TakeOff (Secondary or Front)" 26 "Body Controller" 25 "Network Interconnect ECU" 24 "Vehicle Security" 23 "Vehicle Navigation" 22 "Aerodynamic Control" 21 "Cab Climate Control" 20 "Trip Recorder" 19 "Instrument Cluster" 18 "Suspension - Drive Axle" 17 "Suspension - Steer Axle" 16 "Steering Controller" 15 "Fuel System" 14 "Cruise Control" 13 "Retarder - Driveline" 12 "Retarder - Engine" 11 "Brakes - Drive Axle" 10 "Brakes - Steer Axle" 9 "Brakes - System Controller" 8 "Axle - Drive" 7 "Axle - Steering" 6 "Power TakeOff - (Main or Rear)" 5 "Shift Control/Console" 4 "Battery Pack Monitor" 3 "Transmission" 2 "Electric Propulsion Control" 1 "Auxiliary Power Unit (APU)" 0 "Engine" 72 "Coolant Valve Controller" 71 "Transfer Case Control" 70 "Auxiliary Regeneration Device" 69 "Engine Emission Aftertreatement System" 68 "Aftertreatment system gas measurement" 67 "Electrical System Controller" 66 "I/O Controller" 65 "Gas Flow Measurement" 64 "Endurance Braking" 63 "Engine Valve Controller" 62 "On-Board Diagnostic Unit" 61 "File Server/Printer" 60 "Cab Display" 59 "Starter" 58 "Fan Drive Control" 57 "Steering Column Unit" 56 "Communications Unit, Radio" 55 "Communications Unit, Satellite" 54 "Communications Unit, Cellular" 53 "Alternator/Charging System" 52 "Chassis Controller" 51 "Forward-Looking Collision Warning System" 50 "Auxiliary Heater" 49 "Clutch/Converter Control" 48 "Ramp Control" 47 "Information System Controller" 46 "Oil Sensor Unit" 45 "Vehicle Dynamic Stability Control" 44 "Exhaust Emission Control" 43 "Transmission Display" ;
VAL_ 2565799678 ManufacturerCode 252 "Sensor-Technik Wiedemann GmbH" 251 "German Agricultural Society" 250 "Kuhn Group" 249 "Schaltbau GmbH" 233 "Yacht Monitoring Solutions Inc." 232 "TSD Integrated Controls" 1863 "Thomas G. Faria Co." 1862 "Sanshin" 1861 "Vector CANtech" 1860 "MMP" 1859 "Kvasar AB" 1858 "Litton" 1857 "Simrad" 1856 "Trimble" 1855 "Furuno USA" 1854 "Northstar Technologies" 1853 "Japan Radio Co." 1852 "Navionics" 1851 "Raymarine" 1850 "Teleflex" 222 "Generac Power Systems, Inc." 221 "SiE" 220 "Beede Electrical Instrument Company, Inc." 219 "Cat OEM Solutions" 218 "Gits Manufacturing Company" 217 "RM Michaelides Software & Elektronik GmbH" 216 "Paneltronics Inc." 215 "Aetna Engineering/Fireboy-Xintex" 214 "MC elettronica Srl" 213 "CNH Belgium N.V." 212 "Sure Power Industries, Inc." 211 "DNA Group" 210 "Iteris, Inc." 209 "Bell Equip. Co. SA (PTY) LTD" 208 "Drew Technologies, Inc." 207 "Otto Engineering" 206 "port GmbH" 205 "SmarTire Systems Inc" 204 "The Morey Corporation" 203 "MILtronik GmbH" 202 "Curtis Instruments, Inc." 201 "Disenos y Tecnologia S.A." 200 "MGM Brakes" 199 "Actia Corp." 198 "Mystic Valley Communications" 197 "Mechron Power Systems" 196 "LEMKEN GmbH & Co. KG" 195 "General Engine Products" 194 "TriMark Corporation" 193 "Jeppesen Marine" 192 "Floscan" 191 "XATA Corporation" 190 "Hella KGaA Hueck & Co." 189 "QUALCOMM" 188 "EMP Corp." 187 "Air-Weigh" 186 "Altronic, Inc." 185 "Beede Electrical Instrument Company" 184 "EIA Electronics" 183 "KDS Controls, Inc." 182 "Vehicle Systems Engineering B.V." 181 "Coretronics, Inc." 180 "Smart Power Systems" 179 "TeeJet Technologies Denmark" 178 "Siemens VDO Automotive AG" 177 "Diagnostic System Associates" 176 "Moritz Aerospace" 175 "Veris Technologies, Inc." 174 "AB Volvo Penta" 173 "Ryeso, Inc." 172 "Yanmar Marine USA" 171 "Wachendorff Elektronik GmbH & Co. KG" 170 "Computronics Corporation Ltd." 169 "Marlin Technologies Inc." 168 "Xantrex" 167 "JLG Industries Inc." 166 "Phoenix International" 165 "CPAC Systems AB" 164 "DaimlerChrysler Off-Highway" 163 "BRP Inc." 162 "Axiomatic Technologies" 161 "Offshore Systems (UK) Limited" 160 "Nido" 159 "NTech Industries Inc." 158 "Firestone Industrial Products Company" 157 "ISSPRO Inc." 156 "ITT Industries - Cannon" 155 "Vetronix Corporation" 154 "Westerbeke Corporation" 153 "Woodward, Industrial Controls Division" 152 "Elobau Elektrobauelemente GmbH & Co. KG" 151 "Raven Industries Inc. - Flow Controls Division" 150 "Fleetguard" 149 "Holset" 148 "Blue Water Data, Inc." 147 "Nautibus Electronic GmbH" 146 "Maxima Technologies" 145 "MurCal Controls" 144 "Mercury Marine" 143 "W. Gmeiner GmbH & Co." 142 "TRW Automotive (Commercial Steering Systems)" 141 "Thales Navigation Ltd." 140 "Lowrance Electronics, Inc." 139 "Caterpillar Trimble Control Technologies (CTCT), LLC" 138 "Georg Fritzmeier GmbH & Co. KG" 137 "Maretron" 136 "Komatsu Ltd." 135 "Airmar Technology Corporation" 134 "Iris Technology Ltd." 133 "Bucher Schoerling GmbH" 132 "Mulag-Fahrzeugwerk" 131 "ITT Industries" 130 "Nido - Universal Machines B.V." 129 "OMNEX Control Systems, Inc." 128 "Gerhard Duecker GmbH & Co. KG" 127 "Holland USA" 126 "Driver Tech" 125 "Nevada Automotive Test Center" 124 "Hydac Electronic" 123 "Basler Electric" 122 "FG Wilson (Engineering) Limited" 121 "HED (Hydro Electronic Devices, Inc.)" 120 "RDS Technology Ltd." 119 "IntegriNautics" 118 "Intron GmbH" 117 "HUSCO International" 116 "BEELINE Technologies" 115 "NACCO Materials Handling Group, Inc." 114 "EControls, Inc." 113 "Stress-Tek, Inc." 112 "MECALAC" 111 "Maschinenfabrik Bernhard Krone GmbH" 110 "EPIQ Sensor-Nite" 109 "TeeJet Technologies Denmark0" 108 "WTK-Elecktronik GmbH" 107 "Grimme Landmaschinen GmbH & Co. KG" 106 "BAE Systems Controls, Inc." 105 "Kiepe Elektrik GmbH & Co. KG" 104 "Claas Selbstfahrende Erntemaschinen GmbH" 103 "Agrocom GmbH & Co. Agrarsystem KG" 102 "AGCO GmbH & Co." 101 "Sensoria" 100 "VDO Technik AG" 99 "International Transmissions Ltd (ITL)" 98 "Mueller-Elektronik GmbH & Co." 97 "Ag Leader Technology, Inc." 96 "Mech@tronic IT GmbH" 95 "Pacific Insight Electronics Corp." 94 "CNH Global N.V." 93 "Perkins Engines Company Ltd." 92 "Ag-Chem Equipment Co., Inc." 91 "BSG Bodensee Steuergeraete GmbH" 90 "Knorr-Bremse SfN GmbH" 89 "Kverneland Group, Electronics Division" 88 "Satloc Precision GPS" 87 "J.C. Bamford Excavators Ltd (JCB)" 86 "C.E. Niehoff & Company" 85 "Kohler Co." 84 "New Holland UK Limited" 83 "Eaton VORAD Technologies" 82 "Bobcat/Ingersoll-Rand" 81 "Fire Research Corp" 80 "Twin Disc, Inc." 79 "Daimler Benz AG - Engine Division (PBM)" 78 "Frank W. Murphy Manufacturing, Inc." 77 "Deere Power Systems Group" 76 "unused" 75 "Deere & Co. Agricultural Division" 74 "Eaton Axle-Brake Division" 73 "LeTourneau, Inc." 72 "Sisu Corporation" 71 "Vansco Electronics Ltd." 70 "Flex-Coil Limited" 69 "Trimble Navigation" 68 "Scania" 67 "Funk Manufacturing Company" 66 "John Deere Construction Equipment Division" 65 "MAN Nutzfahrzeuge AG" 64 "unused1" 63 "ZF Industries Inc." 62 "Wabco" 61 "Volvo Truck Corp." 60 "Volvo Trucks North America Inc." 59 "VES Inc." 58 "SPX Corporation, OTC Division" 57 "Sauer-Danfoss Co." 56 "SAIC" 55 "Ryder System Inc." 54 "Meritor Wabco" 53 "Continental Automotive Systems US, Inc." 52 "Meritor Automotive, Inc." 51 "Robert Bosch GmbH" 50 "Robert Bosch Corp" 49 "RE America Inc." 48 "Pollak Alphabet" 47 "Phillips Semiconductor" 46 "Parasoft Computing Solutions" 45 "PACCAR" 44 "Nippondenso Co. Ltd." 43 "International Truck and Engine Corp. Vehicle Electronics" 42 "International Truck and Engine Corp. Engine Electronics" 41 "Motorola Inc." 40 "Motorola AIEG Inc." 39 "Microfirm Inc." 38 "Micro Processor Systems Inc." 37 "Mack Trucks Inc." 36 "Lucas Ltd." 35 "Kenworth Truck Co." 34 "Kelsey Hayes Co." 33 "John Deere" 32 "Jacobs Vehicle Systems" 31 "J Pollak Corp." 30 "Isuzu Motors Ltd." 29 "Hino Motors Ltd." 28 "Grote Ind. Inc." 27 "GMC" 26 "General Motors Corp., Service Technology Group" 25 "Daimler Trucks North America LLC" 24 "Ford Motor Co., Vehicle Controls" 23 "Ford Motor Co., Heavy Truck" 22 "Ford Motor Co., Electronic Concepts $ Systems" 21 "Echilin Inc., Midland Brake Inc." 20 "Eaton Ltd" 19 "Eaton Corp. Trucking Info Services" 18 "Eaton Corp, Transmission Division" 17 "Eaton Corp. Res & Dev" 16 "Eaton Corp." 15 "Dickey-John Corp." 14 "Detroit Diesel Corporation" 13 "Delco Electronics" 12 "Deere & Company, Precision Farming" 11 "Dearborn Group Inc." 10 "Cummins Engine Co." 9 "Chrysler Corp." 8 "Caterpillar Inc." 7 "Case Corp." 6 "Berifors Electronics AB" 5 "AMP Inc." 4 "Ametek-Dixson" 3 "Ametek, US Gauge Division" 2 "Allison Transmission, GMC" 1 "Allied Signal Inc." 0 "Reserved" 231 "Topcon Positioning Systems, Inc." 230 "Saucon Technologies" 229 "Garmin International Inc." 228 "ZF Marine Electronics" 227 "Lykketronic A/S" 226 "Monaco Coach Corporation" 225 "SKF" 224 "EMMI Network, S.L." 223 "Vaueo Retarder Co., Ltd." 263 "IMMI" 262 "HydraForce, Inc" 261 "Red Dot Corporation" 260 "Reichhardt GmbH" 259 "Jetter AG" 258 "ARAG" 257 "Honda Motor Co., Ltd" 256 "Tyco Electronics AMP" 255 "MEAS France" 254 "GE Sensing" 253 "Mobile Control Systems" 298 "Holley Performance" 297 "Zonar Systems Inc" 296 "micro dynamics GmbH" 295 "BEP Marine" 294 "Grayhill Inc." 293 "Spyder Controls Corp." 292 "IKUSI - Angel Iglesias S.A." 291 "Groeneveld Transport Efficiency BV" 290 "Kuebler GmbH" 289 "Watlow" 288 "Mitsubishi FUSO Truck & Bus Corp." 287 "NTech Industries, Inc" 286 "Coelmo srl" 285 "Sea Recovery Corp" 284 "Mobile Tech Chile" 283 "CWF Hamilton & Co Ltd" 282 "Medallion Instrumentation Systems" 281 "Precision Governors LLC" 311 "Patrick Power Products" 310 "TECNORD srl" 309 "Krauss-Maffei Wegmann GmbH & Co. KG" 308 "Cyntrx" 307 "MAS Technologies" 306 "Sleipner Motor AB" 305 "NovAtel Inc" 304 "EmpirBus AB" 303 "CTS Corporation" 302 "Nissin Kogyo Co., LTD" 301 "Parker Hannifin (UK) Ltd FDE group" 300 "Systron Donner Automotive" 299 "Rauch Landmaschinen GmbH" 280 "Leica Geosystems Pty Ltd" 279 "Geometris LP" 278 "Takata Electronics" 277 "LHP Telematics" 276 "Aqua-Hot Heating Systems" 275 "Navico Egersund AS" 274 "LTW Technology Co., LTD" 273 "Active Research Limited" 272 "Gross Mechanical Laboratories, Inc" 327 "Sonceboz SA" 326 "Akron Brass Company" 325 "ASM Automation Sensorik Messtechnik GmbH" 324 "Snap-on Diagnostics" 323 "Mobileye Vision Technologies Ltd." 322 "MICHENKA s.r.o." 321 "Ultra Electronics, Electrics" 320 "Miedema Landbouwwerktuigenfabriek B.V." 319 "Cadec Global" 318 "SAT Plan" 317 "Navtronics Bvba" 316 "ITT Flow Control" 315 "Icom Incorporated" 314 "CSM GmbH" 313 "Ilmor Engineering, Inc" 312 "Lectronix, Inc." 271 "Cole Hersee" 270 "Tennant" 269 "Saft America Inc.,  Space & Defense Division" 268 "Accurate Technologies" 267 "Red Lion Controls, Inc" 266 "International Thermal Research Ltd" 265 "MTS Sensor Technologie GmbH" 264 "Autolync" 248 "Cooper Standard Automotive Active Systems Group" 247 "ePULSE" 246 "Class 1, Inc" 245 "Capstan Ag Systems, Inc." 244 "Techno-Matic" 243 "eRide, Inc." 242 "Kokusandenki Co. Ltd" 241 "Schneider Automation SAS " 240 "Vanair Mfg" 239 "May & Scofield Ltd" 238 "ZF Friedrichshafen AG" 237 "Agtron Enterprises Inc" 236 "Norac Systems International Inc" 235 "SailorMade Marine Telemetry - Tetra Technology Ltd." 234 "Mondial electronic GmbH" ;
VAL_ 2565799678 VehicleSystem 0 "Non-specific System" 127 "Not Available" ;
VAL_ 2565799678 VehicleSystem5 127 "Not Available" 0 "Ind. Process Control Stationary" ;
VAL_ 2565799678 VehicleSystem4 100 "Deck/Cargo/Fishing equip. sys" 90 "Environmental (HVAC) Systems" 80 "Instrumentation/General Systems" 70 "Communications Systems" 60 "Navigation Systems" 50 "Propulsion Systems" 40 "Steering Systems" 30 "Power Mgmt and lighting systems" 25 "Gateway" 20 "Safety Systems" 10 "System Tools" 127 "Not Available" 0 "Non-specific System" ;
VAL_ 2565799678 VehicleSystem3 8 "Grader" 7 "Four Wheel Drive Loader" 6 "Forklift" 5 "Excavator" 4 "Crawler" 3 "Backhoe" 2 "Articulated Dump Truck" 1 "Skid Steer Loader" 127 "Not Available" 0 "Non-specific System" ;
VAL_ 2565799678 VehicleSystem2 16 "Skidder" 15 "Earth Work" 14 "Special Crops" 13 "Powered Auxiliary Device" 12 "Farm Yard Operations" 11 "Transport/Trailer" 10 "Irrigation" 9 "Forage" 8 "Root Harvesters" 7 "Harvesters" 6 "Sprayers" 5 "Fertilizers" 4 "Planters/Seeders" 3 "Secondary Tillage" 2 "Tillage" 1 "Tractor" 127 "Not Available" 0 "Non-specific System" ;
VAL_ 2565799678 VehicleSystem1 2 "Trailer" 1 "Tractor" 127 "Not Available" 0 "Non-specific System" ;
VAL_ 2566739198 FlashRedStopLamp 3 "Unavailable / Do Not Flash" 2 "Reserved" 1 "Fast Flash" 0 "Slow Flash" ;
VAL_ 2566739198 FlashProtectLamp 3 "Unavailable / Do Not Flash" 2 "Reserved" 1 "Fast Flash" 0 "Slow Flash" ;
VAL_ 2566739198 FlashMalfuncIndicatorLamp 3 "Unavailable / Do Not Flash" 2 "Reserved" 1 "Fast Flash" 0 "Slow Flash" ;
VAL_ 2566739198 FlashAmberWarningLamp 3 "Unavailable / Do Not Flash" 2 "Reserved" 1 "Fast Flash" 0 "Slow Flash" ;
VAL_ 2566739198 MalfunctionIndicatorLampStatus 3 "Not available" 2 "Reserved" 1 "Lamp on" 0 "Lamp off" ;
VAL_ 2566739198 AmberWarningLampStatus 3 "Not available" 2 "Reserved" 1 "Lamp on" 0 "Lamp off" ;
VAL_ 2566739198 RedStopLampState 3 "Not available" 2 "Reserved" 1 "Lamp on" 0 "Lamp off" ;
VAL_ 2566739198 ProtectLampStatus 3 "Not available" 2 "Reserved" 1 "Lamp on" 0 "Lamp off" ;
VAL_ 2566739454 FlashRedStopLamp 3 "Unavailable / Do Not Flash" 2 "Reserved" 1 "Fast Flash" 0 "Slow Flash" ;
VAL_ 2566739454 FlashProtectLamp 3 "Unavailable / Do Not Flash" 2 "Reserved" 1 "Fast Flash" 0 "Slow Flash" ;
VAL_ 2566739454 FlashMalfuncIndicatorLamp 3 "Unavailable / Do Not Flash" 2 "Reserved" 1 "Fast Flash" 0 "Slow Flash" ;
VAL_ 2566739454 FlashAmberWarningLamp 3 "Unavailable / Do Not Flash" 2 "Reserved" 1 "Fast Flash" 0 "Slow Flash" ;
VAL_ 2566739454 MalfunctionIndicatorLampStatus 3 "Not available" 2 "Reserved" 1 "Lamp on" 0 "Lamp off" ;
VAL_ 2566739454 AmberWarningLampStatus 3 "Not available" 2 "Reserved" 1 "Lamp on" 0 "Lamp off" ;
VAL_ 2566739454 RedStopLampState 3 "Not available" 2 "Reserved" 1 "Lamp on" 0 "Lamp off" ;
VAL_ 2566739454 ProtectLampStatus 3 "Not available" 2 "Reserved" 1 "Lamp on" 0 "Lamp off" ;
VAL_ 2566739710 FlashRedStopLamp 3 "Unavailable / Do Not Flash" 2 "Reserved" 1 "Fast Flash" 0 "Slow Flash" ;
VAL_ 2566739710 FlashProtectLamp 3 "Unavailable / Do Not Flash" 2 "Reserved" 1 "Fast Flash" 0 "Slow Flash" ;
VAL_ 2566739710 FlashMalfuncIndicatorLamp 3 "Unavailable / Do Not Flash" 2 "Reserved" 1 "Fast Flash" 0 "Slow Flash" ;
VAL_ 2566739710 FlashAmberWarningLamp 3 "Unavailable / Do Not Flash" 2 "Reserved" 1 "Fast Flash" 0 "Slow Flash" ;
VAL_ 2566739710 MalfunctionIndicatorLampStatus 3 "Not available" 2 "Reserved" 1 "Lamp on" 0 "Lamp off" ;
VAL_ 2566739710 AmberWarningLampStatus 3 "Not available" 2 "Reserved" 1 "Lamp on" 0 "Lamp off" ;
VAL_ 2566739710 RedStopLampState 3 "Not available" 2 "Reserved" 1 "Lamp on" 0 "Lamp off" ;
VAL_ 2566739710 ProtectLampStatus 3 "Not available" 2 "Reserved" 1 "Lamp on" 0 "Lamp off" ;
VAL_ 2566739966 FlashRedStopLamp 3 "Unavailable / Do Not Flash" 2 "Reserved" 1 "Fast Flash" 0 "Slow Flash" ;
VAL_ 2566739966 FlashProtectLamp 3 "Unavailable / Do Not Flash" 2 "Reserved" 1 "Fast Flash" 0 "Slow Flash" ;
VAL_ 2566739966 FlashMalfuncIndicatorLamp 3 "Unavailable / Do Not Flash" 2 "Reserved" 1 "Fast Flash" 0 "Slow Flash" ;
VAL_ 2566739966 FlashAmberWarningLamp 3 "Unavailable / Do Not Flash" 2 "Reserved" 1 "Fast Flash" 0 "Slow Flash" ;
VAL_ 2566739966 MalfunctionIndicatorLampStatus 3 "Not available" 2 "Reserved" 1 "Lamp on" 0 "Lamp off" ;
VAL_ 2566739966 AmberWarningLampStatus 3 "Not available" 2 "Reserved" 1 "Lamp on" 0 "Lamp off" ;
VAL_ 2566739966 RedStopLampState 3 "Not available" 2 "Reserved" 1 "Lamp on" 0 "Lamp off" ;
VAL_ 2566739966 ProtectLampStatus 3 "Not available" 2 "Reserved" 1 "Lamp on" 0 "Lamp off" ;
VAL_ 2566740222 FlashRedStopLamp 3 "Unavailable / Do Not Flash" 2 "Reserved" 1 "Fast Flash" 0 "Slow Flash" ;
VAL_ 2566740222 FlashProtectLamp 3 "Unavailable / Do Not Flash" 2 "Reserved" 1 "Fast Flash" 0 "Slow Flash" ;
VAL_ 2566740222 FlashMalfuncIndicatorLamp 3 "Unavailable / Do Not Flash" 2 "Reserved" 1 "Fast Flash" 0 "Slow Flash" ;
VAL_ 2566740222 FlashAmberWarningLamp 3 "Unavailable / Do Not Flash" 2 "Reserved" 1 "Fast Flash" 0 "Slow Flash" ;
VAL_ 2566740222 MalfunctionIndicatorLampStatus 3 "Not available" 2 "Reserved" 1 "Lamp on" 0 "Lamp off" ;
VAL_ 2566740222 AmberWarningLampStatus 3 "Not available" 2 "Reserved" 1 "Lamp on" 0 "Lamp off" ;
VAL_ 2566740222 RedStopLampState 3 "Not available" 2 "Reserved" 1 "Lamp on" 0 "Lamp off" ;
VAL_ 2566740222 ProtectLampStatus 3 "Not available" 2 "Reserved" 1 "Lamp on" 0 "Lamp off" ;
VAL_ 2566740478 FlashRedStopLamp 3 "Unavailable / Do Not Flash" 2 "Reserved" 1 "Fast Flash" 0 "Slow Flash" ;
VAL_ 2566740478 FlashProtectLamp 3 "Unavailable / Do Not Flash" 2 "Reserved" 1 "Fast Flash" 0 "Slow Flash" ;
VAL_ 2566740478 FlashMalfuncIndicatorLamp 3 "Unavailable / Do Not Flash" 2 "Reserved" 1 "Fast Flash" 0 "Slow Flash" ;
VAL_ 2566740478 FlashAmberWarningLamp 3 "Unavailable / Do Not Flash" 2 "Reserved" 1 "Fast Flash" 0 "Slow Flash" ;
VAL_ 2566740478 MalfunctionIndicatorLampStatus 3 "Not available" 2 "Reserved" 1 "Lamp on" 0 "Lamp off" ;
VAL_ 2566740478 AmberWarningLampStatus 3 "Not available" 2 "Reserved" 1 "Lamp on" 0 "Lamp off" ;
VAL_ 2566740478 RedStopLampState 3 "Not available" 2 "Reserved" 1 "Lamp on" 0 "Lamp off" ;
VAL_ 2566740478 ProtectLampStatus 3 "Not available" 2 "Reserved" 1 "Lamp on" 0 "Lamp off" ;
VAL_ 2566740734 FlashRedStopLamp 3 "Unavailable / Do Not Flash" 2 "Reserved" 1 "Fast Flash" 0 "Slow Flash" ;
VAL_ 2566740734 FlashProtectLamp 3 "Unavailable / Do Not Flash" 2 "Reserved" 1 "Fast Flash" 0 "Slow Flash" ;
VAL_ 2566740734 FlashMalfuncIndicatorLamp 3 "Unavailable / Do Not Flash" 2 "Reserved" 1 "Fast Flash" 0 "Slow Flash" ;
VAL_ 2566740734 FlashAmberWarningLamp 3 "Unavailable / Do Not Flash" 2 "Reserved" 1 "Fast Flash" 0 "Slow Flash" ;
VAL_ 2566740734 MalfunctionIndicatorLampStatus 3 "Not available" 2 "Reserved" 1 "Lamp on" 0 "Lamp off" ;
VAL_ 2566740734 AmberWarningLampStatus 3 "Not available" 2 "Reserved" 1 "Lamp on" 0 "Lamp off" ;
VAL_ 2566740734 RedStopLampState 3 "Not available" 2 "Reserved" 1 "Lamp on" 0 "Lamp off" ;
VAL_ 2566740734 ProtectLampStatus 3 "Not available" 2 "Reserved" 1 "Lamp on" 0 "Lamp off" ;
VAL_ 2566740990 FlashRedStopLamp 3 "Unavailable / Do Not Flash" 2 "Reserved" 1 "Fast Flash" 0 "Slow Flash" ;
VAL_ 2566740990 FlashProtectLamp 3 "Unavailable / Do Not Flash" 2 "Reserved" 1 "Fast Flash" 0 "Slow Flash" ;
VAL_ 2566740990 FlashMalfuncIndicatorLamp 3 "Unavailable / Do Not Flash" 2 "Reserved" 1 "Fast Flash" 0 "Slow Flash" ;
VAL_ 2566740990 FlashAmberWarningLamp 3 "Unavailable / Do Not Flash" 2 "Reserved" 1 "Fast Flash" 0 "Slow Flash" ;
VAL_ 2566740990 MalfunctionIndicatorLampStatus 3 "Not available" 2 "Reserved" 1 "Lamp on" 0 "Lamp off" ;
VAL_ 2566740990 AmberWarningLampStatus 3 "Not available" 2 "Reserved" 1 "Lamp on" 0 "Lamp off" ;
VAL_ 2566740990 RedStopLampState 3 "Not available" 2 "Reserved" 1 "Lamp on" 0 "Lamp off" ;
VAL_ 2566740990 ProtectLampStatus 3 "Not available" 2 "Reserved" 1 "Lamp on" 0 "Lamp off" ;
VAL_ 2566741246 FlashRedStopLamp 3 "Unavailable / Do Not Flash" 2 "Reserved" 1 "Fast Flash" 0 "Slow Flash" ;
VAL_ 2566741246 FlashProtectLamp 3 "Unavailable / Do Not Flash" 2 "Reserved" 1 "Fast Flash" 0 "Slow Flash" ;
VAL_ 2566741246 FlashMalfuncIndicatorLamp 3 "Unavailable / Do Not Flash" 2 "Reserved" 1 "Fast Flash" 0 "Slow Flash" ;
VAL_ 2566741246 FlashAmberWarningLamp 3 "Unavailable / Do Not Flash" 2 "Reserved" 1 "Fast Flash" 0 "Slow Flash" ;
VAL_ 2566741246 MalfunctionIndicatorLampStatus 3 "Not available" 2 "Reserved" 1 "Lamp on" 0 "Lamp off" ;
VAL_ 2566741246 AmberWarningLampStatus 3 "Not available" 2 "Reserved" 1 "Lamp on" 0 "Lamp off" ;
VAL_ 2566741246 RedStopLampState 3 "Not available" 2 "Reserved" 1 "Lamp on" 0 "Lamp off" ;
VAL_ 2566741246 ProtectLampStatus 3 "Not available" 2 "Reserved" 1 "Lamp on" 0 "Lamp off" ;
VAL_ 2566741502 FlashRedStopLamp 3 "Unavailable / Do Not Flash" 2 "Reserved" 1 "Fast Flash" 0 "Slow Flash" ;
VAL_ 2566741502 FlashProtectLamp 3 "Unavailable / Do Not Flash" 2 "Reserved" 1 "Fast Flash" 0 "Slow Flash" ;
VAL_ 2566741502 FlashMalfuncIndicatorLamp 3 "Unavailable / Do Not Flash" 2 "Reserved" 1 "Fast Flash" 0 "Slow Flash" ;
VAL_ 2566741502 FlashAmberWarningLamp 3 "Unavailable / Do Not Flash" 2 "Reserved" 1 "Fast Flash" 0 "Slow Flash" ;
VAL_ 2566741502 MalfunctionIndicatorLampStatus 3 "Not available" 2 "Reserved" 1 "Lamp on" 0 "Lamp off" ;
VAL_ 2566741502 AmberWarningLampStatus 3 "Not available" 2 "Reserved" 1 "Lamp on" 0 "Lamp off" ;
VAL_ 2566741502 RedStopLampState 3 "Not available" 2 "Reserved" 1 "Lamp on" 0 "Lamp off" ;
VAL_ 2566741502 ProtectLampStatus 3 "Not available" 2 "Reserved" 1 "Lamp on" 0 "Lamp off" ;
VAL_ 2566741758 FlashRedStopLamp 3 "Unavailable / Do Not Flash" 2 "Reserved" 1 "Fast Flash" 0 "Slow Flash" ;
VAL_ 2566741758 FlashProtectLamp 3 "Unavailable / Do Not Flash" 2 "Reserved" 1 "Fast Flash" 0 "Slow Flash" ;
VAL_ 2566741758 FlashMalfuncIndicatorLamp 3 "Unavailable / Do Not Flash" 2 "Reserved" 1 "Fast Flash" 0 "Slow Flash" ;
VAL_ 2566741758 FlashAmberWarningLamp 3 "Unavailable / Do Not Flash" 2 "Reserved" 1 "Fast Flash" 0 "Slow Flash" ;
VAL_ 2566741758 MalfunctionIndicatorLampStatus 3 "Not available" 2 "Reserved" 1 "Lamp on" 0 "Lamp off" ;
VAL_ 2566741758 AmberWarningLampStatus 3 "Not available" 2 "Reserved" 1 "Lamp on" 0 "Lamp off" ;
VAL_ 2566741758 RedStopLampState 3 "Not available" 2 "Reserved" 1 "Lamp on" 0 "Lamp off" ;
VAL_ 2566741758 ProtectLampStatus 3 "Not available" 2 "Reserved" 1 "Lamp on" 0 "Lamp off" ;
VAL_ 2566742014 FlashRedStopLamp 3 "Unavailable / Do Not Flash" 2 "Reserved" 1 "Fast Flash" 0 "Slow Flash" ;
VAL_ 2566742014 FlashProtectLamp 3 "Unavailable / Do Not Flash" 2 "Reserved" 1 "Fast Flash" 0 "Slow Flash" ;
VAL_ 2566742014 FlashMalfuncIndicatorLamp 3 "Unavailable / Do Not Flash" 2 "Reserved" 1 "Fast Flash" 0 "Slow Flash" ;
VAL_ 2566742014 FlashAmberWarningLamp 3 "Unavailable / Do Not Flash" 2 "Reserved" 1 "Fast Flash" 0 "Slow Flash" ;
VAL_ 2566742014 MalfunctionIndicatorLampStatus 3 "Not available" 2 "Reserved" 1 "Lamp on" 0 "Lamp off" ;
VAL_ 2566742014 AmberWarningLampStatus 3 "Not available" 2 "Reserved" 1 "Lamp on" 0 "Lamp off" ;
VAL_ 2566742014 RedStopLampState 3 "Not available" 2 "Reserved" 1 "Lamp on" 0 "Lamp off" ;
VAL_ 2566742014 ProtectLampStatus 3 "Not available" 2 "Reserved" 1 "Lamp on" 0 "Lamp off" ;
VAL_ 2560622334 FlashRedStopLamp 3 "Unavailable / Do Not Flash" 2 "Reserved" 1 "Fast Flash" 0 "Slow Flash" ;
VAL_ 2560622334 FlashProtectLamp 3 "Unavailable / Do Not Flash" 2 "Reserved" 1 "Fast Flash" 0 "Slow Flash" ;
VAL_ 2560622334 FlashMalfuncIndicatorLamp 3 "Unavailable / Do Not Flash" 2 "Reserved" 1 "Fast Flash" 0 "Slow Flash" ;
VAL_ 2560622334 FlashAmberWarningLamp 3 "Unavailable / Do Not Flash" 2 "Reserved" 1 "Fast Flash" 0 "Slow Flash" ;
VAL_ 2560622334 MalfunctionIndicatorLampStatus 3 "Not available" 2 "Reserved" 1 "Lamp on" 0 "Lamp off" ;
VAL_ 2560622334 AmberWarningLampStatus 3 "Not available" 2 "Reserved" 1 "Lamp on" 0 "Lamp off" ;
VAL_ 2560622334 RedStopLampState 3 "Not available" 2 "Reserved" 1 "Lamp on" 0 "Lamp off" ;
VAL_ 2560622334 ProtectLampStatus 3 "Not available" 2 "Reserved" 1 "Lamp on" 0 "Lamp off" ;
VAL_ 2566750462 FlashRedStopLamp 3 "Unavailable / Do Not Flash" 2 "Reserved" 1 "Fast Flash" 0 "Slow Flash" ;
VAL_ 2566750462 FlashProtectLamp 3 "Unavailable / Do Not Flash" 2 "Reserved" 1 "Fast Flash" 0 "Slow Flash" ;
VAL_ 2566750462 FlashMalfuncIndicatorLamp 3 "Unavailable / Do Not Flash" 2 "Reserved" 1 "Fast Flash" 0 "Slow Flash" ;
VAL_ 2566750462 FlashAmberWarningLamp 3 "Unavailable / Do Not Flash" 2 "Reserved" 1 "Fast Flash" 0 "Slow Flash" ;
VAL_ 2566750462 MalfunctionIndicatorLampStatus 3 "Not available" 2 "Reserved" 1 "Lamp on" 0 "Lamp off" ;
VAL_ 2566750462 AmberWarningLampStatus 3 "Not available" 2 "Reserved" 1 "Lamp on" 0 "Lamp off" ;
VAL_ 2566750462 RedStopLampState 3 "Not available" 2 "Reserved" 1 "Lamp on" 0 "Lamp off" ;
VAL_ 2566750462 ProtectLampStatus 3 "Not available" 2 "Reserved" 1 "Lamp on" 0 "Lamp off" ;
VAL_ 2566750974 FlashRedStopLamp 3 "Unavailable / Do Not Flash" 2 "Reserved" 1 "Fast Flash" 0 "Slow Flash" ;
VAL_ 2566750974 FlashProtectLamp 3 "Unavailable / Do Not Flash" 2 "Reserved" 1 "Fast Flash" 0 "Slow Flash" ;
VAL_ 2566750974 FlashMalfuncIndicatorLamp 3 "Unavailable / Do Not Flash" 2 "Reserved" 1 "Fast Flash" 0 "Slow Flash" ;
VAL_ 2566750974 FlashAmberWarningLamp 3 "Unavailable / Do Not Flash" 2 "Reserved" 1 "Fast Flash" 0 "Slow Flash" ;
VAL_ 2566750974 MalfunctionIndicatorLampStatus 3 "Not available" 2 "Reserved" 1 "Lamp on" 0 "Lamp off" ;
VAL_ 2566750974 AmberWarningLampStatus 3 "Not available" 2 "Reserved" 1 "Lamp on" 0 "Lamp off" ;
VAL_ 2566750974 RedStopLampState 3 "Not available" 2 "Reserved" 1 "Lamp on" 0 "Lamp off" ;
VAL_ 2566750974 ProtectLampStatus 3 "Not available" 2 "Reserved" 1 "Lamp on" 0 "Lamp off" ;
VAL_ 2565406462 ControlByte 3 "CannotRespond" 2 "AccessDenied" 1 "NACK" 0 "ACK" ;
VAL_ 2633869310 VoltageRegulatorEnabled 3 "NotAvailable" 2 "Error" 1 "RegulatingVoltage" 0 "NtRegulatingVoltageUnitDisabled" ;
VAL_ 2633869310 VoltageRegulatorSoftStartState 3 "NotAvailable" 2 "Error" 1 "SoftStartIsActive" 0 "SoftStartIsInactive" ;
VAL_ 2633869310 VltgRgltrUndrfrqncyCmpnstnEnbld 3 "NotAvailable" 2 "Error" 1 "UndrfrquencyCompensationEnabled" 0 "UndrfrqencyCompensationDisabled" ;
VAL_ 2633869310 VltgRgltrVAr_PwrFctrOprtingMode 7 "NotAvailable" 6 "Error" 5 "Reserved" 2 "VArRegulationEnabled" 1 "PowerFactorRegulationEnabled" 0 "VAr_PwrFactorRegulationDisabled" ;
VAL_ 2633869310 VltgRglatorLoadCompensationMode 7 "NotAvailable" 6 "Error" 5 "Reserved" 2 "IRLineDropCompensationEnabled" 1 "VoltageDroopCompensationEnabled" 0 "LoadCompensationDisabled" ;
